VERSION ""

NS_ :

BS_:

BU_: External_Tool IPMA_ADAS SODRR SODRL

BO_ 776 RL_Detection_057_063: 64 SODRL
 SG_ RL_CAN_DET_ELEVATION_057 : 63|7@0+ (0.157449,-9.99812) [-9.99812|9.997903] "deg"  IPMA_ADAS
 SG_ RL_CAN_DET_CONFID_AZIMUTH_057 : 33|2@0+ (1,0) [0|3] ""  IPMA_ADAS
 SG_ RL_CAN_DET_SUPER_RES_TARGET_057 : 56|1@0+ (1,0) [0|1] ""  IPMA_ADAS
 SG_ RL_CAN_DET_CONFID_ELEVATION_057 : 49|1@0+ (1,0) [0|1] ""  IPMA_ADAS
 SG_ RL_CAN_DET_HOST_VEH_CLUTTER_057 : 48|1@0+ (1,0) [0|1] ""  IPMA_ADAS
 SG_ RL_CAN_DET_VALID_LEVEL_057 : 0|1@0+ (1,0) [0|1] ""  IPMA_ADAS
 SG_ RL_CAN_DET_AZIMUTH_057 : 47|14@0+ (0.021967,-180) [-180|179.885361] "deg"  IPMA_ADAS
 SG_ RL_CAN_DET_RANGE_057 : 31|14@0+ (0.015625,0) [0|255.984375] "m"  IPMA_ADAS
 SG_ RL_CAN_DET_RANGE_RATE_057 : 15|14@0+ (0.015625,-128) [-128|127.984375] "m/s"  IPMA_ADAS
 SG_ RL_CAN_DET_AMPLITUDE_057 : 7|7@0+ (1,-64) [-64|63] "dBsm"  IPMA_ADAS
 SG_ RL_CAN_SCAN_INDEX_2LSB_057 : 17|2@0+ (1,0) [0|3] ""  IPMA_ADAS
 SG_ RL_DET_MC_009 : 451|4@0+ (1,0) [0|0] ""  IPMA_ADAS
 SG_ RL_DET_CRC_009 : 463|16@0+ (1,0) [0|0] ""  IPMA_ADAS
 SG_ RL_CAN_DET_ELEVATION_063 : 447|7@0+ (0.157449,-9.99812) [-9.99812|9.997903] "deg"  IPMA_ADAS
 SG_ RL_CAN_DET_SUPER_RES_TARGET_063 : 440|1@0+ (1,0) [0|1] ""  IPMA_ADAS
 SG_ RL_CAN_DET_AZIMUTH_063 : 431|14@0+ (0.021967,-180) [-180|179.885361] "deg"  IPMA_ADAS
 SG_ RL_CAN_DET_CONFID_ELEVATION_063 : 433|1@0+ (1,0) [0|1] ""  IPMA_ADAS
 SG_ RL_CAN_DET_HOST_VEH_CLUTTER_063 : 432|1@0+ (1,0) [0|1] ""  IPMA_ADAS
 SG_ RL_CAN_DET_RANGE_063 : 415|14@0+ (0.015625,0) [0|255.984375] "m"  IPMA_ADAS
 SG_ RL_CAN_DET_CONFID_AZIMUTH_063 : 417|2@0+ (1,0) [0|3] ""  IPMA_ADAS
 SG_ RL_CAN_DET_RANGE_RATE_063 : 399|14@0+ (0.015625,-128) [-128|127.984375] "m/s"  IPMA_ADAS
 SG_ RL_CAN_SCAN_INDEX_2LSB_063 : 401|2@0+ (1,0) [0|3] ""  IPMA_ADAS
 SG_ RL_CAN_DET_AMPLITUDE_063 : 391|7@0+ (1,-64) [-64|63] "dBsm"  IPMA_ADAS
 SG_ RL_CAN_DET_VALID_LEVEL_063 : 384|1@0+ (1,0) [0|1] ""  IPMA_ADAS
 SG_ RL_CAN_DET_ELEVATION_062 : 383|7@0+ (0.157449,-9.99812) [-9.99812|9.997903] "deg"  IPMA_ADAS
 SG_ RL_CAN_DET_SUPER_RES_TARGET_062 : 376|1@0+ (1,0) [0|1] ""  IPMA_ADAS
 SG_ RL_CAN_DET_AZIMUTH_062 : 367|14@0+ (0.021967,-180) [-180|179.885361] "deg"  IPMA_ADAS
 SG_ RL_CAN_DET_CONFID_ELEVATION_062 : 369|1@0+ (1,0) [0|1] ""  IPMA_ADAS
 SG_ RL_CAN_DET_HOST_VEH_CLUTTER_062 : 368|1@0+ (1,0) [0|1] ""  IPMA_ADAS
 SG_ RL_CAN_DET_RANGE_062 : 351|14@0+ (0.015625,0) [0|255.984375] "m"  IPMA_ADAS
 SG_ RL_CAN_DET_CONFID_AZIMUTH_062 : 353|2@0+ (1,0) [0|3] ""  IPMA_ADAS
 SG_ RL_CAN_DET_RANGE_RATE_062 : 335|14@0+ (0.015625,-128) [-128|127.984375] "m/s"  IPMA_ADAS
 SG_ RL_CAN_SCAN_INDEX_2LSB_062 : 337|2@0+ (1,0) [0|3] ""  IPMA_ADAS
 SG_ RL_CAN_DET_AMPLITUDE_062 : 327|7@0+ (1,-64) [-64|63] "dBsm"  IPMA_ADAS
 SG_ RL_CAN_DET_VALID_LEVEL_062 : 320|1@0+ (1,0) [0|1] ""  IPMA_ADAS
 SG_ RL_CAN_DET_ELEVATION_061 : 319|7@0+ (0.157449,-9.99812) [-9.99812|9.997903] "deg"  IPMA_ADAS
 SG_ RL_CAN_DET_SUPER_RES_TARGET_061 : 312|1@0+ (1,0) [0|1] ""  IPMA_ADAS
 SG_ RL_CAN_DET_AZIMUTH_061 : 303|14@0+ (0.021967,-180) [-180|179.885361] "deg"  IPMA_ADAS
 SG_ RL_CAN_DET_CONFID_ELEVATION_061 : 305|1@0+ (1,0) [0|1] ""  IPMA_ADAS
 SG_ RL_CAN_DET_HOST_VEH_CLUTTER_061 : 304|1@0+ (1,0) [0|1] ""  IPMA_ADAS
 SG_ RL_CAN_DET_RANGE_061 : 287|14@0+ (0.015625,0) [0|255.984375] "m"  IPMA_ADAS
 SG_ RL_CAN_DET_CONFID_AZIMUTH_061 : 289|2@0+ (1,0) [0|3] ""  IPMA_ADAS
 SG_ RL_CAN_DET_RANGE_RATE_061 : 271|14@0+ (0.015625,-128) [-128|127.984375] "m/s"  IPMA_ADAS
 SG_ RL_CAN_SCAN_INDEX_2LSB_061 : 273|2@0+ (1,0) [0|3] ""  IPMA_ADAS
 SG_ RL_CAN_DET_AMPLITUDE_061 : 263|7@0+ (1,-64) [-64|63] "dBsm"  IPMA_ADAS
 SG_ RL_CAN_DET_VALID_LEVEL_061 : 256|1@0+ (1,0) [0|1] ""  IPMA_ADAS
 SG_ RL_CAN_DET_ELEVATION_060 : 255|7@0+ (0.157449,-9.99812) [-9.99812|9.997903] "deg"  IPMA_ADAS
 SG_ RL_CAN_DET_SUPER_RES_TARGET_060 : 248|1@0+ (1,0) [0|1] ""  IPMA_ADAS
 SG_ RL_CAN_DET_AZIMUTH_060 : 239|14@0+ (0.021967,-180) [-180|179.885361] "deg"  IPMA_ADAS
 SG_ RL_CAN_DET_CONFID_ELEVATION_060 : 241|1@0+ (1,0) [0|1] ""  IPMA_ADAS
 SG_ RL_CAN_DET_HOST_VEH_CLUTTER_060 : 240|1@0+ (1,0) [0|1] ""  IPMA_ADAS
 SG_ RL_CAN_DET_RANGE_060 : 223|14@0+ (0.015625,0) [0|255.984375] "m"  IPMA_ADAS
 SG_ RL_CAN_DET_CONFID_AZIMUTH_060 : 225|2@0+ (1,0) [0|3] ""  IPMA_ADAS
 SG_ RL_CAN_DET_RANGE_RATE_060 : 207|14@0+ (0.015625,-128) [-128|127.984375] "m/s"  IPMA_ADAS
 SG_ RL_CAN_SCAN_INDEX_2LSB_060 : 209|2@0+ (1,0) [0|3] ""  IPMA_ADAS
 SG_ RL_CAN_DET_AMPLITUDE_060 : 199|7@0+ (1,-64) [-64|63] "dBsm"  IPMA_ADAS
 SG_ RL_CAN_DET_VALID_LEVEL_060 : 192|1@0+ (1,0) [0|1] ""  IPMA_ADAS
 SG_ RL_CAN_DET_ELEVATION_059 : 191|7@0+ (0.157449,-9.99812) [-9.99812|9.997903] "deg"  IPMA_ADAS
 SG_ RL_CAN_DET_SUPER_RES_TARGET_059 : 184|1@0+ (1,0) [0|1] ""  IPMA_ADAS
 SG_ RL_CAN_DET_AZIMUTH_059 : 175|14@0+ (0.021967,-180) [-180|179.885361] "deg"  IPMA_ADAS
 SG_ RL_CAN_DET_CONFID_ELEVATION_059 : 177|1@0+ (1,0) [0|1] ""  IPMA_ADAS
 SG_ RL_CAN_DET_HOST_VEH_CLUTTER_059 : 176|1@0+ (1,0) [0|1] ""  IPMA_ADAS
 SG_ RL_CAN_DET_RANGE_059 : 159|14@0+ (0.015625,0) [0|255.984375] "m"  IPMA_ADAS
 SG_ RL_CAN_DET_CONFID_AZIMUTH_059 : 161|2@0+ (1,0) [0|3] ""  IPMA_ADAS
 SG_ RL_CAN_DET_RANGE_RATE_059 : 143|14@0+ (0.015625,-128) [-128|127.984375] "m/s"  IPMA_ADAS
 SG_ RL_CAN_SCAN_INDEX_2LSB_059 : 145|2@0+ (1,0) [0|3] ""  IPMA_ADAS
 SG_ RL_CAN_DET_AMPLITUDE_059 : 135|7@0+ (1,-64) [-64|63] "dBsm"  IPMA_ADAS
 SG_ RL_CAN_DET_VALID_LEVEL_059 : 128|1@0+ (1,0) [0|1] ""  IPMA_ADAS
 SG_ RL_CAN_DET_ELEVATION_058 : 127|7@0+ (0.157449,-9.99812) [-9.99812|9.997903] "deg"  IPMA_ADAS
 SG_ RL_CAN_DET_SUPER_RES_TARGET_058 : 120|1@0+ (1,0) [0|1] ""  IPMA_ADAS
 SG_ RL_CAN_DET_AZIMUTH_058 : 111|14@0+ (0.021967,-180) [-180|179.885361] "deg"  IPMA_ADAS
 SG_ RL_CAN_DET_CONFID_ELEVATION_058 : 113|1@0+ (1,0) [0|1] ""  IPMA_ADAS
 SG_ RL_CAN_DET_HOST_VEH_CLUTTER_058 : 112|1@0+ (1,0) [0|1] ""  IPMA_ADAS
 SG_ RL_CAN_DET_RANGE_058 : 95|14@0+ (0.015625,0) [0|255.984375] "m"  IPMA_ADAS
 SG_ RL_CAN_DET_CONFID_AZIMUTH_058 : 97|2@0+ (1,0) [0|3] ""  IPMA_ADAS
 SG_ RL_CAN_DET_RANGE_RATE_058 : 79|14@0+ (0.015625,-128) [-128|127.984375] "m/s"  IPMA_ADAS
 SG_ RL_CAN_SCAN_INDEX_2LSB_058 : 81|2@0+ (1,0) [0|3] ""  IPMA_ADAS
 SG_ RL_CAN_DET_AMPLITUDE_058 : 71|7@0+ (1,-64) [-64|63] "dBsm"  IPMA_ADAS
 SG_ RL_CAN_DET_VALID_LEVEL_058 : 64|1@0+ (1,0) [0|1] ""  IPMA_ADAS

BO_ 777 RL_Detection_064: 12 SODRL
 SG_ RL_DET_MC_010 : 67|4@0+ (1,0) [0|0] ""  IPMA_ADAS
 SG_ RL_DET_CRC_010 : 79|16@0+ (1,0) [0|0] ""  IPMA_ADAS
 SG_ RL_CAN_DET_ELEVATION_064 : 63|7@0+ (0.157449,-9.99812) [-9.99812|9.997903] "deg"  IPMA_ADAS
 SG_ RL_CAN_DET_CONFID_AZIMUTH_064 : 33|2@0+ (1,0) [0|3] ""  IPMA_ADAS
 SG_ RL_CAN_DET_SUPER_RES_TARGET_064 : 56|1@0+ (1,0) [0|1] ""  IPMA_ADAS
 SG_ RL_CAN_DET_CONFID_ELEVATION_064 : 49|1@0+ (1,0) [0|1] ""  IPMA_ADAS
 SG_ RL_CAN_DET_HOST_VEH_CLUTTER_064 : 48|1@0+ (1,0) [0|1] ""  IPMA_ADAS
 SG_ RL_CAN_DET_VALID_LEVEL_064 : 0|1@0+ (1,0) [0|1] ""  IPMA_ADAS
 SG_ RL_CAN_DET_AZIMUTH_064 : 47|14@0+ (0.021967,-180) [-180|179.885361] "deg"  IPMA_ADAS
 SG_ RL_CAN_DET_RANGE_064 : 31|14@0+ (0.015625,0) [0|255.984375] "m"  IPMA_ADAS
 SG_ RL_CAN_DET_RANGE_RATE_064 : 15|14@0+ (0.015625,-128) [-128|127.984375] "m/s"  IPMA_ADAS
 SG_ RL_CAN_DET_AMPLITUDE_064 : 7|7@0+ (1,-64) [-64|63] "dBsm"  IPMA_ADAS
 SG_ RL_CAN_SCAN_INDEX_2LSB_064 : 17|2@0+ (1,0) [0|3] ""  IPMA_ADAS

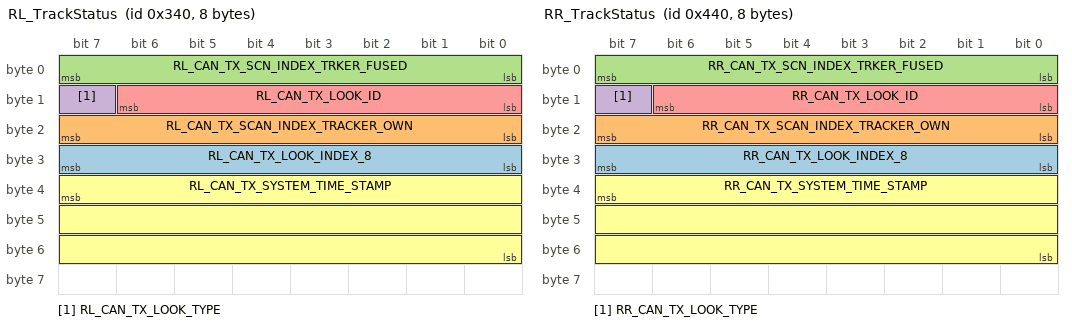
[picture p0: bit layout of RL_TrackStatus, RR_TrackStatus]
BO_ 832 RL_TrackStatus: 8 SODRL
 SG_ RL_CAN_TX_LOOK_INDEX_8 : 31|8@0+ (1,0) [0|0] ""  IPMA_ADAS
 SG_ RL_CAN_TX_SCAN_INDEX_TRACKER_OWN : 23|8@0+ (1,0) [0|0] ""  IPMA_ADAS
 SG_ RL_CAN_TX_SCN_INDEX_TRKER_FUSED : 7|8@0+ (1,0) [0|0] ""  IPMA_ADAS
 SG_ RL_CAN_TX_LOOK_TYPE : 15|1@0+ (1,0) [0|0] ""  IPMA_ADAS
 SG_ RL_CAN_TX_LOOK_ID : 14|7@0+ (1,0) [0|0] ""  IPMA_ADAS
 SG_ RL_CAN_TX_SYSTEM_TIME_STAMP : 39|24@0+ (1,0) [0|16777215] "us"  IPMA_ADAS

BO_ 1024 RR_Detection_001_007: 64 SODRR
 SG_ RR_DET_MC_001 : 451|4@0+ (1,0) [0|0] ""  IPMA_ADAS
 SG_ RR_DET_CRC_001 : 463|16@0+ (1,0) [0|0] ""  IPMA_ADAS
 SG_ RR_CAN_DET_ELEVATION_007 : 447|7@0+ (0.157449,-9.99812) [-9.99812|9.997903] "deg"  IPMA_ADAS
 SG_ RR_CAN_DET_SUPER_RES_TARGET_007 : 440|1@0+ (1,0) [0|1] ""  IPMA_ADAS
 SG_ RR_CAN_DET_AZIMUTH_007 : 431|14@0+ (0.021967,-180) [-180|179.885361] "deg"  IPMA_ADAS
 SG_ RR_CAN_DET_CONFID_ELEVATION_007 : 433|1@0+ (1,0) [0|1] ""  IPMA_ADAS
 SG_ RR_CAN_DET_HOST_VEH_CLUTTER_007 : 432|1@0+ (1,0) [0|1] ""  IPMA_ADAS
 SG_ RR_CAN_DET_RANGE_007 : 415|14@0+ (0.015625,0) [0|255.984375] "m"  IPMA_ADAS
 SG_ RR_CAN_DET_CONFID_AZIMUTH_007 : 417|2@0+ (1,0) [0|3] ""  IPMA_ADAS
 SG_ RR_CAN_DET_RANGE_RATE_007 : 399|14@0+ (0.015625,-128) [-128|127.984375] "m/s"  IPMA_ADAS
 SG_ RR_CAN_SCAN_INDEX_2LSB_007 : 401|2@0+ (1,0) [0|3] ""  IPMA_ADAS
 SG_ RR_CAN_DET_AMPLITUDE_007 : 391|7@0+ (1,-64) [-64|63] "dBsm"  IPMA_ADAS
 SG_ RR_CAN_DET_VALID_LEVEL_007 : 384|1@0+ (1,0) [0|1] ""  IPMA_ADAS
 SG_ RR_CAN_DET_ELEVATION_006 : 383|7@0+ (0.157449,-9.99812) [-9.99812|9.997903] "deg"  IPMA_ADAS
 SG_ RR_CAN_DET_SUPER_RES_TARGET_006 : 376|1@0+ (1,0) [0|1] ""  IPMA_ADAS
 SG_ RR_CAN_DET_AZIMUTH_006 : 367|14@0+ (0.021967,-180) [-180|179.885361] "deg"  IPMA_ADAS
 SG_ RR_CAN_DET_CONFID_ELEVATION_006 : 369|1@0+ (1,0) [0|1] ""  IPMA_ADAS
 SG_ RR_CAN_DET_HOST_VEH_CLUTTER_006 : 368|1@0+ (1,0) [0|1] ""  IPMA_ADAS
 SG_ RR_CAN_DET_RANGE_006 : 351|14@0+ (0.015625,0) [0|255.984375] "m"  IPMA_ADAS
 SG_ RR_CAN_DET_CONFID_AZIMUTH_006 : 353|2@0+ (1,0) [0|3] ""  IPMA_ADAS
 SG_ RR_CAN_DET_RANGE_RATE_006 : 335|14@0+ (0.015625,-128) [-128|127.984375] "m/s"  IPMA_ADAS
 SG_ RR_CAN_SCAN_INDEX_2LSB_006 : 337|2@0+ (1,0) [0|3] ""  IPMA_ADAS
 SG_ RR_CAN_DET_AMPLITUDE_006 : 327|7@0+ (1,-64) [-64|63] "dBsm"  IPMA_ADAS
 SG_ RR_CAN_DET_VALID_LEVEL_006 : 320|1@0+ (1,0) [0|1] ""  IPMA_ADAS
 SG_ RR_CAN_DET_ELEVATION_005 : 319|7@0+ (0.157449,-9.99812) [-9.99812|9.997903] "deg"  IPMA_ADAS
 SG_ RR_CAN_DET_SUPER_RES_TARGET_005 : 312|1@0+ (1,0) [0|1] ""  IPMA_ADAS
 SG_ RR_CAN_DET_AZIMUTH_005 : 303|14@0+ (0.021967,-180) [-180|179.885361] "deg"  IPMA_ADAS
 SG_ RR_CAN_DET_CONFID_ELEVATION_005 : 305|1@0+ (1,0) [0|1] ""  IPMA_ADAS
 SG_ RR_CAN_DET_HOST_VEH_CLUTTER_005 : 304|1@0+ (1,0) [0|1] ""  IPMA_ADAS
 SG_ RR_CAN_DET_RANGE_005 : 287|14@0+ (0.015625,0) [0|255.984375] "m"  IPMA_ADAS
 SG_ RR_CAN_DET_CONFID_AZIMUTH_005 : 289|2@0+ (1,0) [0|3] ""  IPMA_ADAS
 SG_ RR_CAN_DET_RANGE_RATE_005 : 271|14@0+ (0.015625,-128) [-128|127.984375] "m/s"  IPMA_ADAS
 SG_ RR_CAN_SCAN_INDEX_2LSB_005 : 273|2@0+ (1,0) [0|3] ""  IPMA_ADAS
 SG_ RR_CAN_DET_AMPLITUDE_005 : 263|7@0+ (1,-64) [-64|63] "dBsm"  IPMA_ADAS
 SG_ RR_CAN_DET_VALID_LEVEL_005 : 256|1@0+ (1,0) [0|1] ""  IPMA_ADAS
 SG_ RR_CAN_DET_ELEVATION_004 : 255|7@0+ (0.157449,-9.99812) [-9.99812|9.997903] "deg"  IPMA_ADAS
 SG_ RR_CAN_DET_SUPER_RES_TARGET_004 : 248|1@0+ (1,0) [0|1] ""  IPMA_ADAS
 SG_ RR_CAN_DET_AZIMUTH_004 : 239|14@0+ (0.021967,-180) [-180|179.885361] "deg"  IPMA_ADAS
 SG_ RR_CAN_DET_CONFID_ELEVATION_004 : 241|1@0+ (1,0) [0|1] ""  IPMA_ADAS
 SG_ RR_CAN_DET_HOST_VEH_CLUTTER_004 : 240|1@0+ (1,0) [0|1] ""  IPMA_ADAS
 SG_ RR_CAN_DET_RANGE_004 : 223|14@0+ (0.015625,0) [0|255.984375] "m"  IPMA_ADAS
 SG_ RR_CAN_DET_CONFID_AZIMUTH_004 : 225|2@0+ (1,0) [0|3] ""  IPMA_ADAS
 SG_ RR_CAN_DET_RANGE_RATE_004 : 207|14@0+ (0.015625,-128) [-128|127.984375] "m/s"  IPMA_ADAS
 SG_ RR_CAN_SCAN_INDEX_2LSB_004 : 209|2@0+ (1,0) [0|3] ""  IPMA_ADAS
 SG_ RR_CAN_DET_AMPLITUDE_004 : 199|7@0+ (1,-64) [-64|63] "dBsm"  IPMA_ADAS
 SG_ RR_CAN_DET_VALID_LEVEL_004 : 192|1@0+ (1,0) [0|1] ""  IPMA_ADAS
 SG_ RR_CAN_DET_ELEVATION_003 : 191|7@0+ (0.157449,-9.99812) [-9.99812|9.997903] "deg"  IPMA_ADAS
 SG_ RR_CAN_DET_SUPER_RES_TARGET_003 : 184|1@0+ (1,0) [0|1] ""  IPMA_ADAS
 SG_ RR_CAN_DET_AZIMUTH_003 : 175|14@0+ (0.021967,-180) [-180|179.885361] "deg"  IPMA_ADAS
 SG_ RR_CAN_DET_CONFID_ELEVATION_003 : 177|1@0+ (1,0) [0|1] ""  IPMA_ADAS
 SG_ RR_CAN_DET_HOST_VEH_CLUTTER_003 : 176|1@0+ (1,0) [0|1] ""  IPMA_ADAS
 SG_ RR_CAN_DET_RANGE_003 : 159|14@0+ (0.015625,0) [0|255.984375] "m"  IPMA_ADAS
 SG_ RR_CAN_DET_CONFID_AZIMUTH_003 : 161|2@0+ (1,0) [0|3] ""  IPMA_ADAS
 SG_ RR_CAN_DET_RANGE_RATE_003 : 143|14@0+ (0.015625,-128) [-128|127.984375] "m/s"  IPMA_ADAS
 SG_ RR_CAN_SCAN_INDEX_2LSB_003 : 145|2@0+ (1,0) [0|3] ""  IPMA_ADAS
 SG_ RR_CAN_DET_AMPLITUDE_003 : 135|7@0+ (1,-64) [-64|63] "dBsm"  IPMA_ADAS
 SG_ RR_CAN_DET_VALID_LEVEL_003 : 128|1@0+ (1,0) [0|1] ""  IPMA_ADAS
 SG_ RR_CAN_DET_ELEVATION_002 : 127|7@0+ (0.157449,-9.99812) [-9.99812|9.997903] "deg"  IPMA_ADAS
 SG_ RR_CAN_DET_SUPER_RES_TARGET_002 : 120|1@0+ (1,0) [0|1] ""  IPMA_ADAS
 SG_ RR_CAN_DET_AZIMUTH_002 : 111|14@0+ (0.021967,-180) [-180|179.885361] "deg"  IPMA_ADAS
 SG_ RR_CAN_DET_CONFID_ELEVATION_002 : 113|1@0+ (1,0) [0|1] ""  IPMA_ADAS
 SG_ RR_CAN_DET_HOST_VEH_CLUTTER_002 : 112|1@0+ (1,0) [0|1] ""  IPMA_ADAS
 SG_ RR_CAN_DET_RANGE_002 : 95|14@0+ (0.015625,0) [0|255.984375] "m"  IPMA_ADAS
 SG_ RR_CAN_DET_CONFID_AZIMUTH_002 : 97|2@0+ (1,0) [0|3] ""  IPMA_ADAS
 SG_ RR_CAN_DET_RANGE_RATE_002 : 79|14@0+ (0.015625,-128) [-128|127.984375] "m/s"  IPMA_ADAS
 SG_ RR_CAN_SCAN_INDEX_2LSB_002 : 81|2@0+ (1,0) [0|3] ""  IPMA_ADAS
 SG_ RR_CAN_DET_AMPLITUDE_002 : 71|7@0+ (1,-64) [-64|63] "dBsm"  IPMA_ADAS
 SG_ RR_CAN_DET_VALID_LEVEL_002 : 64|1@0+ (1,0) [0|1] ""  IPMA_ADAS
 SG_ RR_CAN_DET_ELEVATION_001 : 63|7@0+ (0.157449,-9.99812) [-9.99812|9.997903] "deg"  IPMA_ADAS
 SG_ RR_CAN_DET_CONFID_AZIMUTH_001 : 33|2@0+ (1,0) [0|3] ""  IPMA_ADAS
 SG_ RR_CAN_DET_SUPER_RES_TARGET_001 : 56|1@0+ (1,0) [0|1] ""  IPMA_ADAS
 SG_ RR_CAN_DET_CONFID_ELEVATION_001 : 49|1@0+ (1,0) [0|1] ""  IPMA_ADAS
 SG_ RR_CAN_DET_HOST_VEH_CLUTTER_001 : 48|1@0+ (1,0) [0|1] ""  IPMA_ADAS
 SG_ RR_CAN_DET_VALID_LEVEL_001 : 0|1@0+ (1,0) [0|1] ""  IPMA_ADAS
 SG_ RR_CAN_DET_AZIMUTH_001 : 47|14@0+ (0.021967,-180) [-180|179.885361] "deg"  IPMA_ADAS
 SG_ RR_CAN_DET_RANGE_001 : 31|14@0+ (0.015625,0) [0|255.984375] "m"  IPMA_ADAS
 SG_ RR_CAN_DET_RANGE_RATE_001 : 15|14@0+ (0.015625,-128) [-128|127.984375] "m/s"  IPMA_ADAS
 SG_ RR_CAN_DET_AMPLITUDE_001 : 7|7@0+ (1,-64) [-64|63] "dBsm"  IPMA_ADAS
 SG_ RR_CAN_SCAN_INDEX_2LSB_001 : 17|2@0+ (1,0) [0|3] ""  IPMA_ADAS

BO_ 1025 RR_Detection_008_014: 64 SODRR
 SG_ RR_CAN_DET_ELEVATION_008 : 63|7@0+ (0.157449,-9.99812) [-9.99812|9.997903] "deg"  IPMA_ADAS
 SG_ RR_CAN_DET_CONFID_AZIMUTH_008 : 33|2@0+ (1,0) [0|3] ""  IPMA_ADAS
 SG_ RR_CAN_DET_SUPER_RES_TARGET_008 : 56|1@0+ (1,0) [0|1] ""  IPMA_ADAS
 SG_ RR_CAN_DET_CONFID_ELEVATION_008 : 49|1@0+ (1,0) [0|1] ""  IPMA_ADAS
 SG_ RR_CAN_DET_HOST_VEH_CLUTTER_008 : 48|1@0+ (1,0) [0|1] ""  IPMA_ADAS
 SG_ RR_CAN_DET_VALID_LEVEL_008 : 0|1@0+ (1,0) [0|1] ""  IPMA_ADAS
 SG_ RR_CAN_DET_AZIMUTH_008 : 47|14@0+ (0.021967,-180) [-180|179.885361] "deg"  IPMA_ADAS
 SG_ RR_CAN_DET_RANGE_008 : 31|14@0+ (0.015625,0) [0|255.984375] "m"  IPMA_ADAS
 SG_ RR_CAN_DET_RANGE_RATE_008 : 15|14@0+ (0.015625,-128) [-128|127.984375] "m/s"  IPMA_ADAS
 SG_ RR_CAN_DET_AMPLITUDE_008 : 7|7@0+ (1,-64) [-64|63] "dBsm"  IPMA_ADAS
 SG_ RR_CAN_SCAN_INDEX_2LSB_008 : 17|2@0+ (1,0) [0|3] ""  IPMA_ADAS
 SG_ RR_DET_MC_002 : 451|4@0+ (1,0) [0|0] ""  IPMA_ADAS
 SG_ RR_DET_CRC_002 : 463|16@0+ (1,0) [0|0] ""  IPMA_ADAS
 SG_ RR_CAN_DET_ELEVATION_014 : 447|7@0+ (0.157449,-9.99812) [-9.99812|9.997903] "deg"  IPMA_ADAS
 SG_ RR_CAN_DET_SUPER_RES_TARGET_014 : 440|1@0+ (1,0) [0|1] ""  IPMA_ADAS
 SG_ RR_CAN_DET_AZIMUTH_014 : 431|14@0+ (0.021967,-180) [-180|179.885361] "deg"  IPMA_ADAS
 SG_ RR_CAN_DET_CONFID_ELEVATION_014 : 433|1@0+ (1,0) [0|1] ""  IPMA_ADAS
 SG_ RR_CAN_DET_HOST_VEH_CLUTTER_014 : 432|1@0+ (1,0) [0|1] ""  IPMA_ADAS
 SG_ RR_CAN_DET_RANGE_014 : 415|14@0+ (0.015625,0) [0|255.984375] "m"  IPMA_ADAS
 SG_ RR_CAN_DET_CONFID_AZIMUTH_014 : 417|2@0+ (1,0) [0|3] ""  IPMA_ADAS
 SG_ RR_CAN_DET_RANGE_RATE_014 : 399|14@0+ (0.015625,-128) [-128|127.984375] "m/s"  IPMA_ADAS
 SG_ RR_CAN_SCAN_INDEX_2LSB_014 : 401|2@0+ (1,0) [0|3] ""  IPMA_ADAS
 SG_ RR_CAN_DET_AMPLITUDE_014 : 391|7@0+ (1,-64) [-64|63] "dBsm"  IPMA_ADAS
 SG_ RR_CAN_DET_VALID_LEVEL_014 : 384|1@0+ (1,0) [0|1] ""  IPMA_ADAS
 SG_ RR_CAN_DET_ELEVATION_013 : 383|7@0+ (0.157449,-9.99812) [-9.99812|9.997903] "deg"  IPMA_ADAS
 SG_ RR_CAN_DET_SUPER_RES_TARGET_013 : 376|1@0+ (1,0) [0|1] ""  IPMA_ADAS
 SG_ RR_CAN_DET_AZIMUTH_013 : 367|14@0+ (0.021967,-180) [-180|179.885361] "deg"  IPMA_ADAS
 SG_ RR_CAN_DET_CONFID_ELEVATION_013 : 369|1@0+ (1,0) [0|1] ""  IPMA_ADAS
 SG_ RR_CAN_DET_HOST_VEH_CLUTTER_013 : 368|1@0+ (1,0) [0|1] ""  IPMA_ADAS
 SG_ RR_CAN_DET_RANGE_013 : 351|14@0+ (0.015625,0) [0|255.984375] "m"  IPMA_ADAS
 SG_ RR_CAN_DET_CONFID_AZIMUTH_013 : 353|2@0+ (1,0) [0|3] ""  IPMA_ADAS
 SG_ RR_CAN_DET_RANGE_RATE_013 : 335|14@0+ (0.015625,-128) [-128|127.984375] "m/s"  IPMA_ADAS
 SG_ RR_CAN_SCAN_INDEX_2LSB_013 : 337|2@0+ (1,0) [0|3] ""  IPMA_ADAS
 SG_ RR_CAN_DET_AMPLITUDE_013 : 327|7@0+ (1,-64) [-64|63] "dBsm"  IPMA_ADAS
 SG_ RR_CAN_DET_VALID_LEVEL_013 : 320|1@0+ (1,0) [0|1] ""  IPMA_ADAS
 SG_ RR_CAN_DET_ELEVATION_012 : 319|7@0+ (0.157449,-9.99812) [-9.99812|9.997903] "deg"  IPMA_ADAS
 SG_ RR_CAN_DET_SUPER_RES_TARGET_012 : 312|1@0+ (1,0) [0|1] ""  IPMA_ADAS
 SG_ RR_CAN_DET_AZIMUTH_012 : 303|14@0+ (0.021967,-180) [-180|179.885361] "deg"  IPMA_ADAS
 SG_ RR_CAN_DET_CONFID_ELEVATION_012 : 305|1@0+ (1,0) [0|1] ""  IPMA_ADAS
 SG_ RR_CAN_DET_HOST_VEH_CLUTTER_012 : 304|1@0+ (1,0) [0|1] ""  IPMA_ADAS
 SG_ RR_CAN_DET_RANGE_012 : 287|14@0+ (0.015625,0) [0|255.984375] "m"  IPMA_ADAS
 SG_ RR_CAN_DET_CONFID_AZIMUTH_012 : 289|2@0+ (1,0) [0|3] ""  IPMA_ADAS
 SG_ RR_CAN_DET_RANGE_RATE_012 : 271|14@0+ (0.015625,-128) [-128|127.984375] "m/s"  IPMA_ADAS
 SG_ RR_CAN_SCAN_INDEX_2LSB_012 : 273|2@0+ (1,0) [0|3] ""  IPMA_ADAS
 SG_ RR_CAN_DET_AMPLITUDE_012 : 263|7@0+ (1,-64) [-64|63] "dBsm"  IPMA_ADAS
 SG_ RR_CAN_DET_VALID_LEVEL_012 : 256|1@0+ (1,0) [0|1] ""  IPMA_ADAS
 SG_ RR_CAN_DET_ELEVATION_011 : 255|7@0+ (0.157449,-9.99812) [-9.99812|9.997903] "deg"  IPMA_ADAS
 SG_ RR_CAN_DET_SUPER_RES_TARGET_011 : 248|1@0+ (1,0) [0|1] ""  IPMA_ADAS
 SG_ RR_CAN_DET_AZIMUTH_011 : 239|14@0+ (0.021967,-180) [-180|179.885361] "deg"  IPMA_ADAS
 SG_ RR_CAN_DET_CONFID_ELEVATION_011 : 241|1@0+ (1,0) [0|1] ""  IPMA_ADAS
 SG_ RR_CAN_DET_HOST_VEH_CLUTTER_011 : 240|1@0+ (1,0) [0|1] ""  IPMA_ADAS
 SG_ RR_CAN_DET_RANGE_011 : 223|14@0+ (0.015625,0) [0|255.984375] "m"  IPMA_ADAS
 SG_ RR_CAN_DET_CONFID_AZIMUTH_011 : 225|2@0+ (1,0) [0|3] ""  IPMA_ADAS
 SG_ RR_CAN_DET_RANGE_RATE_011 : 207|14@0+ (0.015625,-128) [-128|127.984375] "m/s"  IPMA_ADAS
 SG_ RR_CAN_SCAN_INDEX_2LSB_011 : 209|2@0+ (1,0) [0|3] ""  IPMA_ADAS
 SG_ RR_CAN_DET_AMPLITUDE_011 : 199|7@0+ (1,-64) [-64|63] "dBsm"  IPMA_ADAS
 SG_ RR_CAN_DET_VALID_LEVEL_011 : 192|1@0+ (1,0) [0|1] ""  IPMA_ADAS
 SG_ RR_CAN_DET_ELEVATION_010 : 191|7@0+ (0.157449,-9.99812) [-9.99812|9.997903] "deg"  IPMA_ADAS
 SG_ RR_CAN_DET_SUPER_RES_TARGET_010 : 184|1@0+ (1,0) [0|1] ""  IPMA_ADAS
 SG_ RR_CAN_DET_AZIMUTH_010 : 175|14@0+ (0.021967,-180) [-180|179.885361] "deg"  IPMA_ADAS
 SG_ RR_CAN_DET_CONFID_ELEVATION_010 : 177|1@0+ (1,0) [0|1] ""  IPMA_ADAS
 SG_ RR_CAN_DET_HOST_VEH_CLUTTER_010 : 176|1@0+ (1,0) [0|1] ""  IPMA_ADAS
 SG_ RR_CAN_DET_RANGE_010 : 159|14@0+ (0.015625,0) [0|255.984375] "m"  IPMA_ADAS
 SG_ RR_CAN_DET_CONFID_AZIMUTH_010 : 161|2@0+ (1,0) [0|3] ""  IPMA_ADAS
 SG_ RR_CAN_DET_RANGE_RATE_010 : 143|14@0+ (0.015625,-128) [-128|127.984375] "m/s"  IPMA_ADAS
 SG_ RR_CAN_SCAN_INDEX_2LSB_010 : 145|2@0+ (1,0) [0|3] ""  IPMA_ADAS
 SG_ RR_CAN_DET_AMPLITUDE_010 : 135|7@0+ (1,-64) [-64|63] "dBsm"  IPMA_ADAS
 SG_ RR_CAN_DET_VALID_LEVEL_010 : 128|1@0+ (1,0) [0|1] ""  IPMA_ADAS
 SG_ RR_CAN_DET_ELEVATION_009 : 127|7@0+ (0.157449,-9.99812) [-9.99812|9.997903] "deg"  IPMA_ADAS
 SG_ RR_CAN_DET_SUPER_RES_TARGET_009 : 120|1@0+ (1,0) [0|1] ""  IPMA_ADAS
 SG_ RR_CAN_DET_AZIMUTH_009 : 111|14@0+ (0.021967,-180) [-180|179.885361] "deg"  IPMA_ADAS
 SG_ RR_CAN_DET_CONFID_ELEVATION_009 : 113|1@0+ (1,0) [0|1] ""  IPMA_ADAS
 SG_ RR_CAN_DET_HOST_VEH_CLUTTER_009 : 112|1@0+ (1,0) [0|1] ""  IPMA_ADAS
 SG_ RR_CAN_DET_RANGE_009 : 95|14@0+ (0.015625,0) [0|255.984375] "m"  IPMA_ADAS
 SG_ RR_CAN_DET_CONFID_AZIMUTH_009 : 97|2@0+ (1,0) [0|3] ""  IPMA_ADAS
 SG_ RR_CAN_DET_RANGE_RATE_009 : 79|14@0+ (0.015625,-128) [-128|127.984375] "m/s"  IPMA_ADAS
 SG_ RR_CAN_SCAN_INDEX_2LSB_009 : 81|2@0+ (1,0) [0|3] ""  IPMA_ADAS
 SG_ RR_CAN_DET_AMPLITUDE_009 : 71|7@0+ (1,-64) [-64|63] "dBsm"  IPMA_ADAS
 SG_ RR_CAN_DET_VALID_LEVEL_009 : 64|1@0+ (1,0) [0|1] ""  IPMA_ADAS

BO_ 1026 RR_Detection_015_021: 64 SODRR
 SG_ RR_CAN_DET_ELEVATION_015 : 63|7@0+ (0.157449,-9.99812) [-9.99812|9.997903] "deg"  IPMA_ADAS
 SG_ RR_CAN_DET_CONFID_AZIMUTH_015 : 33|2@0+ (1,0) [0|3] ""  IPMA_ADAS
 SG_ RR_CAN_DET_SUPER_RES_TARGET_015 : 56|1@0+ (1,0) [0|1] ""  IPMA_ADAS
 SG_ RR_CAN_DET_CONFID_ELEVATION_015 : 49|1@0+ (1,0) [0|1] ""  IPMA_ADAS
 SG_ RR_CAN_DET_HOST_VEH_CLUTTER_015 : 48|1@0+ (1,0) [0|1] ""  IPMA_ADAS
 SG_ RR_CAN_DET_VALID_LEVEL_015 : 0|1@0+ (1,0) [0|1] ""  IPMA_ADAS
 SG_ RR_CAN_DET_AZIMUTH_015 : 47|14@0+ (0.021967,-180) [-180|179.885361] "deg"  IPMA_ADAS
 SG_ RR_CAN_DET_RANGE_015 : 31|14@0+ (0.015625,0) [0|255.984375] "m"  IPMA_ADAS
 SG_ RR_CAN_DET_RANGE_RATE_015 : 15|14@0+ (0.015625,-128) [-128|127.984375] "m/s"  IPMA_ADAS
 SG_ RR_CAN_DET_AMPLITUDE_015 : 7|7@0+ (1,-64) [-64|63] "dBsm"  IPMA_ADAS
 SG_ RR_CAN_SCAN_INDEX_2LSB_015 : 17|2@0+ (1,0) [0|3] ""  IPMA_ADAS
 SG_ RR_DET_MC_003 : 451|4@0+ (1,0) [0|0] ""  IPMA_ADAS
 SG_ RR_DET_CRC_003 : 463|16@0+ (1,0) [0|0] ""  IPMA_ADAS
 SG_ RR_CAN_DET_ELEVATION_021 : 447|7@0+ (0.157449,-9.99812) [-9.99812|9.997903] "deg"  IPMA_ADAS
 SG_ RR_CAN_DET_SUPER_RES_TARGET_021 : 440|1@0+ (1,0) [0|1] ""  IPMA_ADAS
 SG_ RR_CAN_DET_AZIMUTH_021 : 431|14@0+ (0.021967,-180) [-180|179.885361] "deg"  IPMA_ADAS
 SG_ RR_CAN_DET_CONFID_ELEVATION_021 : 433|1@0+ (1,0) [0|1] ""  IPMA_ADAS
 SG_ RR_CAN_DET_HOST_VEH_CLUTTER_021 : 432|1@0+ (1,0) [0|1] ""  IPMA_ADAS
 SG_ RR_CAN_DET_RANGE_021 : 415|14@0+ (0.015625,0) [0|255.984375] "m"  IPMA_ADAS
 SG_ RR_CAN_DET_CONFID_AZIMUTH_021 : 417|2@0+ (1,0) [0|3] ""  IPMA_ADAS
 SG_ RR_CAN_DET_RANGE_RATE_021 : 399|14@0+ (0.015625,-128) [-128|127.984375] "m/s"  IPMA_ADAS
 SG_ RR_CAN_SCAN_INDEX_2LSB_021 : 401|2@0+ (1,0) [0|3] ""  IPMA_ADAS
 SG_ RR_CAN_DET_AMPLITUDE_021 : 391|7@0+ (1,-64) [-64|63] "dBsm"  IPMA_ADAS
 SG_ RR_CAN_DET_VALID_LEVEL_021 : 384|1@0+ (1,0) [0|1] ""  IPMA_ADAS
 SG_ RR_CAN_DET_ELEVATION_020 : 383|7@0+ (0.157449,-9.99812) [-9.99812|9.997903] "deg"  IPMA_ADAS
 SG_ RR_CAN_DET_SUPER_RES_TARGET_020 : 376|1@0+ (1,0) [0|1] ""  IPMA_ADAS
 SG_ RR_CAN_DET_AZIMUTH_020 : 367|14@0+ (0.021967,-180) [-180|179.885361] "deg"  IPMA_ADAS
 SG_ RR_CAN_DET_CONFID_ELEVATION_020 : 369|1@0+ (1,0) [0|1] ""  IPMA_ADAS
 SG_ RR_CAN_DET_HOST_VEH_CLUTTER_020 : 368|1@0+ (1,0) [0|1] ""  IPMA_ADAS
 SG_ RR_CAN_DET_RANGE_020 : 351|14@0+ (0.015625,0) [0|255.984375] "m"  IPMA_ADAS
 SG_ RR_CAN_DET_CONFID_AZIMUTH_020 : 353|2@0+ (1,0) [0|3] ""  IPMA_ADAS
 SG_ RR_CAN_DET_RANGE_RATE_020 : 335|14@0+ (0.015625,-128) [-128|127.984375] "m/s"  IPMA_ADAS
 SG_ RR_CAN_SCAN_INDEX_2LSB_020 : 337|2@0+ (1,0) [0|3] ""  IPMA_ADAS
 SG_ RR_CAN_DET_AMPLITUDE_020 : 327|7@0+ (1,-64) [-64|63] "dBsm"  IPMA_ADAS
 SG_ RR_CAN_DET_VALID_LEVEL_020 : 320|1@0+ (1,0) [0|1] ""  IPMA_ADAS
 SG_ RR_CAN_DET_ELEVATION_019 : 319|7@0+ (0.157449,-9.99812) [-9.99812|9.997903] "deg"  IPMA_ADAS
 SG_ RR_CAN_DET_SUPER_RES_TARGET_019 : 312|1@0+ (1,0) [0|1] ""  IPMA_ADAS
 SG_ RR_CAN_DET_AZIMUTH_019 : 303|14@0+ (0.021967,-180) [-180|179.885361] "deg"  IPMA_ADAS
 SG_ RR_CAN_DET_CONFID_ELEVATION_019 : 305|1@0+ (1,0) [0|1] ""  IPMA_ADAS
 SG_ RR_CAN_DET_HOST_VEH_CLUTTER_019 : 304|1@0+ (1,0) [0|1] ""  IPMA_ADAS
 SG_ RR_CAN_DET_RANGE_019 : 287|14@0+ (0.015625,0) [0|255.984375] "m"  IPMA_ADAS
 SG_ RR_CAN_DET_CONFID_AZIMUTH_019 : 289|2@0+ (1,0) [0|3] ""  IPMA_ADAS
 SG_ RR_CAN_DET_RANGE_RATE_019 : 271|14@0+ (0.015625,-128) [-128|127.984375] "m/s"  IPMA_ADAS
 SG_ RR_CAN_SCAN_INDEX_2LSB_019 : 273|2@0+ (1,0) [0|3] ""  IPMA_ADAS
 SG_ RR_CAN_DET_AMPLITUDE_019 : 263|7@0+ (1,-64) [-64|63] "dBsm"  IPMA_ADAS
 SG_ RR_CAN_DET_VALID_LEVEL_019 : 256|1@0+ (1,0) [0|1] ""  IPMA_ADAS
 SG_ RR_CAN_DET_ELEVATION_018 : 255|7@0+ (0.157449,-9.99812) [-9.99812|9.997903] "deg"  IPMA_ADAS
 SG_ RR_CAN_DET_SUPER_RES_TARGET_018 : 248|1@0+ (1,0) [0|1] ""  IPMA_ADAS
 SG_ RR_CAN_DET_AZIMUTH_018 : 239|14@0+ (0.021967,-180) [-180|179.885361] "deg"  IPMA_ADAS
 SG_ RR_CAN_DET_CONFID_ELEVATION_018 : 241|1@0+ (1,0) [0|1] ""  IPMA_ADAS
 SG_ RR_CAN_DET_HOST_VEH_CLUTTER_018 : 240|1@0+ (1,0) [0|1] ""  IPMA_ADAS
 SG_ RR_CAN_DET_RANGE_018 : 223|14@0+ (0.015625,0) [0|255.984375] "m"  IPMA_ADAS
 SG_ RR_CAN_DET_CONFID_AZIMUTH_018 : 225|2@0+ (1,0) [0|3] ""  IPMA_ADAS
 SG_ RR_CAN_DET_RANGE_RATE_018 : 207|14@0+ (0.015625,-128) [-128|127.984375] "m/s"  IPMA_ADAS
 SG_ RR_CAN_SCAN_INDEX_2LSB_018 : 209|2@0+ (1,0) [0|3] ""  IPMA_ADAS
 SG_ RR_CAN_DET_AMPLITUDE_018 : 199|7@0+ (1,-64) [-64|63] "dBsm"  IPMA_ADAS
 SG_ RR_CAN_DET_VALID_LEVEL_018 : 192|1@0+ (1,0) [0|1] ""  IPMA_ADAS
 SG_ RR_CAN_DET_ELEVATION_017 : 191|7@0+ (0.157449,-9.99812) [-9.99812|9.997903] "deg"  IPMA_ADAS
 SG_ RR_CAN_DET_SUPER_RES_TARGET_017 : 184|1@0+ (1,0) [0|1] ""  IPMA_ADAS
 SG_ RR_CAN_DET_AZIMUTH_017 : 175|14@0+ (0.021967,-180) [-180|179.885361] "deg"  IPMA_ADAS
 SG_ RR_CAN_DET_CONFID_ELEVATION_017 : 177|1@0+ (1,0) [0|1] ""  IPMA_ADAS
 SG_ RR_CAN_DET_HOST_VEH_CLUTTER_017 : 176|1@0+ (1,0) [0|1] ""  IPMA_ADAS
 SG_ RR_CAN_DET_RANGE_017 : 159|14@0+ (0.015625,0) [0|255.984375] "m"  IPMA_ADAS
 SG_ RR_CAN_DET_CONFID_AZIMUTH_017 : 161|2@0+ (1,0) [0|3] ""  IPMA_ADAS
 SG_ RR_CAN_DET_RANGE_RATE_017 : 143|14@0+ (0.015625,-128) [-128|127.984375] "m/s"  IPMA_ADAS
 SG_ RR_CAN_SCAN_INDEX_2LSB_017 : 145|2@0+ (1,0) [0|3] ""  IPMA_ADAS
 SG_ RR_CAN_DET_AMPLITUDE_017 : 135|7@0+ (1,-64) [-64|63] "dBsm"  IPMA_ADAS
 SG_ RR_CAN_DET_VALID_LEVEL_017 : 128|1@0+ (1,0) [0|1] ""  IPMA_ADAS
 SG_ RR_CAN_DET_ELEVATION_016 : 127|7@0+ (0.157449,-9.99812) [-9.99812|9.997903] "deg"  IPMA_ADAS
 SG_ RR_CAN_DET_SUPER_RES_TARGET_016 : 120|1@0+ (1,0) [0|1] ""  IPMA_ADAS
 SG_ RR_CAN_DET_AZIMUTH_016 : 111|14@0+ (0.021967,-180) [-180|179.885361] "deg"  IPMA_ADAS
 SG_ RR_CAN_DET_CONFID_ELEVATION_016 : 113|1@0+ (1,0) [0|1] ""  IPMA_ADAS
 SG_ RR_CAN_DET_HOST_VEH_CLUTTER_016 : 112|1@0+ (1,0) [0|1] ""  IPMA_ADAS
 SG_ RR_CAN_DET_RANGE_016 : 95|14@0+ (0.015625,0) [0|255.984375] "m"  IPMA_ADAS
 SG_ RR_CAN_DET_CONFID_AZIMUTH_016 : 97|2@0+ (1,0) [0|3] ""  IPMA_ADAS
 SG_ RR_CAN_DET_RANGE_RATE_016 : 79|14@0+ (0.015625,-128) [-128|127.984375] "m/s"  IPMA_ADAS
 SG_ RR_CAN_SCAN_INDEX_2LSB_016 : 81|2@0+ (1,0) [0|3] ""  IPMA_ADAS
 SG_ RR_CAN_DET_AMPLITUDE_016 : 71|7@0+ (1,-64) [-64|63] "dBsm"  IPMA_ADAS
 SG_ RR_CAN_DET_VALID_LEVEL_016 : 64|1@0+ (1,0) [0|1] ""  IPMA_ADAS

BO_ 1027 RR_Detection_022_028: 64 SODRR
 SG_ RR_CAN_DET_ELEVATION_022 : 63|7@0+ (0.157449,-9.99812) [-9.99812|9.997903] "deg"  IPMA_ADAS
 SG_ RR_CAN_DET_CONFID_AZIMUTH_022 : 33|2@0+ (1,0) [0|3] ""  IPMA_ADAS
 SG_ RR_CAN_DET_SUPER_RES_TARGET_022 : 56|1@0+ (1,0) [0|1] ""  IPMA_ADAS
 SG_ RR_CAN_DET_CONFID_ELEVATION_022 : 49|1@0+ (1,0) [0|1] ""  IPMA_ADAS
 SG_ RR_CAN_DET_HOST_VEH_CLUTTER_022 : 48|1@0+ (1,0) [0|1] ""  IPMA_ADAS
 SG_ RR_CAN_DET_VALID_LEVEL_022 : 0|1@0+ (1,0) [0|1] ""  IPMA_ADAS
 SG_ RR_CAN_DET_AZIMUTH_022 : 47|14@0+ (0.021967,-180) [-180|179.885361] "deg"  IPMA_ADAS
 SG_ RR_CAN_DET_RANGE_022 : 31|14@0+ (0.015625,0) [0|255.984375] "m"  IPMA_ADAS
 SG_ RR_CAN_DET_RANGE_RATE_022 : 15|14@0+ (0.015625,-128) [-128|127.984375] "m/s"  IPMA_ADAS
 SG_ RR_CAN_DET_AMPLITUDE_022 : 7|7@0+ (1,-64) [-64|63] "dBsm"  IPMA_ADAS
 SG_ RR_CAN_SCAN_INDEX_2LSB_022 : 17|2@0+ (1,0) [0|3] ""  IPMA_ADAS
 SG_ RR_DET_MC_004 : 451|4@0+ (1,0) [0|0] ""  IPMA_ADAS
 SG_ RR_DET_CRC_004 : 463|16@0+ (1,0) [0|0] ""  IPMA_ADAS
 SG_ RR_CAN_DET_ELEVATION_028 : 447|7@0+ (0.157449,-9.99812) [-9.99812|9.997903] "deg"  IPMA_ADAS
 SG_ RR_CAN_DET_SUPER_RES_TARGET_028 : 440|1@0+ (1,0) [0|1] ""  IPMA_ADAS
 SG_ RR_CAN_DET_AZIMUTH_028 : 431|14@0+ (0.021967,-180) [-180|179.885361] "deg"  IPMA_ADAS
 SG_ RR_CAN_DET_CONFID_ELEVATION_028 : 433|1@0+ (1,0) [0|1] ""  IPMA_ADAS
 SG_ RR_CAN_DET_HOST_VEH_CLUTTER_028 : 432|1@0+ (1,0) [0|1] ""  IPMA_ADAS
 SG_ RR_CAN_DET_RANGE_028 : 415|14@0+ (0.015625,0) [0|255.984375] "m"  IPMA_ADAS
 SG_ RR_CAN_DET_CONFID_AZIMUTH_028 : 417|2@0+ (1,0) [0|3] ""  IPMA_ADAS
 SG_ RR_CAN_DET_RANGE_RATE_028 : 399|14@0+ (0.015625,-128) [-128|127.984375] "m/s"  IPMA_ADAS
 SG_ RR_CAN_SCAN_INDEX_2LSB_028 : 401|2@0+ (1,0) [0|3] ""  IPMA_ADAS
 SG_ RR_CAN_DET_AMPLITUDE_028 : 391|7@0+ (1,-64) [-64|63] "dBsm"  IPMA_ADAS
 SG_ RR_CAN_DET_VALID_LEVEL_028 : 384|1@0+ (1,0) [0|1] ""  IPMA_ADAS
 SG_ RR_CAN_DET_ELEVATION_027 : 383|7@0+ (0.157449,-9.99812) [-9.99812|9.997903] "deg"  IPMA_ADAS
 SG_ RR_CAN_DET_SUPER_RES_TARGET_027 : 376|1@0+ (1,0) [0|1] ""  IPMA_ADAS
 SG_ RR_CAN_DET_AZIMUTH_027 : 367|14@0+ (0.021967,-180) [-180|179.885361] "deg"  IPMA_ADAS
 SG_ RR_CAN_DET_CONFID_ELEVATION_027 : 369|1@0+ (1,0) [0|1] ""  IPMA_ADAS
 SG_ RR_CAN_DET_HOST_VEH_CLUTTER_027 : 368|1@0+ (1,0) [0|1] ""  IPMA_ADAS
 SG_ RR_CAN_DET_RANGE_027 : 351|14@0+ (0.015625,0) [0|255.984375] "m"  IPMA_ADAS
 SG_ RR_CAN_DET_CONFID_AZIMUTH_027 : 353|2@0+ (1,0) [0|3] ""  IPMA_ADAS
 SG_ RR_CAN_DET_RANGE_RATE_027 : 335|14@0+ (0.015625,-128) [-128|127.984375] "m/s"  IPMA_ADAS
 SG_ RR_CAN_SCAN_INDEX_2LSB_027 : 337|2@0+ (1,0) [0|3] ""  IPMA_ADAS
 SG_ RR_CAN_DET_AMPLITUDE_027 : 327|7@0+ (1,-64) [-64|63] "dBsm"  IPMA_ADAS
 SG_ RR_CAN_DET_VALID_LEVEL_027 : 320|1@0+ (1,0) [0|1] ""  IPMA_ADAS
 SG_ RR_CAN_DET_ELEVATION_026 : 319|7@0+ (0.157449,-9.99812) [-9.99812|9.997903] "deg"  IPMA_ADAS
 SG_ RR_CAN_DET_SUPER_RES_TARGET_026 : 312|1@0+ (1,0) [0|1] ""  IPMA_ADAS
 SG_ RR_CAN_DET_AZIMUTH_026 : 303|14@0+ (0.021967,-180) [-180|179.885361] "deg"  IPMA_ADAS
 SG_ RR_CAN_DET_CONFID_ELEVATION_026 : 305|1@0+ (1,0) [0|1] ""  IPMA_ADAS
 SG_ RR_CAN_DET_HOST_VEH_CLUTTER_026 : 304|1@0+ (1,0) [0|1] ""  IPMA_ADAS
 SG_ RR_CAN_DET_RANGE_026 : 287|14@0+ (0.015625,0) [0|255.984375] "m"  IPMA_ADAS
 SG_ RR_CAN_DET_CONFID_AZIMUTH_026 : 289|2@0+ (1,0) [0|3] ""  IPMA_ADAS
 SG_ RR_CAN_DET_RANGE_RATE_026 : 271|14@0+ (0.015625,-128) [-128|127.984375] "m/s"  IPMA_ADAS
 SG_ RR_CAN_SCAN_INDEX_2LSB_026 : 273|2@0+ (1,0) [0|3] ""  IPMA_ADAS
 SG_ RR_CAN_DET_AMPLITUDE_026 : 263|7@0+ (1,-64) [-64|63] "dBsm"  IPMA_ADAS
 SG_ RR_CAN_DET_VALID_LEVEL_026 : 256|1@0+ (1,0) [0|1] ""  IPMA_ADAS
 SG_ RR_CAN_DET_ELEVATION_025 : 255|7@0+ (0.157449,-9.99812) [-9.99812|9.997903] "deg"  IPMA_ADAS
 SG_ RR_CAN_DET_SUPER_RES_TARGET_025 : 248|1@0+ (1,0) [0|1] ""  IPMA_ADAS
 SG_ RR_CAN_DET_AZIMUTH_025 : 239|14@0+ (0.021967,-180) [-180|179.885361] "deg"  IPMA_ADAS
 SG_ RR_CAN_DET_CONFID_ELEVATION_025 : 241|1@0+ (1,0) [0|1] ""  IPMA_ADAS
 SG_ RR_CAN_DET_HOST_VEH_CLUTTER_025 : 240|1@0+ (1,0) [0|1] ""  IPMA_ADAS
 SG_ RR_CAN_DET_RANGE_025 : 223|14@0+ (0.015625,0) [0|255.984375] "m"  IPMA_ADAS
 SG_ RR_CAN_DET_CONFID_AZIMUTH_025 : 225|2@0+ (1,0) [0|3] ""  IPMA_ADAS
 SG_ RR_CAN_DET_RANGE_RATE_025 : 207|14@0+ (0.015625,-128) [-128|127.984375] "m/s"  IPMA_ADAS
 SG_ RR_CAN_SCAN_INDEX_2LSB_025 : 209|2@0+ (1,0) [0|3] ""  IPMA_ADAS
 SG_ RR_CAN_DET_AMPLITUDE_025 : 199|7@0+ (1,-64) [-64|63] "dBsm"  IPMA_ADAS
 SG_ RR_CAN_DET_VALID_LEVEL_025 : 192|1@0+ (1,0) [0|1] ""  IPMA_ADAS
 SG_ RR_CAN_DET_ELEVATION_024 : 191|7@0+ (0.157449,-9.99812) [-9.99812|9.997903] "deg"  IPMA_ADAS
 SG_ RR_CAN_DET_SUPER_RES_TARGET_024 : 184|1@0+ (1,0) [0|1] ""  IPMA_ADAS
 SG_ RR_CAN_DET_AZIMUTH_024 : 175|14@0+ (0.021967,-180) [-180|179.885361] "deg"  IPMA_ADAS
 SG_ RR_CAN_DET_CONFID_ELEVATION_024 : 177|1@0+ (1,0) [0|1] ""  IPMA_ADAS
 SG_ RR_CAN_DET_HOST_VEH_CLUTTER_024 : 176|1@0+ (1,0) [0|1] ""  IPMA_ADAS
 SG_ RR_CAN_DET_RANGE_024 : 159|14@0+ (0.015625,0) [0|255.984375] "m"  IPMA_ADAS
 SG_ RR_CAN_DET_CONFID_AZIMUTH_024 : 161|2@0+ (1,0) [0|3] ""  IPMA_ADAS
 SG_ RR_CAN_DET_RANGE_RATE_024 : 143|14@0+ (0.015625,-128) [-128|127.984375] "m/s"  IPMA_ADAS
 SG_ RR_CAN_SCAN_INDEX_2LSB_024 : 145|2@0+ (1,0) [0|3] ""  IPMA_ADAS
 SG_ RR_CAN_DET_AMPLITUDE_024 : 135|7@0+ (1,-64) [-64|63] "dBsm"  IPMA_ADAS
 SG_ RR_CAN_DET_VALID_LEVEL_024 : 128|1@0+ (1,0) [0|1] ""  IPMA_ADAS
 SG_ RR_CAN_DET_ELEVATION_023 : 127|7@0+ (0.157449,-9.99812) [-9.99812|9.997903] "deg"  IPMA_ADAS
 SG_ RR_CAN_DET_SUPER_RES_TARGET_023 : 120|1@0+ (1,0) [0|1] ""  IPMA_ADAS
 SG_ RR_CAN_DET_AZIMUTH_023 : 111|14@0+ (0.021967,-180) [-180|179.885361] "deg"  IPMA_ADAS
 SG_ RR_CAN_DET_CONFID_ELEVATION_023 : 113|1@0+ (1,0) [0|1] ""  IPMA_ADAS
 SG_ RR_CAN_DET_HOST_VEH_CLUTTER_023 : 112|1@0+ (1,0) [0|1] ""  IPMA_ADAS
 SG_ RR_CAN_DET_RANGE_023 : 95|14@0+ (0.015625,0) [0|255.984375] "m"  IPMA_ADAS
 SG_ RR_CAN_DET_CONFID_AZIMUTH_023 : 97|2@0+ (1,0) [0|3] ""  IPMA_ADAS
 SG_ RR_CAN_DET_RANGE_RATE_023 : 79|14@0+ (0.015625,-128) [-128|127.984375] "m/s"  IPMA_ADAS
 SG_ RR_CAN_SCAN_INDEX_2LSB_023 : 81|2@0+ (1,0) [0|3] ""  IPMA_ADAS
 SG_ RR_CAN_DET_AMPLITUDE_023 : 71|7@0+ (1,-64) [-64|63] "dBsm"  IPMA_ADAS
 SG_ RR_CAN_DET_VALID_LEVEL_023 : 64|1@0+ (1,0) [0|1] ""  IPMA_ADAS

BO_ 1028 RR_Detection_029_035: 64 SODRR
 SG_ RR_CAN_DET_ELEVATION_029 : 63|7@0+ (0.157449,-9.99812) [-9.99812|9.997903] "deg"  IPMA_ADAS
 SG_ RR_CAN_DET_CONFID_AZIMUTH_029 : 33|2@0+ (1,0) [0|3] ""  IPMA_ADAS
 SG_ RR_CAN_DET_SUPER_RES_TARGET_029 : 56|1@0+ (1,0) [0|1] ""  IPMA_ADAS
 SG_ RR_CAN_DET_CONFID_ELEVATION_029 : 49|1@0+ (1,0) [0|1] ""  IPMA_ADAS
 SG_ RR_CAN_DET_HOST_VEH_CLUTTER_029 : 48|1@0+ (1,0) [0|1] ""  IPMA_ADAS
 SG_ RR_CAN_DET_VALID_LEVEL_029 : 0|1@0+ (1,0) [0|1] ""  IPMA_ADAS
 SG_ RR_CAN_DET_AZIMUTH_029 : 47|14@0+ (0.021967,-180) [-180|179.885361] "deg"  IPMA_ADAS
 SG_ RR_CAN_DET_RANGE_029 : 31|14@0+ (0.015625,0) [0|255.984375] "m"  IPMA_ADAS
 SG_ RR_CAN_DET_RANGE_RATE_029 : 15|14@0+ (0.015625,-128) [-128|127.984375] "m/s"  IPMA_ADAS
 SG_ RR_CAN_DET_AMPLITUDE_029 : 7|7@0+ (1,-64) [-64|63] "dBsm"  IPMA_ADAS
 SG_ RR_CAN_SCAN_INDEX_2LSB_029 : 17|2@0+ (1,0) [0|3] ""  IPMA_ADAS
 SG_ RR_DET_MC_005 : 451|4@0+ (1,0) [0|0] ""  IPMA_ADAS
 SG_ RR_DET_CRC_005 : 463|16@0+ (1,0) [0|0] ""  IPMA_ADAS
 SG_ RR_CAN_DET_ELEVATION_035 : 447|7@0+ (0.157449,-9.99812) [-9.99812|9.997903] "deg"  IPMA_ADAS
 SG_ RR_CAN_DET_SUPER_RES_TARGET_035 : 440|1@0+ (1,0) [0|1] ""  IPMA_ADAS
 SG_ RR_CAN_DET_AZIMUTH_035 : 431|14@0+ (0.021967,-180) [-180|179.885361] "deg"  IPMA_ADAS
 SG_ RR_CAN_DET_CONFID_ELEVATION_035 : 433|1@0+ (1,0) [0|1] ""  IPMA_ADAS
 SG_ RR_CAN_DET_HOST_VEH_CLUTTER_035 : 432|1@0+ (1,0) [0|1] ""  IPMA_ADAS
 SG_ RR_CAN_DET_RANGE_035 : 415|14@0+ (0.015625,0) [0|255.984375] "m"  IPMA_ADAS
 SG_ RR_CAN_DET_CONFID_AZIMUTH_035 : 417|2@0+ (1,0) [0|3] ""  IPMA_ADAS
 SG_ RR_CAN_DET_RANGE_RATE_035 : 399|14@0+ (0.015625,-128) [-128|127.984375] "m/s"  IPMA_ADAS
 SG_ RR_CAN_SCAN_INDEX_2LSB_035 : 401|2@0+ (1,0) [0|3] ""  IPMA_ADAS
 SG_ RR_CAN_DET_AMPLITUDE_035 : 391|7@0+ (1,-64) [-64|63] "dBsm"  IPMA_ADAS
 SG_ RR_CAN_DET_VALID_LEVEL_035 : 384|1@0+ (1,0) [0|1] ""  IPMA_ADAS
 SG_ RR_CAN_DET_ELEVATION_034 : 383|7@0+ (0.157449,-9.99812) [-9.99812|9.997903] "deg"  IPMA_ADAS
 SG_ RR_CAN_DET_SUPER_RES_TARGET_034 : 376|1@0+ (1,0) [0|1] ""  IPMA_ADAS
 SG_ RR_CAN_DET_AZIMUTH_034 : 367|14@0+ (0.021967,-180) [-180|179.885361] "deg"  IPMA_ADAS
 SG_ RR_CAN_DET_CONFID_ELEVATION_034 : 369|1@0+ (1,0) [0|1] ""  IPMA_ADAS
 SG_ RR_CAN_DET_HOST_VEH_CLUTTER_034 : 368|1@0+ (1,0) [0|1] ""  IPMA_ADAS
 SG_ RR_CAN_DET_RANGE_034 : 351|14@0+ (0.015625,0) [0|255.984375] "m"  IPMA_ADAS
 SG_ RR_CAN_DET_CONFID_AZIMUTH_034 : 353|2@0+ (1,0) [0|3] ""  IPMA_ADAS
 SG_ RR_CAN_DET_RANGE_RATE_034 : 335|14@0+ (0.015625,-128) [-128|127.984375] "m/s"  IPMA_ADAS
 SG_ RR_CAN_SCAN_INDEX_2LSB_034 : 337|2@0+ (1,0) [0|3] ""  IPMA_ADAS
 SG_ RR_CAN_DET_AMPLITUDE_034 : 327|7@0+ (1,-64) [-64|63] "dBsm"  IPMA_ADAS
 SG_ RR_CAN_DET_VALID_LEVEL_034 : 320|1@0+ (1,0) [0|1] ""  IPMA_ADAS
 SG_ RR_CAN_DET_ELEVATION_033 : 319|7@0+ (0.157449,-9.99812) [-9.99812|9.997903] "deg"  IPMA_ADAS
 SG_ RR_CAN_DET_SUPER_RES_TARGET_033 : 312|1@0+ (1,0) [0|1] ""  IPMA_ADAS
 SG_ RR_CAN_DET_AZIMUTH_033 : 303|14@0+ (0.021967,-180) [-180|179.885361] "deg"  IPMA_ADAS
 SG_ RR_CAN_DET_CONFID_ELEVATION_033 : 305|1@0+ (1,0) [0|1] ""  IPMA_ADAS
 SG_ RR_CAN_DET_HOST_VEH_CLUTTER_033 : 304|1@0+ (1,0) [0|1] ""  IPMA_ADAS
 SG_ RR_CAN_DET_RANGE_033 : 287|14@0+ (0.015625,0) [0|255.984375] "m"  IPMA_ADAS
 SG_ RR_CAN_DET_CONFID_AZIMUTH_033 : 289|2@0+ (1,0) [0|3] ""  IPMA_ADAS
 SG_ RR_CAN_DET_RANGE_RATE_033 : 271|14@0+ (0.015625,-128) [-128|127.984375] "m/s"  IPMA_ADAS
 SG_ RR_CAN_SCAN_INDEX_2LSB_033 : 273|2@0+ (1,0) [0|3] ""  IPMA_ADAS
 SG_ RR_CAN_DET_AMPLITUDE_033 : 263|7@0+ (1,-64) [-64|63] "dBsm"  IPMA_ADAS
 SG_ RR_CAN_DET_VALID_LEVEL_033 : 256|1@0+ (1,0) [0|1] ""  IPMA_ADAS
 SG_ RR_CAN_DET_ELEVATION_032 : 255|7@0+ (0.157449,-9.99812) [-9.99812|9.997903] "deg"  IPMA_ADAS
 SG_ RR_CAN_DET_SUPER_RES_TARGET_032 : 248|1@0+ (1,0) [0|1] ""  IPMA_ADAS
 SG_ RR_CAN_DET_AZIMUTH_032 : 239|14@0+ (0.021967,-180) [-180|179.885361] "deg"  IPMA_ADAS
 SG_ RR_CAN_DET_CONFID_ELEVATION_032 : 241|1@0+ (1,0) [0|1] ""  IPMA_ADAS
 SG_ RR_CAN_DET_HOST_VEH_CLUTTER_032 : 240|1@0+ (1,0) [0|1] ""  IPMA_ADAS
 SG_ RR_CAN_DET_RANGE_032 : 223|14@0+ (0.015625,0) [0|255.984375] "m"  IPMA_ADAS
 SG_ RR_CAN_DET_CONFID_AZIMUTH_032 : 225|2@0+ (1,0) [0|3] ""  IPMA_ADAS
 SG_ RR_CAN_DET_RANGE_RATE_032 : 207|14@0+ (0.015625,-128) [-128|127.984375] "m/s"  IPMA_ADAS
 SG_ RR_CAN_SCAN_INDEX_2LSB_032 : 209|2@0+ (1,0) [0|3] ""  IPMA_ADAS
 SG_ RR_CAN_DET_AMPLITUDE_032 : 199|7@0+ (1,-64) [-64|63] "dBsm"  IPMA_ADAS
 SG_ RR_CAN_DET_VALID_LEVEL_032 : 192|1@0+ (1,0) [0|1] ""  IPMA_ADAS
 SG_ RR_CAN_DET_ELEVATION_031 : 191|7@0+ (0.157449,-9.99812) [-9.99812|9.997903] "deg"  IPMA_ADAS
 SG_ RR_CAN_DET_SUPER_RES_TARGET_031 : 184|1@0+ (1,0) [0|1] ""  IPMA_ADAS
 SG_ RR_CAN_DET_AZIMUTH_031 : 175|14@0+ (0.021967,-180) [-180|179.885361] "deg"  IPMA_ADAS
 SG_ RR_CAN_DET_CONFID_ELEVATION_031 : 177|1@0+ (1,0) [0|1] ""  IPMA_ADAS
 SG_ RR_CAN_DET_HOST_VEH_CLUTTER_031 : 176|1@0+ (1,0) [0|1] ""  IPMA_ADAS
 SG_ RR_CAN_DET_RANGE_031 : 159|14@0+ (0.015625,0) [0|255.984375] "m"  IPMA_ADAS
 SG_ RR_CAN_DET_CONFID_AZIMUTH_031 : 161|2@0+ (1,0) [0|3] ""  IPMA_ADAS
 SG_ RR_CAN_DET_RANGE_RATE_031 : 143|14@0+ (0.015625,-128) [-128|127.984375] "m/s"  IPMA_ADAS
 SG_ RR_CAN_SCAN_INDEX_2LSB_031 : 145|2@0+ (1,0) [0|3] ""  IPMA_ADAS
 SG_ RR_CAN_DET_AMPLITUDE_031 : 135|7@0+ (1,-64) [-64|63] "dBsm"  IPMA_ADAS
 SG_ RR_CAN_DET_VALID_LEVEL_031 : 128|1@0+ (1,0) [0|1] ""  IPMA_ADAS
 SG_ RR_CAN_DET_ELEVATION_030 : 127|7@0+ (0.157449,-9.99812) [-9.99812|9.997903] "deg"  IPMA_ADAS
 SG_ RR_CAN_DET_SUPER_RES_TARGET_030 : 120|1@0+ (1,0) [0|1] ""  IPMA_ADAS
 SG_ RR_CAN_DET_AZIMUTH_030 : 111|14@0+ (0.021967,-180) [-180|179.885361] "deg"  IPMA_ADAS
 SG_ RR_CAN_DET_CONFID_ELEVATION_030 : 113|1@0+ (1,0) [0|1] ""  IPMA_ADAS
 SG_ RR_CAN_DET_HOST_VEH_CLUTTER_030 : 112|1@0+ (1,0) [0|1] ""  IPMA_ADAS
 SG_ RR_CAN_DET_RANGE_030 : 95|14@0+ (0.015625,0) [0|255.984375] "m"  IPMA_ADAS
 SG_ RR_CAN_DET_CONFID_AZIMUTH_030 : 97|2@0+ (1,0) [0|3] ""  IPMA_ADAS
 SG_ RR_CAN_DET_RANGE_RATE_030 : 79|14@0+ (0.015625,-128) [-128|127.984375] "m/s"  IPMA_ADAS
 SG_ RR_CAN_SCAN_INDEX_2LSB_030 : 81|2@0+ (1,0) [0|3] ""  IPMA_ADAS
 SG_ RR_CAN_DET_AMPLITUDE_030 : 71|7@0+ (1,-64) [-64|63] "dBsm"  IPMA_ADAS
 SG_ RR_CAN_DET_VALID_LEVEL_030 : 64|1@0+ (1,0) [0|1] ""  IPMA_ADAS

BO_ 1029 RR_Detection_036_042: 64 SODRR
 SG_ RR_CAN_DET_ELEVATION_036 : 63|7@0+ (0.157449,-9.99812) [-9.99812|9.997903] "deg"  IPMA_ADAS
 SG_ RR_CAN_DET_CONFID_AZIMUTH_036 : 33|2@0+ (1,0) [0|3] ""  IPMA_ADAS
 SG_ RR_CAN_DET_SUPER_RES_TARGET_036 : 56|1@0+ (1,0) [0|1] ""  IPMA_ADAS
 SG_ RR_CAN_DET_CONFID_ELEVATION_036 : 49|1@0+ (1,0) [0|1] ""  IPMA_ADAS
 SG_ RR_CAN_DET_HOST_VEH_CLUTTER_036 : 48|1@0+ (1,0) [0|1] ""  IPMA_ADAS
 SG_ RR_CAN_DET_VALID_LEVEL_036 : 0|1@0+ (1,0) [0|1] ""  IPMA_ADAS
 SG_ RR_CAN_DET_AZIMUTH_036 : 47|14@0+ (0.021967,-180) [-180|179.885361] "deg"  IPMA_ADAS
 SG_ RR_CAN_DET_RANGE_036 : 31|14@0+ (0.015625,0) [0|255.984375] "m"  IPMA_ADAS
 SG_ RR_CAN_DET_RANGE_RATE_036 : 15|14@0+ (0.015625,-128) [-128|127.984375] "m/s"  IPMA_ADAS
 SG_ RR_CAN_DET_AMPLITUDE_036 : 7|7@0+ (1,-64) [-64|63] "dBsm"  IPMA_ADAS
 SG_ RR_CAN_SCAN_INDEX_2LSB_036 : 17|2@0+ (1,0) [0|3] ""  IPMA_ADAS
 SG_ RR_DET_MC_006 : 451|4@0+ (1,0) [0|0] ""  IPMA_ADAS
 SG_ RR_DET_CRC_006 : 463|16@0+ (1,0) [0|0] ""  IPMA_ADAS
 SG_ RR_CAN_DET_ELEVATION_042 : 447|7@0+ (0.157449,-9.99812) [-9.99812|9.997903] "deg"  IPMA_ADAS
 SG_ RR_CAN_DET_SUPER_RES_TARGET_042 : 440|1@0+ (1,0) [0|1] ""  IPMA_ADAS
 SG_ RR_CAN_DET_AZIMUTH_042 : 431|14@0+ (0.021967,-180) [-180|179.885361] "deg"  IPMA_ADAS
 SG_ RR_CAN_DET_CONFID_ELEVATION_042 : 433|1@0+ (1,0) [0|1] ""  IPMA_ADAS
 SG_ RR_CAN_DET_HOST_VEH_CLUTTER_042 : 432|1@0+ (1,0) [0|1] ""  IPMA_ADAS
 SG_ RR_CAN_DET_RANGE_042 : 415|14@0+ (0.015625,0) [0|255.984375] "m"  IPMA_ADAS
 SG_ RR_CAN_DET_CONFID_AZIMUTH_042 : 417|2@0+ (1,0) [0|3] ""  IPMA_ADAS
 SG_ RR_CAN_DET_RANGE_RATE_042 : 399|14@0+ (0.015625,-128) [-128|127.984375] "m/s"  IPMA_ADAS
 SG_ RR_CAN_SCAN_INDEX_2LSB_042 : 401|2@0+ (1,0) [0|3] ""  IPMA_ADAS
 SG_ RR_CAN_DET_AMPLITUDE_042 : 391|7@0+ (1,-64) [-64|63] "dBsm"  IPMA_ADAS
 SG_ RR_CAN_DET_VALID_LEVEL_042 : 384|1@0+ (1,0) [0|1] ""  IPMA_ADAS
 SG_ RR_CAN_DET_ELEVATION_041 : 383|7@0+ (0.157449,-9.99812) [-9.99812|9.997903] "deg"  IPMA_ADAS
 SG_ RR_CAN_DET_SUPER_RES_TARGET_041 : 376|1@0+ (1,0) [0|1] ""  IPMA_ADAS
 SG_ RR_CAN_DET_AZIMUTH_041 : 367|14@0+ (0.021967,-180) [-180|179.885361] "deg"  IPMA_ADAS
 SG_ RR_CAN_DET_CONFID_ELEVATION_041 : 369|1@0+ (1,0) [0|1] ""  IPMA_ADAS
 SG_ RR_CAN_DET_HOST_VEH_CLUTTER_041 : 368|1@0+ (1,0) [0|1] ""  IPMA_ADAS
 SG_ RR_CAN_DET_RANGE_041 : 351|14@0+ (0.015625,0) [0|255.984375] "m"  IPMA_ADAS
 SG_ RR_CAN_DET_CONFID_AZIMUTH_041 : 353|2@0+ (1,0) [0|3] ""  IPMA_ADAS
 SG_ RR_CAN_DET_RANGE_RATE_041 : 335|14@0+ (0.015625,-128) [-128|127.984375] "m/s"  IPMA_ADAS
 SG_ RR_CAN_SCAN_INDEX_2LSB_041 : 337|2@0+ (1,0) [0|3] ""  IPMA_ADAS
 SG_ RR_CAN_DET_AMPLITUDE_041 : 327|7@0+ (1,-64) [-64|63] "dBsm"  IPMA_ADAS
 SG_ RR_CAN_DET_VALID_LEVEL_041 : 320|1@0+ (1,0) [0|1] ""  IPMA_ADAS
 SG_ RR_CAN_DET_ELEVATION_040 : 319|7@0+ (0.157449,-9.99812) [-9.99812|9.997903] "deg"  IPMA_ADAS
 SG_ RR_CAN_DET_SUPER_RES_TARGET_040 : 312|1@0+ (1,0) [0|1] ""  IPMA_ADAS
 SG_ RR_CAN_DET_AZIMUTH_040 : 303|14@0+ (0.021967,-180) [-180|179.885361] "deg"  IPMA_ADAS
 SG_ RR_CAN_DET_CONFID_ELEVATION_040 : 305|1@0+ (1,0) [0|1] ""  IPMA_ADAS
 SG_ RR_CAN_DET_HOST_VEH_CLUTTER_040 : 304|1@0+ (1,0) [0|1] ""  IPMA_ADAS
 SG_ RR_CAN_DET_RANGE_040 : 287|14@0+ (0.015625,0) [0|255.984375] "m"  IPMA_ADAS
 SG_ RR_CAN_DET_CONFID_AZIMUTH_040 : 289|2@0+ (1,0) [0|3] ""  IPMA_ADAS
 SG_ RR_CAN_DET_RANGE_RATE_040 : 271|14@0+ (0.015625,-128) [-128|127.984375] "m/s"  IPMA_ADAS
 SG_ RR_CAN_SCAN_INDEX_2LSB_040 : 273|2@0+ (1,0) [0|3] ""  IPMA_ADAS
 SG_ RR_CAN_DET_AMPLITUDE_040 : 263|7@0+ (1,-64) [-64|63] "dBsm"  IPMA_ADAS
 SG_ RR_CAN_DET_VALID_LEVEL_040 : 256|1@0+ (1,0) [0|1] ""  IPMA_ADAS
 SG_ RR_CAN_DET_ELEVATION_039 : 255|7@0+ (0.157449,-9.99812) [-9.99812|9.997903] "deg"  IPMA_ADAS
 SG_ RR_CAN_DET_SUPER_RES_TARGET_039 : 248|1@0+ (1,0) [0|1] ""  IPMA_ADAS
 SG_ RR_CAN_DET_AZIMUTH_039 : 239|14@0+ (0.021967,-180) [-180|179.885361] "deg"  IPMA_ADAS
 SG_ RR_CAN_DET_CONFID_ELEVATION_039 : 241|1@0+ (1,0) [0|1] ""  IPMA_ADAS
 SG_ RR_CAN_DET_HOST_VEH_CLUTTER_039 : 240|1@0+ (1,0) [0|1] ""  IPMA_ADAS
 SG_ RR_CAN_DET_RANGE_039 : 223|14@0+ (0.015625,0) [0|255.984375] "m"  IPMA_ADAS
 SG_ RR_CAN_DET_CONFID_AZIMUTH_039 : 225|2@0+ (1,0) [0|3] ""  IPMA_ADAS
 SG_ RR_CAN_DET_RANGE_RATE_039 : 207|14@0+ (0.015625,-128) [-128|127.984375] "m/s"  IPMA_ADAS
 SG_ RR_CAN_SCAN_INDEX_2LSB_039 : 209|2@0+ (1,0) [0|3] ""  IPMA_ADAS
 SG_ RR_CAN_DET_AMPLITUDE_039 : 199|7@0+ (1,-64) [-64|63] "dBsm"  IPMA_ADAS
 SG_ RR_CAN_DET_VALID_LEVEL_039 : 192|1@0+ (1,0) [0|1] ""  IPMA_ADAS
 SG_ RR_CAN_DET_ELEVATION_038 : 191|7@0+ (0.157449,-9.99812) [-9.99812|9.997903] "deg"  IPMA_ADAS
 SG_ RR_CAN_DET_SUPER_RES_TARGET_038 : 184|1@0+ (1,0) [0|1] ""  IPMA_ADAS
 SG_ RR_CAN_DET_AZIMUTH_038 : 175|14@0+ (0.021967,-180) [-180|179.885361] "deg"  IPMA_ADAS
 SG_ RR_CAN_DET_CONFID_ELEVATION_038 : 177|1@0+ (1,0) [0|1] ""  IPMA_ADAS
 SG_ RR_CAN_DET_HOST_VEH_CLUTTER_038 : 176|1@0+ (1,0) [0|1] ""  IPMA_ADAS
 SG_ RR_CAN_DET_RANGE_038 : 159|14@0+ (0.015625,0) [0|255.984375] "m"  IPMA_ADAS
 SG_ RR_CAN_DET_CONFID_AZIMUTH_038 : 161|2@0+ (1,0) [0|3] ""  IPMA_ADAS
 SG_ RR_CAN_DET_RANGE_RATE_038 : 143|14@0+ (0.015625,-128) [-128|127.984375] "m/s"  IPMA_ADAS
 SG_ RR_CAN_SCAN_INDEX_2LSB_038 : 145|2@0+ (1,0) [0|3] ""  IPMA_ADAS
 SG_ RR_CAN_DET_AMPLITUDE_038 : 135|7@0+ (1,-64) [-64|63] "dBsm"  IPMA_ADAS
 SG_ RR_CAN_DET_VALID_LEVEL_038 : 128|1@0+ (1,0) [0|1] ""  IPMA_ADAS
 SG_ RR_CAN_DET_ELEVATION_037 : 127|7@0+ (0.157449,-9.99812) [-9.99812|9.997903] "deg"  IPMA_ADAS
 SG_ RR_CAN_DET_SUPER_RES_TARGET_037 : 120|1@0+ (1,0) [0|1] ""  IPMA_ADAS
 SG_ RR_CAN_DET_AZIMUTH_037 : 111|14@0+ (0.021967,-180) [-180|179.885361] "deg"  IPMA_ADAS
 SG_ RR_CAN_DET_CONFID_ELEVATION_037 : 113|1@0+ (1,0) [0|1] ""  IPMA_ADAS
 SG_ RR_CAN_DET_HOST_VEH_CLUTTER_037 : 112|1@0+ (1,0) [0|1] ""  IPMA_ADAS
 SG_ RR_CAN_DET_RANGE_037 : 95|14@0+ (0.015625,0) [0|255.984375] "m"  IPMA_ADAS
 SG_ RR_CAN_DET_CONFID_AZIMUTH_037 : 97|2@0+ (1,0) [0|3] ""  IPMA_ADAS
 SG_ RR_CAN_DET_RANGE_RATE_037 : 79|14@0+ (0.015625,-128) [-128|127.984375] "m/s"  IPMA_ADAS
 SG_ RR_CAN_SCAN_INDEX_2LSB_037 : 81|2@0+ (1,0) [0|3] ""  IPMA_ADAS
 SG_ RR_CAN_DET_AMPLITUDE_037 : 71|7@0+ (1,-64) [-64|63] "dBsm"  IPMA_ADAS
 SG_ RR_CAN_DET_VALID_LEVEL_037 : 64|1@0+ (1,0) [0|1] ""  IPMA_ADAS

BO_ 1030 RR_Detection_043_049: 64 SODRR
 SG_ RR_CAN_DET_ELEVATION_043 : 63|7@0+ (0.157449,-9.99812) [-9.99812|9.997903] "deg"  IPMA_ADAS
 SG_ RR_CAN_DET_CONFID_AZIMUTH_043 : 33|2@0+ (1,0) [0|3] ""  IPMA_ADAS
 SG_ RR_CAN_DET_SUPER_RES_TARGET_043 : 56|1@0+ (1,0) [0|1] ""  IPMA_ADAS
 SG_ RR_CAN_DET_CONFID_ELEVATION_043 : 49|1@0+ (1,0) [0|1] ""  IPMA_ADAS
 SG_ RR_CAN_DET_HOST_VEH_CLUTTER_043 : 48|1@0+ (1,0) [0|1] ""  IPMA_ADAS
 SG_ RR_CAN_DET_VALID_LEVEL_043 : 0|1@0+ (1,0) [0|1] ""  IPMA_ADAS
 SG_ RR_CAN_DET_AZIMUTH_043 : 47|14@0+ (0.021967,-180) [-180|179.885361] "deg"  IPMA_ADAS
 SG_ RR_CAN_DET_RANGE_043 : 31|14@0+ (0.015625,0) [0|255.984375] "m"  IPMA_ADAS
 SG_ RR_CAN_DET_RANGE_RATE_043 : 15|14@0+ (0.015625,-128) [-128|127.984375] "m/s"  IPMA_ADAS
 SG_ RR_CAN_DET_AMPLITUDE_043 : 7|7@0+ (1,-64) [-64|63] "dBsm"  IPMA_ADAS
 SG_ RR_CAN_SCAN_INDEX_2LSB_043 : 17|2@0+ (1,0) [0|3] ""  IPMA_ADAS
 SG_ RR_DET_MC_007 : 451|4@0+ (1,0) [0|0] ""  IPMA_ADAS
 SG_ RR_DET_CRC_007 : 463|16@0+ (1,0) [0|0] ""  IPMA_ADAS
 SG_ RR_CAN_DET_ELEVATION_049 : 447|7@0+ (0.157449,-9.99812) [-9.99812|9.997903] "deg"  IPMA_ADAS
 SG_ RR_CAN_DET_SUPER_RES_TARGET_049 : 440|1@0+ (1,0) [0|1] ""  IPMA_ADAS
 SG_ RR_CAN_DET_AZIMUTH_049 : 431|14@0+ (0.021967,-180) [-180|179.885361] "deg"  IPMA_ADAS
 SG_ RR_CAN_DET_CONFID_ELEVATION_049 : 433|1@0+ (1,0) [0|1] ""  IPMA_ADAS
 SG_ RR_CAN_DET_HOST_VEH_CLUTTER_049 : 432|1@0+ (1,0) [0|1] ""  IPMA_ADAS
 SG_ RR_CAN_DET_RANGE_049 : 415|14@0+ (0.015625,0) [0|255.984375] "m"  IPMA_ADAS
 SG_ RR_CAN_DET_CONFID_AZIMUTH_049 : 417|2@0+ (1,0) [0|3] ""  IPMA_ADAS
 SG_ RR_CAN_DET_RANGE_RATE_049 : 399|14@0+ (0.015625,-128) [-128|127.984375] "m/s"  IPMA_ADAS
 SG_ RR_CAN_SCAN_INDEX_2LSB_049 : 401|2@0+ (1,0) [0|3] ""  IPMA_ADAS
 SG_ RR_CAN_DET_AMPLITUDE_049 : 391|7@0+ (1,-64) [-64|63] "dBsm"  IPMA_ADAS
 SG_ RR_CAN_DET_VALID_LEVEL_049 : 384|1@0+ (1,0) [0|1] ""  IPMA_ADAS
 SG_ RR_CAN_DET_ELEVATION_048 : 383|7@0+ (0.157449,-9.99812) [-9.99812|9.997903] "deg"  IPMA_ADAS
 SG_ RR_CAN_DET_SUPER_RES_TARGET_048 : 376|1@0+ (1,0) [0|1] ""  IPMA_ADAS
 SG_ RR_CAN_DET_AZIMUTH_048 : 367|14@0+ (0.021967,-180) [-180|179.885361] "deg"  IPMA_ADAS
 SG_ RR_CAN_DET_CONFID_ELEVATION_048 : 369|1@0+ (1,0) [0|1] ""  IPMA_ADAS
 SG_ RR_CAN_DET_HOST_VEH_CLUTTER_048 : 368|1@0+ (1,0) [0|1] ""  IPMA_ADAS
 SG_ RR_CAN_DET_RANGE_048 : 351|14@0+ (0.015625,0) [0|255.984375] "m"  IPMA_ADAS
 SG_ RR_CAN_DET_CONFID_AZIMUTH_048 : 353|2@0+ (1,0) [0|3] ""  IPMA_ADAS
 SG_ RR_CAN_DET_RANGE_RATE_048 : 335|14@0+ (0.015625,-128) [-128|127.984375] "m/s"  IPMA_ADAS
 SG_ RR_CAN_SCAN_INDEX_2LSB_048 : 337|2@0+ (1,0) [0|3] ""  IPMA_ADAS
 SG_ RR_CAN_DET_AMPLITUDE_048 : 327|7@0+ (1,-64) [-64|63] "dBsm"  IPMA_ADAS
 SG_ RR_CAN_DET_VALID_LEVEL_048 : 320|1@0+ (1,0) [0|1] ""  IPMA_ADAS
 SG_ RR_CAN_DET_ELEVATION_047 : 319|7@0+ (0.157449,-9.99812) [-9.99812|9.997903] "deg"  IPMA_ADAS
 SG_ RR_CAN_DET_SUPER_RES_TARGET_047 : 312|1@0+ (1,0) [0|1] ""  IPMA_ADAS
 SG_ RR_CAN_DET_AZIMUTH_047 : 303|14@0+ (0.021967,-180) [-180|179.885361] "deg"  IPMA_ADAS
 SG_ RR_CAN_DET_CONFID_ELEVATION_047 : 305|1@0+ (1,0) [0|1] ""  IPMA_ADAS
 SG_ RR_CAN_DET_HOST_VEH_CLUTTER_047 : 304|1@0+ (1,0) [0|1] ""  IPMA_ADAS
 SG_ RR_CAN_DET_RANGE_047 : 287|14@0+ (0.015625,0) [0|255.984375] "m"  IPMA_ADAS
 SG_ RR_CAN_DET_CONFID_AZIMUTH_047 : 289|2@0+ (1,0) [0|3] ""  IPMA_ADAS
 SG_ RR_CAN_DET_RANGE_RATE_047 : 271|14@0+ (0.015625,-128) [-128|127.984375] "m/s"  IPMA_ADAS
 SG_ RR_CAN_SCAN_INDEX_2LSB_047 : 273|2@0+ (1,0) [0|3] ""  IPMA_ADAS
 SG_ RR_CAN_DET_AMPLITUDE_047 : 263|7@0+ (1,-64) [-64|63] "dBsm"  IPMA_ADAS
 SG_ RR_CAN_DET_VALID_LEVEL_047 : 256|1@0+ (1,0) [0|1] ""  IPMA_ADAS
 SG_ RR_CAN_DET_ELEVATION_046 : 255|7@0+ (0.157449,-9.99812) [-9.99812|9.997903] "deg"  IPMA_ADAS
 SG_ RR_CAN_DET_SUPER_RES_TARGET_046 : 248|1@0+ (1,0) [0|1] ""  IPMA_ADAS
 SG_ RR_CAN_DET_AZIMUTH_046 : 239|14@0+ (0.021967,-180) [-180|179.885361] "deg"  IPMA_ADAS
 SG_ RR_CAN_DET_CONFID_ELEVATION_046 : 241|1@0+ (1,0) [0|1] ""  IPMA_ADAS
 SG_ RR_CAN_DET_HOST_VEH_CLUTTER_046 : 240|1@0+ (1,0) [0|1] ""  IPMA_ADAS
 SG_ RR_CAN_DET_RANGE_046 : 223|14@0+ (0.015625,0) [0|255.984375] "m"  IPMA_ADAS
 SG_ RR_CAN_DET_CONFID_AZIMUTH_046 : 225|2@0+ (1,0) [0|3] ""  IPMA_ADAS
 SG_ RR_CAN_DET_RANGE_RATE_046 : 207|14@0+ (0.015625,-128) [-128|127.984375] "m/s"  IPMA_ADAS
 SG_ RR_CAN_SCAN_INDEX_2LSB_046 : 209|2@0+ (1,0) [0|3] ""  IPMA_ADAS
 SG_ RR_CAN_DET_AMPLITUDE_046 : 199|7@0+ (1,-64) [-64|63] "dBsm"  IPMA_ADAS
 SG_ RR_CAN_DET_VALID_LEVEL_046 : 192|1@0+ (1,0) [0|1] ""  IPMA_ADAS
 SG_ RR_CAN_DET_ELEVATION_045 : 191|7@0+ (0.157449,-9.99812) [-9.99812|9.997903] "deg"  IPMA_ADAS
 SG_ RR_CAN_DET_SUPER_RES_TARGET_045 : 184|1@0+ (1,0) [0|1] ""  IPMA_ADAS
 SG_ RR_CAN_DET_AZIMUTH_045 : 175|14@0+ (0.021967,-180) [-180|179.885361] "deg"  IPMA_ADAS
 SG_ RR_CAN_DET_CONFID_ELEVATION_045 : 177|1@0+ (1,0) [0|1] ""  IPMA_ADAS
 SG_ RR_CAN_DET_HOST_VEH_CLUTTER_045 : 176|1@0+ (1,0) [0|1] ""  IPMA_ADAS
 SG_ RR_CAN_DET_RANGE_045 : 159|14@0+ (0.015625,0) [0|255.984375] "m"  IPMA_ADAS
 SG_ RR_CAN_DET_CONFID_AZIMUTH_045 : 161|2@0+ (1,0) [0|3] ""  IPMA_ADAS
 SG_ RR_CAN_DET_RANGE_RATE_045 : 143|14@0+ (0.015625,-128) [-128|127.984375] "m/s"  IPMA_ADAS
 SG_ RR_CAN_SCAN_INDEX_2LSB_045 : 145|2@0+ (1,0) [0|3] ""  IPMA_ADAS
 SG_ RR_CAN_DET_AMPLITUDE_045 : 135|7@0+ (1,-64) [-64|63] "dBsm"  IPMA_ADAS
 SG_ RR_CAN_DET_VALID_LEVEL_045 : 128|1@0+ (1,0) [0|1] ""  IPMA_ADAS
 SG_ RR_CAN_DET_ELEVATION_044 : 127|7@0+ (0.157449,-9.99812) [-9.99812|9.997903] "deg"  IPMA_ADAS
 SG_ RR_CAN_DET_SUPER_RES_TARGET_044 : 120|1@0+ (1,0) [0|1] ""  IPMA_ADAS
 SG_ RR_CAN_DET_AZIMUTH_044 : 111|14@0+ (0.021967,-180) [-180|179.885361] "deg"  IPMA_ADAS
 SG_ RR_CAN_DET_CONFID_ELEVATION_044 : 113|1@0+ (1,0) [0|1] ""  IPMA_ADAS
 SG_ RR_CAN_DET_HOST_VEH_CLUTTER_044 : 112|1@0+ (1,0) [0|1] ""  IPMA_ADAS
 SG_ RR_CAN_DET_RANGE_044 : 95|14@0+ (0.015625,0) [0|255.984375] "m"  IPMA_ADAS
 SG_ RR_CAN_DET_CONFID_AZIMUTH_044 : 97|2@0+ (1,0) [0|3] ""  IPMA_ADAS
 SG_ RR_CAN_DET_RANGE_RATE_044 : 79|14@0+ (0.015625,-128) [-128|127.984375] "m/s"  IPMA_ADAS
 SG_ RR_CAN_SCAN_INDEX_2LSB_044 : 81|2@0+ (1,0) [0|3] ""  IPMA_ADAS
 SG_ RR_CAN_DET_AMPLITUDE_044 : 71|7@0+ (1,-64) [-64|63] "dBsm"  IPMA_ADAS
 SG_ RR_CAN_DET_VALID_LEVEL_044 : 64|1@0+ (1,0) [0|1] ""  IPMA_ADAS

BO_ 1031 RR_Detection_050_056: 64 SODRR
 SG_ RR_CAN_DET_ELEVATION_050 : 63|7@0+ (0.157449,-9.99812) [-9.99812|9.997903] "deg"  IPMA_ADAS
 SG_ RR_CAN_DET_CONFID_AZIMUTH_050 : 33|2@0+ (1,0) [0|3] ""  IPMA_ADAS
 SG_ RR_CAN_DET_SUPER_RES_TARGET_050 : 56|1@0+ (1,0) [0|1] ""  IPMA_ADAS
 SG_ RR_CAN_DET_CONFID_ELEVATION_050 : 49|1@0+ (1,0) [0|1] ""  IPMA_ADAS
 SG_ RR_CAN_DET_HOST_VEH_CLUTTER_050 : 48|1@0+ (1,0) [0|1] ""  IPMA_ADAS
 SG_ RR_CAN_DET_VALID_LEVEL_050 : 0|1@0+ (1,0) [0|1] ""  IPMA_ADAS
 SG_ RR_CAN_DET_AZIMUTH_050 : 47|14@0+ (0.021967,-180) [-180|179.885361] "deg"  IPMA_ADAS
 SG_ RR_CAN_DET_RANGE_050 : 31|14@0+ (0.015625,0) [0|255.984375] "m"  IPMA_ADAS
 SG_ RR_CAN_DET_RANGE_RATE_050 : 15|14@0+ (0.015625,-128) [-128|127.984375] "m/s"  IPMA_ADAS
 SG_ RR_CAN_DET_AMPLITUDE_050 : 7|7@0+ (1,-64) [-64|63] "dBsm"  IPMA_ADAS
 SG_ RR_CAN_SCAN_INDEX_2LSB_050 : 17|2@0+ (1,0) [0|3] ""  IPMA_ADAS
 SG_ RR_DET_MC_008 : 451|4@0+ (1,0) [0|0] ""  IPMA_ADAS
 SG_ RR_DET_CRC_008 : 463|16@0+ (1,0) [0|0] ""  IPMA_ADAS
 SG_ RR_CAN_DET_ELEVATION_056 : 447|7@0+ (0.157449,-9.99812) [-9.99812|9.997903] "deg"  IPMA_ADAS
 SG_ RR_CAN_DET_SUPER_RES_TARGET_056 : 440|1@0+ (1,0) [0|1] ""  IPMA_ADAS
 SG_ RR_CAN_DET_AZIMUTH_056 : 431|14@0+ (0.021967,-180) [-180|179.885361] "deg"  IPMA_ADAS
 SG_ RR_CAN_DET_CONFID_ELEVATION_056 : 433|1@0+ (1,0) [0|1] ""  IPMA_ADAS
 SG_ RR_CAN_DET_HOST_VEH_CLUTTER_056 : 432|1@0+ (1,0) [0|1] ""  IPMA_ADAS
 SG_ RR_CAN_DET_RANGE_056 : 415|14@0+ (0.015625,0) [0|255.984375] "m"  IPMA_ADAS
 SG_ RR_CAN_DET_CONFID_AZIMUTH_056 : 417|2@0+ (1,0) [0|3] ""  IPMA_ADAS
 SG_ RR_CAN_DET_RANGE_RATE_056 : 399|14@0+ (0.015625,-128) [-128|127.984375] "m/s"  IPMA_ADAS
 SG_ RR_CAN_SCAN_INDEX_2LSB_056 : 401|2@0+ (1,0) [0|3] ""  IPMA_ADAS
 SG_ RR_CAN_DET_AMPLITUDE_056 : 391|7@0+ (1,-64) [-64|63] "dBsm"  IPMA_ADAS
 SG_ RR_CAN_DET_VALID_LEVEL_056 : 384|1@0+ (1,0) [0|1] ""  IPMA_ADAS
 SG_ RR_CAN_DET_ELEVATION_055 : 383|7@0+ (0.157449,-9.99812) [-9.99812|9.997903] "deg"  IPMA_ADAS
 SG_ RR_CAN_DET_SUPER_RES_TARGET_055 : 376|1@0+ (1,0) [0|1] ""  IPMA_ADAS
 SG_ RR_CAN_DET_AZIMUTH_055 : 367|14@0+ (0.021967,-180) [-180|179.885361] "deg"  IPMA_ADAS
 SG_ RR_CAN_DET_CONFID_ELEVATION_055 : 369|1@0+ (1,0) [0|1] ""  IPMA_ADAS
 SG_ RR_CAN_DET_HOST_VEH_CLUTTER_055 : 368|1@0+ (1,0) [0|1] ""  IPMA_ADAS
 SG_ RR_CAN_DET_RANGE_055 : 351|14@0+ (0.015625,0) [0|255.984375] "m"  IPMA_ADAS
 SG_ RR_CAN_DET_CONFID_AZIMUTH_055 : 353|2@0+ (1,0) [0|3] ""  IPMA_ADAS
 SG_ RR_CAN_DET_RANGE_RATE_055 : 335|14@0+ (0.015625,-128) [-128|127.984375] "m/s"  IPMA_ADAS
 SG_ RR_CAN_SCAN_INDEX_2LSB_055 : 337|2@0+ (1,0) [0|3] ""  IPMA_ADAS
 SG_ RR_CAN_DET_AMPLITUDE_055 : 327|7@0+ (1,-64) [-64|63] "dBsm"  IPMA_ADAS
 SG_ RR_CAN_DET_VALID_LEVEL_055 : 320|1@0+ (1,0) [0|1] ""  IPMA_ADAS
 SG_ RR_CAN_DET_ELEVATION_054 : 319|7@0+ (0.157449,-9.99812) [-9.99812|9.997903] "deg"  IPMA_ADAS
 SG_ RR_CAN_DET_SUPER_RES_TARGET_054 : 312|1@0+ (1,0) [0|1] ""  IPMA_ADAS
 SG_ RR_CAN_DET_AZIMUTH_054 : 303|14@0+ (0.021967,-180) [-180|179.885361] "deg"  IPMA_ADAS
 SG_ RR_CAN_DET_CONFID_ELEVATION_054 : 305|1@0+ (1,0) [0|1] ""  IPMA_ADAS
 SG_ RR_CAN_DET_HOST_VEH_CLUTTER_054 : 304|1@0+ (1,0) [0|1] ""  IPMA_ADAS
 SG_ RR_CAN_DET_RANGE_054 : 287|14@0+ (0.015625,0) [0|255.984375] "m"  IPMA_ADAS
 SG_ RR_CAN_DET_CONFID_AZIMUTH_054 : 289|2@0+ (1,0) [0|3] ""  IPMA_ADAS
 SG_ RR_CAN_DET_RANGE_RATE_054 : 271|14@0+ (0.015625,-128) [-128|127.984375] "m/s"  IPMA_ADAS
 SG_ RR_CAN_SCAN_INDEX_2LSB_054 : 273|2@0+ (1,0) [0|3] ""  IPMA_ADAS
 SG_ RR_CAN_DET_AMPLITUDE_054 : 263|7@0+ (1,-64) [-64|63] "dBsm"  IPMA_ADAS
 SG_ RR_CAN_DET_VALID_LEVEL_054 : 256|1@0+ (1,0) [0|1] ""  IPMA_ADAS
 SG_ RR_CAN_DET_ELEVATION_053 : 255|7@0+ (0.157449,-9.99812) [-9.99812|9.997903] "deg"  IPMA_ADAS
 SG_ RR_CAN_DET_SUPER_RES_TARGET_053 : 248|1@0+ (1,0) [0|1] ""  IPMA_ADAS
 SG_ RR_CAN_DET_AZIMUTH_053 : 239|14@0+ (0.021967,-180) [-180|179.885361] "deg"  IPMA_ADAS
 SG_ RR_CAN_DET_CONFID_ELEVATION_053 : 241|1@0+ (1,0) [0|1] ""  IPMA_ADAS
 SG_ RR_CAN_DET_HOST_VEH_CLUTTER_053 : 240|1@0+ (1,0) [0|1] ""  IPMA_ADAS
 SG_ RR_CAN_DET_RANGE_053 : 223|14@0+ (0.015625,0) [0|255.984375] "m"  IPMA_ADAS
 SG_ RR_CAN_DET_CONFID_AZIMUTH_053 : 225|2@0+ (1,0) [0|3] ""  IPMA_ADAS
 SG_ RR_CAN_DET_RANGE_RATE_053 : 207|14@0+ (0.015625,-128) [-128|127.984375] "m/s"  IPMA_ADAS
 SG_ RR_CAN_SCAN_INDEX_2LSB_053 : 209|2@0+ (1,0) [0|3] ""  IPMA_ADAS
 SG_ RR_CAN_DET_AMPLITUDE_053 : 199|7@0+ (1,-64) [-64|63] "dBsm"  IPMA_ADAS
 SG_ RR_CAN_DET_VALID_LEVEL_053 : 192|1@0+ (1,0) [0|1] ""  IPMA_ADAS
 SG_ RR_CAN_DET_ELEVATION_052 : 191|7@0+ (0.157449,-9.99812) [-9.99812|9.997903] "deg"  IPMA_ADAS
 SG_ RR_CAN_DET_SUPER_RES_TARGET_052 : 184|1@0+ (1,0) [0|1] ""  IPMA_ADAS
 SG_ RR_CAN_DET_AZIMUTH_052 : 175|14@0+ (0.021967,-180) [-180|179.885361] "deg"  IPMA_ADAS
 SG_ RR_CAN_DET_CONFID_ELEVATION_052 : 177|1@0+ (1,0) [0|1] ""  IPMA_ADAS
 SG_ RR_CAN_DET_HOST_VEH_CLUTTER_052 : 176|1@0+ (1,0) [0|1] ""  IPMA_ADAS
 SG_ RR_CAN_DET_RANGE_052 : 159|14@0+ (0.015625,0) [0|255.984375] "m"  IPMA_ADAS
 SG_ RR_CAN_DET_CONFID_AZIMUTH_052 : 161|2@0+ (1,0) [0|3] ""  IPMA_ADAS
 SG_ RR_CAN_DET_RANGE_RATE_052 : 143|14@0+ (0.015625,-128) [-128|127.984375] "m/s"  IPMA_ADAS
 SG_ RR_CAN_SCAN_INDEX_2LSB_052 : 145|2@0+ (1,0) [0|3] ""  IPMA_ADAS
 SG_ RR_CAN_DET_AMPLITUDE_052 : 135|7@0+ (1,-64) [-64|63] "dBsm"  IPMA_ADAS
 SG_ RR_CAN_DET_VALID_LEVEL_052 : 128|1@0+ (1,0) [0|1] ""  IPMA_ADAS
 SG_ RR_CAN_DET_ELEVATION_051 : 127|7@0+ (0.157449,-9.99812) [-9.99812|9.997903] "deg"  IPMA_ADAS
 SG_ RR_CAN_DET_SUPER_RES_TARGET_051 : 120|1@0+ (1,0) [0|1] ""  IPMA_ADAS
 SG_ RR_CAN_DET_AZIMUTH_051 : 111|14@0+ (0.021967,-180) [-180|179.885361] "deg"  IPMA_ADAS
 SG_ RR_CAN_DET_CONFID_ELEVATION_051 : 113|1@0+ (1,0) [0|1] ""  IPMA_ADAS
 SG_ RR_CAN_DET_HOST_VEH_CLUTTER_051 : 112|1@0+ (1,0) [0|1] ""  IPMA_ADAS
 SG_ RR_CAN_DET_RANGE_051 : 95|14@0+ (0.015625,0) [0|255.984375] "m"  IPMA_ADAS
 SG_ RR_CAN_DET_CONFID_AZIMUTH_051 : 97|2@0+ (1,0) [0|3] ""  IPMA_ADAS
 SG_ RR_CAN_DET_RANGE_RATE_051 : 79|14@0+ (0.015625,-128) [-128|127.984375] "m/s"  IPMA_ADAS
 SG_ RR_CAN_SCAN_INDEX_2LSB_051 : 81|2@0+ (1,0) [0|3] ""  IPMA_ADAS
 SG_ RR_CAN_DET_AMPLITUDE_051 : 71|7@0+ (1,-64) [-64|63] "dBsm"  IPMA_ADAS
 SG_ RR_CAN_DET_VALID_LEVEL_051 : 64|1@0+ (1,0) [0|1] ""  IPMA_ADAS

BO_ 1032 RR_Detection_057_063: 64 SODRR
 SG_ RR_CAN_DET_ELEVATION_057 : 63|7@0+ (0.157449,-9.99812) [-9.99812|9.997903] "deg"  IPMA_ADAS
 SG_ RR_CAN_DET_CONFID_AZIMUTH_057 : 33|2@0+ (1,0) [0|3] ""  IPMA_ADAS
 SG_ RR_CAN_DET_SUPER_RES_TARGET_057 : 56|1@0+ (1,0) [0|1] ""  IPMA_ADAS
 SG_ RR_CAN_DET_CONFID_ELEVATION_057 : 49|1@0+ (1,0) [0|1] ""  IPMA_ADAS
 SG_ RR_CAN_DET_HOST_VEH_CLUTTER_057 : 48|1@0+ (1,0) [0|1] ""  IPMA_ADAS
 SG_ RR_CAN_DET_VALID_LEVEL_057 : 0|1@0+ (1,0) [0|1] ""  IPMA_ADAS
 SG_ RR_CAN_DET_AZIMUTH_057 : 47|14@0+ (0.021967,-180) [-180|179.885361] "deg"  IPMA_ADAS
 SG_ RR_CAN_DET_RANGE_057 : 31|14@0+ (0.015625,0) [0|255.984375] "m"  IPMA_ADAS
 SG_ RR_CAN_DET_RANGE_RATE_057 : 15|14@0+ (0.015625,-128) [-128|127.984375] "m/s"  IPMA_ADAS
 SG_ RR_CAN_DET_AMPLITUDE_057 : 7|7@0+ (1,-64) [-64|63] "dBsm"  IPMA_ADAS
 SG_ RR_CAN_SCAN_INDEX_2LSB_057 : 17|2@0+ (1,0) [0|3] ""  IPMA_ADAS
 SG_ RR_DET_MC_009 : 451|4@0+ (1,0) [0|0] ""  IPMA_ADAS
 SG_ RR_DET_CRC_009 : 463|16@0+ (1,0) [0|0] ""  IPMA_ADAS
 SG_ RR_CAN_DET_ELEVATION_063 : 447|7@0+ (0.157449,-9.99812) [-9.99812|9.997903] "deg"  IPMA_ADAS
 SG_ RR_CAN_DET_SUPER_RES_TARGET_063 : 440|1@0+ (1,0) [0|1] ""  IPMA_ADAS
 SG_ RR_CAN_DET_AZIMUTH_063 : 431|14@0+ (0.021967,-180) [-180|179.885361] "deg"  IPMA_ADAS
 SG_ RR_CAN_DET_CONFID_ELEVATION_063 : 433|1@0+ (1,0) [0|1] ""  IPMA_ADAS
 SG_ RR_CAN_DET_HOST_VEH_CLUTTER_063 : 432|1@0+ (1,0) [0|1] ""  IPMA_ADAS
 SG_ RR_CAN_DET_RANGE_063 : 415|14@0+ (0.015625,0) [0|255.984375] "m"  IPMA_ADAS
 SG_ RR_CAN_DET_CONFID_AZIMUTH_063 : 417|2@0+ (1,0) [0|3] ""  IPMA_ADAS
 SG_ RR_CAN_DET_RANGE_RATE_063 : 399|14@0+ (0.015625,-128) [-128|127.984375] "m/s"  IPMA_ADAS
 SG_ RR_CAN_SCAN_INDEX_2LSB_063 : 401|2@0+ (1,0) [0|3] ""  IPMA_ADAS
 SG_ RR_CAN_DET_AMPLITUDE_063 : 391|7@0+ (1,-64) [-64|63] "dBsm"  IPMA_ADAS
 SG_ RR_CAN_DET_VALID_LEVEL_063 : 384|1@0+ (1,0) [0|1] ""  IPMA_ADAS
 SG_ RR_CAN_DET_ELEVATION_062 : 383|7@0+ (0.157449,-9.99812) [-9.99812|9.997903] "deg"  IPMA_ADAS
 SG_ RR_CAN_DET_SUPER_RES_TARGET_062 : 376|1@0+ (1,0) [0|1] ""  IPMA_ADAS
 SG_ RR_CAN_DET_AZIMUTH_062 : 367|14@0+ (0.021967,-180) [-180|179.885361] "deg"  IPMA_ADAS
 SG_ RR_CAN_DET_CONFID_ELEVATION_062 : 369|1@0+ (1,0) [0|1] ""  IPMA_ADAS
 SG_ RR_CAN_DET_HOST_VEH_CLUTTER_062 : 368|1@0+ (1,0) [0|1] ""  IPMA_ADAS
 SG_ RR_CAN_DET_RANGE_062 : 351|14@0+ (0.015625,0) [0|255.984375] "m"  IPMA_ADAS
 SG_ RR_CAN_DET_CONFID_AZIMUTH_062 : 353|2@0+ (1,0) [0|3] ""  IPMA_ADAS
 SG_ RR_CAN_DET_RANGE_RATE_062 : 335|14@0+ (0.015625,-128) [-128|127.984375] "m/s"  IPMA_ADAS
 SG_ RR_CAN_SCAN_INDEX_2LSB_062 : 337|2@0+ (1,0) [0|3] ""  IPMA_ADAS
 SG_ RR_CAN_DET_AMPLITUDE_062 : 327|7@0+ (1,-64) [-64|63] "dBsm"  IPMA_ADAS
 SG_ RR_CAN_DET_VALID_LEVEL_062 : 320|1@0+ (1,0) [0|1] ""  IPMA_ADAS
 SG_ RR_CAN_DET_ELEVATION_061 : 319|7@0+ (0.157449,-9.99812) [-9.99812|9.997903] "deg"  IPMA_ADAS
 SG_ RR_CAN_DET_SUPER_RES_TARGET_061 : 312|1@0+ (1,0) [0|1] ""  IPMA_ADAS
 SG_ RR_CAN_DET_AZIMUTH_061 : 303|14@0+ (0.021967,-180) [-180|179.885361] "deg"  IPMA_ADAS
 SG_ RR_CAN_DET_CONFID_ELEVATION_061 : 305|1@0+ (1,0) [0|1] ""  IPMA_ADAS
 SG_ RR_CAN_DET_HOST_VEH_CLUTTER_061 : 304|1@0+ (1,0) [0|1] ""  IPMA_ADAS
 SG_ RR_CAN_DET_RANGE_061 : 287|14@0+ (0.015625,0) [0|255.984375] "m"  IPMA_ADAS
 SG_ RR_CAN_DET_CONFID_AZIMUTH_061 : 289|2@0+ (1,0) [0|3] ""  IPMA_ADAS
 SG_ RR_CAN_DET_RANGE_RATE_061 : 271|14@0+ (0.015625,-128) [-128|127.984375] "m/s"  IPMA_ADAS
 SG_ RR_CAN_SCAN_INDEX_2LSB_061 : 273|2@0+ (1,0) [0|3] ""  IPMA_ADAS
 SG_ RR_CAN_DET_AMPLITUDE_061 : 263|7@0+ (1,-64) [-64|63] "dBsm"  IPMA_ADAS
 SG_ RR_CAN_DET_VALID_LEVEL_061 : 256|1@0+ (1,0) [0|1] ""  IPMA_ADAS
 SG_ RR_CAN_DET_ELEVATION_060 : 255|7@0+ (0.157449,-9.99812) [-9.99812|9.997903] "deg"  IPMA_ADAS
 SG_ RR_CAN_DET_SUPER_RES_TARGET_060 : 248|1@0+ (1,0) [0|1] ""  IPMA_ADAS
 SG_ RR_CAN_DET_AZIMUTH_060 : 239|14@0+ (0.021967,-180) [-180|179.885361] "deg"  IPMA_ADAS
 SG_ RR_CAN_DET_CONFID_ELEVATION_060 : 241|1@0+ (1,0) [0|1] ""  IPMA_ADAS
 SG_ RR_CAN_DET_HOST_VEH_CLUTTER_060 : 240|1@0+ (1,0) [0|1] ""  IPMA_ADAS
 SG_ RR_CAN_DET_RANGE_060 : 223|14@0+ (0.015625,0) [0|255.984375] "m"  IPMA_ADAS
 SG_ RR_CAN_DET_CONFID_AZIMUTH_060 : 225|2@0+ (1,0) [0|3] ""  IPMA_ADAS
 SG_ RR_CAN_DET_RANGE_RATE_060 : 207|14@0+ (0.015625,-128) [-128|127.984375] "m/s"  IPMA_ADAS
 SG_ RR_CAN_SCAN_INDEX_2LSB_060 : 209|2@0+ (1,0) [0|3] ""  IPMA_ADAS
 SG_ RR_CAN_DET_AMPLITUDE_060 : 199|7@0+ (1,-64) [-64|63] "dBsm"  IPMA_ADAS
 SG_ RR_CAN_DET_VALID_LEVEL_060 : 192|1@0+ (1,0) [0|1] ""  IPMA_ADAS
 SG_ RR_CAN_DET_ELEVATION_059 : 191|7@0+ (0.157449,-9.99812) [-9.99812|9.997903] "deg"  IPMA_ADAS
 SG_ RR_CAN_DET_SUPER_RES_TARGET_059 : 184|1@0+ (1,0) [0|1] ""  IPMA_ADAS
 SG_ RR_CAN_DET_AZIMUTH_059 : 175|14@0+ (0.021967,-180) [-180|179.885361] "deg"  IPMA_ADAS
 SG_ RR_CAN_DET_CONFID_ELEVATION_059 : 177|1@0+ (1,0) [0|1] ""  IPMA_ADAS
 SG_ RR_CAN_DET_HOST_VEH_CLUTTER_059 : 176|1@0+ (1,0) [0|1] ""  IPMA_ADAS
 SG_ RR_CAN_DET_RANGE_059 : 159|14@0+ (0.015625,0) [0|255.984375] "m"  IPMA_ADAS
 SG_ RR_CAN_DET_CONFID_AZIMUTH_059 : 161|2@0+ (1,0) [0|3] ""  IPMA_ADAS
 SG_ RR_CAN_DET_RANGE_RATE_059 : 143|14@0+ (0.015625,-128) [-128|127.984375] "m/s"  IPMA_ADAS
 SG_ RR_CAN_SCAN_INDEX_2LSB_059 : 145|2@0+ (1,0) [0|3] ""  IPMA_ADAS
 SG_ RR_CAN_DET_AMPLITUDE_059 : 135|7@0+ (1,-64) [-64|63] "dBsm"  IPMA_ADAS
 SG_ RR_CAN_DET_VALID_LEVEL_059 : 128|1@0+ (1,0) [0|1] ""  IPMA_ADAS
 SG_ RR_CAN_DET_ELEVATION_058 : 127|7@0+ (0.157449,-9.99812) [-9.99812|9.997903] "deg"  IPMA_ADAS
 SG_ RR_CAN_DET_SUPER_RES_TARGET_058 : 120|1@0+ (1,0) [0|1] ""  IPMA_ADAS
 SG_ RR_CAN_DET_AZIMUTH_058 : 111|14@0+ (0.021967,-180) [-180|179.885361] "deg"  IPMA_ADAS
 SG_ RR_CAN_DET_CONFID_ELEVATION_058 : 113|1@0+ (1,0) [0|1] ""  IPMA_ADAS
 SG_ RR_CAN_DET_HOST_VEH_CLUTTER_058 : 112|1@0+ (1,0) [0|1] ""  IPMA_ADAS
 SG_ RR_CAN_DET_RANGE_058 : 95|14@0+ (0.015625,0) [0|255.984375] "m"  IPMA_ADAS
 SG_ RR_CAN_DET_CONFID_AZIMUTH_058 : 97|2@0+ (1,0) [0|3] ""  IPMA_ADAS
 SG_ RR_CAN_DET_RANGE_RATE_058 : 79|14@0+ (0.015625,-128) [-128|127.984375] "m/s"  IPMA_ADAS
 SG_ RR_CAN_SCAN_INDEX_2LSB_058 : 81|2@0+ (1,0) [0|3] ""  IPMA_ADAS
 SG_ RR_CAN_DET_AMPLITUDE_058 : 71|7@0+ (1,-64) [-64|63] "dBsm"  IPMA_ADAS
 SG_ RR_CAN_DET_VALID_LEVEL_058 : 64|1@0+ (1,0) [0|1] ""  IPMA_ADAS

BO_ 1033 RR_Detection_064: 12 SODRR
 SG_ RR_DET_MC_010 : 67|4@0+ (1,0) [0|0] ""  IPMA_ADAS
 SG_ RR_DET_CRC_010 : 79|16@0+ (1,0) [0|0] ""  IPMA_ADAS
 SG_ RR_CAN_DET_ELEVATION_064 : 63|7@0+ (0.157449,-9.99812) [-9.99812|9.997903] "deg"  IPMA_ADAS
 SG_ RR_CAN_DET_CONFID_AZIMUTH_064 : 33|2@0+ (1,0) [0|3] ""  IPMA_ADAS
 SG_ RR_CAN_DET_SUPER_RES_TARGET_064 : 56|1@0+ (1,0) [0|1] ""  IPMA_ADAS
 SG_ RR_CAN_DET_CONFID_ELEVATION_064 : 49|1@0+ (1,0) [0|1] ""  IPMA_ADAS
 SG_ RR_CAN_DET_HOST_VEH_CLUTTER_064 : 48|1@0+ (1,0) [0|1] ""  IPMA_ADAS
 SG_ RR_CAN_DET_VALID_LEVEL_064 : 0|1@0+ (1,0) [0|1] ""  IPMA_ADAS
 SG_ RR_CAN_DET_AZIMUTH_064 : 47|14@0+ (0.021967,-180) [-180|179.885361] "deg"  IPMA_ADAS
 SG_ RR_CAN_DET_RANGE_064 : 31|14@0+ (0.015625,0) [0|255.984375] "m"  IPMA_ADAS
 SG_ RR_CAN_DET_RANGE_RATE_064 : 15|14@0+ (0.015625,-128) [-128|127.984375] "m/s"  IPMA_ADAS
 SG_ RR_CAN_DET_AMPLITUDE_064 : 7|7@0+ (1,-64) [-64|63] "dBsm"  IPMA_ADAS
 SG_ RR_CAN_SCAN_INDEX_2LSB_064 : 17|2@0+ (1,0) [0|3] ""  IPMA_ADAS

BO_ 1088 RR_TrackStatus: 8 SODRR
 SG_ RR_CAN_TX_LOOK_INDEX_8 : 31|8@0+ (1,0) [0|0] ""  IPMA_ADAS
 SG_ RR_CAN_TX_SCAN_INDEX_TRACKER_OWN : 23|8@0+ (1,0) [0|0] ""  IPMA_ADAS
 SG_ RR_CAN_TX_SCN_INDEX_TRKER_FUSED : 7|8@0+ (1,0) [0|0] ""  IPMA_ADAS
 SG_ RR_CAN_TX_LOOK_TYPE : 15|1@0+ (1,0) [0|0] ""  IPMA_ADAS
 SG_ RR_CAN_TX_LOOK_ID : 14|7@0+ (1,0) [0|0] ""  IPMA_ADAS
 SG_ RR_CAN_TX_SYSTEM_TIME_STAMP : 39|24@0+ (1,0) [0|16777215] "us"  IPMA_ADAS

BO_ 1988 RL_Diag_Req_Phys: 8 IPMA_ADAS
 SG_ RL_Req_Phys : 7|64@0+ (1,0) [0|0] ""  SODRL

BO_ 1990 RR_Diag_Req_Phys: 8 IPMA_ADAS
 SG_ RR_Req_Phys : 7|64@0+ (1,0) [0|0] ""  SODRR

BO_ 1996 RL_Diag_Resp_Phys: 8 SODRL
 SG_ RL_Resp_Phys : 7|64@0+ (1,0) [0|0] ""  IPMA_ADAS

BO_ 1998 RR_Diag_Resp_Phys: 8 SODRR
 SG_ RR_Resp_Phys : 7|64@0+ (1,0) [0|0] ""  IPMA_ADAS

BO_ 1778 FL_Diag_Req_Phys: 8 IPMA_ADAS
 SG_ FL_Req_Phys : 7|64@0+ (1,0) [0|0] ""  SODRL

BO_ 1779 FR_Diag_Req_Phys: 8 IPMA_ADAS
 SG_ FR_Req_Phys : 7|64@0+ (1,0) [0|0] ""  SODRR

BO_ 2015 Diag_Req_Func: 8 IPMA_ADAS
 SG_ Diag_Req_Func : 7|8@0+ (1,0) [0|0] ""  SODRL,SODRR

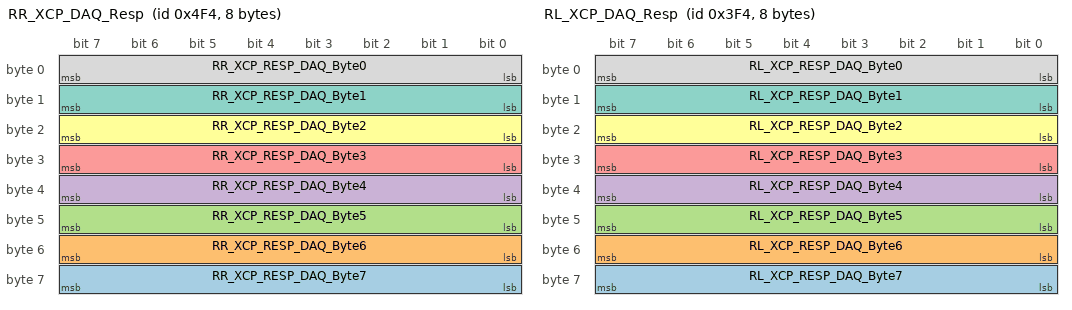
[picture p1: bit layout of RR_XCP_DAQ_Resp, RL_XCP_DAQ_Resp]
BO_ 1268 RR_XCP_DAQ_Resp: 8 SODRR
 SG_ RR_XCP_RESP_DAQ_Byte7 : 63|8@0+ (1,0) [0|0] ""  External_Tool
 SG_ RR_XCP_RESP_DAQ_Byte6 : 55|8@0+ (1,0) [0|0] ""  External_Tool
 SG_ RR_XCP_RESP_DAQ_Byte5 : 47|8@0+ (1,0) [0|0] ""  External_Tool
 SG_ RR_XCP_RESP_DAQ_Byte4 : 39|8@0+ (1,0) [0|0] ""  External_Tool
 SG_ RR_XCP_RESP_DAQ_Byte3 : 31|8@0+ (1,0) [0|0] ""  External_Tool
 SG_ RR_XCP_RESP_DAQ_Byte2 : 23|8@0+ (1,0) [0|0] ""  External_Tool
 SG_ RR_XCP_RESP_DAQ_Byte1 : 15|8@0+ (1,0) [0|0] ""  External_Tool
 SG_ RR_XCP_RESP_DAQ_Byte0 : 7|8@0+ (1,0) [0|0] ""  External_Tool

BO_ 1012 RL_XCP_DAQ_Resp: 8 SODRL
 SG_ RL_XCP_RESP_DAQ_Byte7 : 63|8@0+ (1,0) [0|0] ""  External_Tool
 SG_ RL_XCP_RESP_DAQ_Byte6 : 55|8@0+ (1,0) [0|0] ""  External_Tool
 SG_ RL_XCP_RESP_DAQ_Byte5 : 47|8@0+ (1,0) [0|0] ""  External_Tool
 SG_ RL_XCP_RESP_DAQ_Byte4 : 39|8@0+ (1,0) [0|0] ""  External_Tool
 SG_ RL_XCP_RESP_DAQ_Byte3 : 31|8@0+ (1,0) [0|0] ""  External_Tool
 SG_ RL_XCP_RESP_DAQ_Byte2 : 23|8@0+ (1,0) [0|0] ""  External_Tool
 SG_ RL_XCP_RESP_DAQ_Byte1 : 15|8@0+ (1,0) [0|0] ""  External_Tool
 SG_ RL_XCP_RESP_DAQ_Byte0 : 7|8@0+ (1,0) [0|0] ""  External_Tool

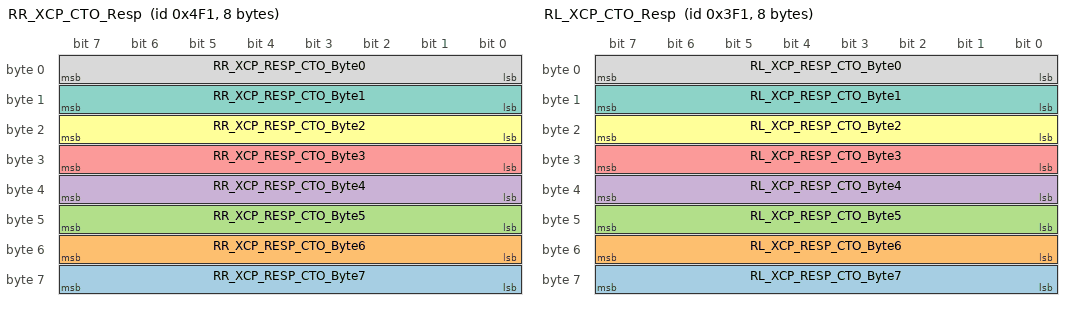
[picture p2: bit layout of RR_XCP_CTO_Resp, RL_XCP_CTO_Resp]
BO_ 1265 RR_XCP_CTO_Resp: 8 SODRR
 SG_ RR_XCP_RESP_CTO_Byte7 : 63|8@0+ (1,0) [0|0] ""  External_Tool
 SG_ RR_XCP_RESP_CTO_Byte6 : 55|8@0+ (1,0) [0|0] ""  External_Tool
 SG_ RR_XCP_RESP_CTO_Byte5 : 47|8@0+ (1,0) [0|0] ""  External_Tool
 SG_ RR_XCP_RESP_CTO_Byte4 : 39|8@0+ (1,0) [0|0] ""  External_Tool
 SG_ RR_XCP_RESP_CTO_Byte3 : 31|8@0+ (1,0) [0|0] ""  External_Tool
 SG_ RR_XCP_RESP_CTO_Byte2 : 23|8@0+ (1,0) [0|0] ""  External_Tool
 SG_ RR_XCP_RESP_CTO_Byte1 : 15|8@0+ (1,0) [0|0] ""  External_Tool
 SG_ RR_XCP_RESP_CTO_Byte0 : 7|8@0+ (1,0) [0|0] ""  External_Tool

BO_ 1009 RL_XCP_CTO_Resp: 8 SODRL
 SG_ RL_XCP_RESP_CTO_Byte7 : 63|8@0+ (1,0) [0|0] ""  External_Tool
 SG_ RL_XCP_RESP_CTO_Byte6 : 55|8@0+ (1,0) [0|0] ""  External_Tool
 SG_ RL_XCP_RESP_CTO_Byte5 : 47|8@0+ (1,0) [0|0] ""  External_Tool
 SG_ RL_XCP_RESP_CTO_Byte4 : 39|8@0+ (1,0) [0|0] ""  External_Tool
 SG_ RL_XCP_RESP_CTO_Byte3 : 31|8@0+ (1,0) [0|0] ""  External_Tool
 SG_ RL_XCP_RESP_CTO_Byte2 : 23|8@0+ (1,0) [0|0] ""  External_Tool
 SG_ RL_XCP_RESP_CTO_Byte1 : 15|8@0+ (1,0) [0|0] ""  External_Tool
 SG_ RL_XCP_RESP_CTO_Byte0 : 7|8@0+ (1,0) [0|0] ""  External_Tool

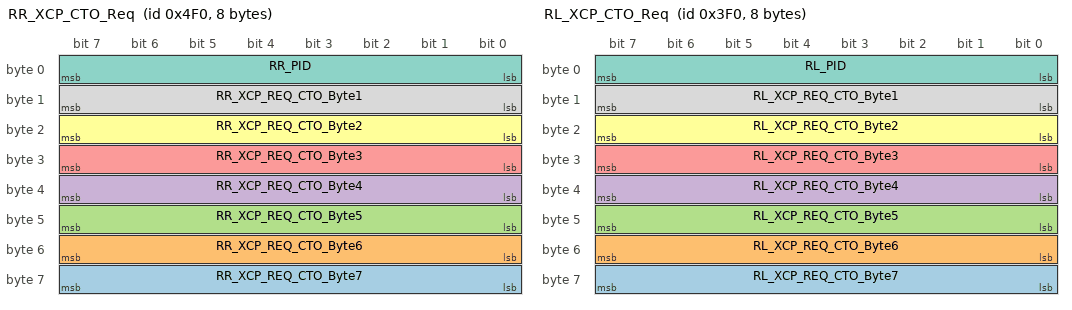
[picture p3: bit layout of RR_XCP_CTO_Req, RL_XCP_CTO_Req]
BO_ 1264 RR_XCP_CTO_Req: 8 External_Tool
 SG_ RR_XCP_REQ_CTO_Byte7 : 63|8@0+ (1,0) [0|0] ""  SODRR
 SG_ RR_XCP_REQ_CTO_Byte6 : 55|8@0+ (1,0) [0|0] ""  SODRR
 SG_ RR_XCP_REQ_CTO_Byte5 : 47|8@0+ (1,0) [0|0] ""  SODRR
 SG_ RR_XCP_REQ_CTO_Byte4 : 39|8@0+ (1,0) [0|0] ""  SODRR
 SG_ RR_XCP_REQ_CTO_Byte3 : 31|8@0+ (1,0) [0|0] ""  SODRR
 SG_ RR_XCP_REQ_CTO_Byte2 : 23|8@0+ (1,0) [0|0] ""  SODRR
 SG_ RR_PID : 7|8@0+ (1,0) [0|0] ""  SODRR
 SG_ RR_XCP_REQ_CTO_Byte1 : 15|8@0+ (1,0) [0|0] ""  SODRR

BO_ 1008 RL_XCP_CTO_Req: 8 External_Tool
 SG_ RL_XCP_REQ_CTO_Byte7 : 63|8@0+ (1,0) [0|0] ""  SODRL
 SG_ RL_XCP_REQ_CTO_Byte6 : 55|8@0+ (1,0) [0|0] ""  SODRL
 SG_ RL_XCP_REQ_CTO_Byte5 : 47|8@0+ (1,0) [0|0] ""  SODRL
 SG_ RL_XCP_REQ_CTO_Byte4 : 39|8@0+ (1,0) [0|0] ""  SODRL
 SG_ RL_XCP_REQ_CTO_Byte3 : 31|8@0+ (1,0) [0|0] ""  SODRL
 SG_ RL_XCP_REQ_CTO_Byte2 : 23|8@0+ (1,0) [0|0] ""  SODRL
 SG_ RL_PID : 7|8@0+ (1,0) [0|0] ""  SODRL
 SG_ RL_XCP_REQ_CTO_Byte1 : 15|8@0+ (1,0) [0|0] ""  SODRL

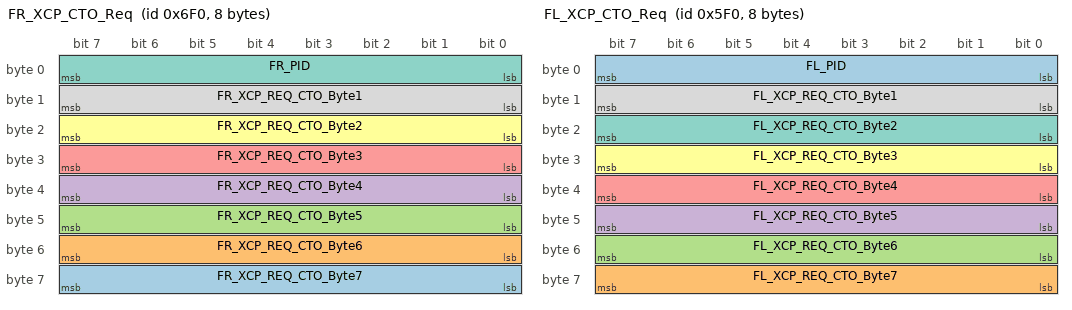
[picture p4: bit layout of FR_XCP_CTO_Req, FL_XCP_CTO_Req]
BO_ 1776 FR_XCP_CTO_Req: 8 External_Tool
 SG_ FR_XCP_REQ_CTO_Byte7 : 63|8@0+ (1,0) [0|0] ""  SODRR
 SG_ FR_XCP_REQ_CTO_Byte6 : 55|8@0+ (1,0) [0|0] ""  SODRR
 SG_ FR_XCP_REQ_CTO_Byte5 : 47|8@0+ (1,0) [0|0] ""  SODRR
 SG_ FR_XCP_REQ_CTO_Byte4 : 39|8@0+ (1,0) [0|0] ""  SODRR
 SG_ FR_XCP_REQ_CTO_Byte3 : 31|8@0+ (1,0) [0|0] ""  SODRR
 SG_ FR_XCP_REQ_CTO_Byte2 : 23|8@0+ (1,0) [0|0] ""  SODRR
 SG_ FR_PID : 7|8@0+ (1,0) [0|0] ""  SODRR
 SG_ FR_XCP_REQ_CTO_Byte1 : 15|8@0+ (1,0) [0|0] ""  SODRR

BO_ 1520 FL_XCP_CTO_Req: 8 External_Tool
 SG_ FL_PID : 7|8@0+ (1,0) [0|0] ""  SODRL
 SG_ FL_XCP_REQ_CTO_Byte7 : 63|8@0+ (1,0) [0|0] ""  SODRL
 SG_ FL_XCP_REQ_CTO_Byte6 : 55|8@0+ (1,0) [0|0] ""  SODRL
 SG_ FL_XCP_REQ_CTO_Byte5 : 47|8@0+ (1,0) [0|0] ""  SODRL
 SG_ FL_XCP_REQ_CTO_Byte4 : 39|8@0+ (1,0) [0|0] ""  SODRL
 SG_ FL_XCP_REQ_CTO_Byte3 : 31|8@0+ (1,0) [0|0] ""  SODRL
 SG_ FL_XCP_REQ_CTO_Byte2 : 23|8@0+ (1,0) [0|0] ""  SODRL
 SG_ FL_XCP_REQ_CTO_Byte1 : 15|8@0+ (1,0) [0|0] ""  SODRL

BA_DEF_ BO_  "VFrameFormat" ENUM  "StandardCAN","ExtendedCAN","reserved","reserved","reserved","reserved","reserved","reserved","reserved","reserved","reserved","reserved","reserved","reserved","StandardCAN_FD","ExtendedCAN_FD";
BA_DEF_ BO_  "DiagConnection" INT 0 65535;
BA_DEF_ BO_  "CanTpBs" INT 0 255;
BA_DEF_ BO_  "EventRateOfChange" INT 10 10000;
BA_DEF_ BO_  "DiagState" ENUM  "No","Yes";
BA_DEF_ BO_  "DiagRequest" ENUM  "No","Yes";
BA_DEF_ BO_  "DiagResponse" ENUM  "No","Yes";
BA_DEF_ SG_  "GenSigTimeoutTime_SRR01RR" INT 0 0;
BA_DEF_ SG_  "GenSigCycleTime" INT 0 0;
BA_DEF_ SG_  "GenSigVtName" STRING ;
BA_DEF_ SG_  "GenSigVtEn" STRING ;
BA_DEF_ SG_  "GenSigCmt" STRING ;
BA_DEF_ SG_  "GenSigSendType" ENUM  "Cyclic","OnWrite","OnChange","IfActive","NoSigSendType";
BA_DEF_ SG_  "GenSigInactiveValue" INT 0 100000;
BA_DEF_ SG_  "GenSigMissingSourceValue" INT 0 1000000000;
BA_DEF_ SG_  "GenSigStartValue" INT 0 1000000000;
BA_DEF_ BO_  "GenMsgILSupport" ENUM  "No","Yes";
BA_DEF_ BO_  "GenMsgSendType" ENUM  "FixedPeriodic","Event","EnabledPeriodic","EventPeriodic","NoMsgSendType";
BA_DEF_ BO_  "GenMsgCycleTime" INT 0 100000;
BA_DEF_ BO_  "GenMsgNrOfRepetition" INT 0 100;
BA_DEF_ BO_  "NetworkInitialization" ENUM  "No","Yes";
BA_DEF_DEF_  "VFrameFormat" "StandardCAN_FD";
BA_DEF_DEF_  "DiagConnection" 0;
BA_DEF_DEF_  "CanTpBs" 255;
BA_DEF_DEF_  "EventRateOfChange" 10000;
BA_DEF_DEF_  "DiagState" "No";
BA_DEF_DEF_  "DiagRequest" "No";
BA_DEF_DEF_  "DiagResponse" "No";
BA_DEF_DEF_  "GenSigTimeoutTime_SRR01RR" 0;
BA_DEF_DEF_  "GenSigCycleTime" 0;
BA_DEF_DEF_  "GenSigVtName" "";
BA_DEF_DEF_  "GenSigVtEn" "";
BA_DEF_DEF_  "GenSigCmt" "";
BA_DEF_DEF_  "GenSigSendType" "OnWrite";
BA_DEF_DEF_  "GenSigInactiveValue" 0;
BA_DEF_DEF_  "GenSigMissingSourceValue" 0;
BA_DEF_DEF_  "GenSigStartValue" 0;
BA_DEF_DEF_  "GenMsgILSupport" "Yes";
BA_DEF_DEF_  "GenMsgSendType" "NoMsgSendType";
BA_DEF_DEF_  "GenMsgCycleTime" 0;
BA_DEF_DEF_  "GenMsgNrOfRepetition" 0;
BA_DEF_DEF_  "NetworkInitialization" "Yes";
BA_ "GenMsgSendType" BO_ 776 1;
BA_ "GenMsgSendType" BO_ 777 1;
BA_ "GenMsgSendType" BO_ 832 1;
BA_ "GenMsgSendType" BO_ 1024 1;
BA_ "GenMsgSendType" BO_ 1025 1;
BA_ "GenMsgSendType" BO_ 1026 1;
BA_ "GenMsgSendType" BO_ 1027 1;
BA_ "GenMsgSendType" BO_ 1028 1;
BA_ "GenMsgSendType" BO_ 1029 1;
BA_ "GenMsgSendType" BO_ 1030 1;
BA_ "GenMsgSendType" BO_ 1031 1;
BA_ "GenMsgSendType" BO_ 1032 1;
BA_ "GenMsgSendType" BO_ 1033 1;
BA_ "GenMsgSendType" BO_ 1088 1;
BA_ "GenMsgSendType" BO_ 1988 1;
BA_ "DiagRequest" BO_ 1988 1;
BA_ "DiagConnection" BO_ 1988 1;
BA_ "GenMsgSendType" BO_ 1990 1;
BA_ "DiagRequest" BO_ 1990 1;
BA_ "DiagConnection" BO_ 1990 1;
BA_ "GenMsgSendType" BO_ 1996 1;
BA_ "DiagResponse" BO_ 1996 1;
BA_ "DiagConnection" BO_ 1996 1;
BA_ "GenMsgSendType" BO_ 1998 1;
BA_ "DiagResponse" BO_ 1998 1;
BA_ "DiagConnection" BO_ 1998 1;
BA_ "GenMsgSendType" BO_ 1778 1;
BA_ "DiagRequest" BO_ 1778 1;
BA_ "DiagConnection" BO_ 1778 2;
BA_ "GenMsgSendType" BO_ 1779 1;
BA_ "DiagRequest" BO_ 1779 1;
BA_ "DiagConnection" BO_ 1779 2;
BA_ "GenMsgSendType" BO_ 2015 1;
BA_ "DiagState" BO_ 2015 1;
BA_ "DiagRequest" BO_ 2015 1;
BA_ "GenMsgSendType" BO_ 1268 1;
BA_ "GenMsgSendType" BO_ 1012 1;
BA_ "GenMsgSendType" BO_ 1265 1;
BA_ "GenMsgSendType" BO_ 1009 1;
BA_ "GenMsgSendType" BO_ 1264 1;
BA_ "GenMsgSendType" BO_ 1008 1;
BA_ "GenMsgSendType" BO_ 1776 1;
BA_ "GenMsgSendType" BO_ 1520 1;
BA_ "GenSigCmt" SG_ 776 RL_CAN_DET_ELEVATION_057 "Detected object elevation position 01";
BA_ "GenSigStartValue" SG_ 776 RL_CAN_DET_ELEVATION_057 63.8646288209607;
BA_ "GenSigCmt" SG_ 776 RL_CAN_DET_CONFID_AZIMUTH_057 "Signal to noise level 01";
BA_ "GenSigVtName" SG_ 776 RL_CAN_DET_CONFID_AZIMUTH_057 "VtSig_CAN_SNR_LEVEL_01";
BA_ "GenSigVtEn" SG_ 776 RL_CAN_DET_CONFID_AZIMUTH_057 "TRUE";
BA_ "GenSigCmt" SG_ 776 RL_CAN_DET_SUPER_RES_TARGET_057 "Super resolution target 01";
BA_ "GenSigCmt" SG_ 776 RL_CAN_DET_CONFID_ELEVATION_057 "Near discrimination target 01";
BA_ "GenSigCmt" SG_ 776 RL_CAN_DET_HOST_VEH_CLUTTER_057 "Host vehicle clutter 01";
BA_ "GenSigCmt" SG_ 776 RL_CAN_DET_VALID_LEVEL_057 "Detected object valid level 01";
BA_ "GenSigCmt" SG_ 776 RL_CAN_DET_AZIMUTH_057 "Detected object azimuth position 01";
BA_ "GenSigStartValue" SG_ 776 RL_CAN_DET_AZIMUTH_057 8194.10934583694;
BA_ "GenSigCmt" SG_ 776 RL_CAN_DET_RANGE_057 "Detected object range 01";
BA_ "GenSigCmt" SG_ 776 RL_CAN_DET_RANGE_RATE_057 "Detected object range rate 01";
BA_ "GenSigStartValue" SG_ 776 RL_CAN_DET_RANGE_RATE_057 8192;
BA_ "GenSigCmt" SG_ 776 RL_CAN_DET_AMPLITUDE_057 "Detected object amplitude 01";
BA_ "GenSigStartValue" SG_ 776 RL_CAN_DET_AMPLITUDE_057 64;
BA_ "GenSigCmt" SG_ 776 RL_CAN_SCAN_INDEX_2LSB_057 "The two LSB of scan index 01";
BA_ "GenSigCmt" SG_ 776 RL_CAN_DET_ELEVATION_063 "Detected object elevation position 01";
BA_ "GenSigStartValue" SG_ 776 RL_CAN_DET_ELEVATION_063 63.8646288209607;
BA_ "GenSigCmt" SG_ 776 RL_CAN_DET_SUPER_RES_TARGET_063 "Super resolution target 01";
BA_ "GenSigCmt" SG_ 776 RL_CAN_DET_AZIMUTH_063 "Detected object azimuth position 01";
BA_ "GenSigStartValue" SG_ 776 RL_CAN_DET_AZIMUTH_063 8194.10934583694;
BA_ "GenSigCmt" SG_ 776 RL_CAN_DET_CONFID_ELEVATION_063 "Near discrimination target 01";
BA_ "GenSigCmt" SG_ 776 RL_CAN_DET_HOST_VEH_CLUTTER_063 "Host vehicle clutter 01";
BA_ "GenSigCmt" SG_ 776 RL_CAN_DET_RANGE_063 "Detected object range 01";
BA_ "GenSigVtName" SG_ 776 RL_CAN_DET_CONFID_AZIMUTH_063 "VtSig_CAN_SNR_LEVEL_01";
BA_ "GenSigVtEn" SG_ 776 RL_CAN_DET_CONFID_AZIMUTH_063 "TRUE";
BA_ "GenSigCmt" SG_ 776 RL_CAN_DET_CONFID_AZIMUTH_063 "Signal to noise level 01";
BA_ "GenSigCmt" SG_ 776 RL_CAN_DET_RANGE_RATE_063 "Detected object range rate 01";
BA_ "GenSigStartValue" SG_ 776 RL_CAN_DET_RANGE_RATE_063 8192;
BA_ "GenSigCmt" SG_ 776 RL_CAN_SCAN_INDEX_2LSB_063 "The two LSB of scan index 01";
BA_ "GenSigCmt" SG_ 776 RL_CAN_DET_AMPLITUDE_063 "Detected object amplitude 01";
BA_ "GenSigStartValue" SG_ 776 RL_CAN_DET_AMPLITUDE_063 64;
BA_ "GenSigCmt" SG_ 776 RL_CAN_DET_VALID_LEVEL_063 "Detected object valid level 01";
BA_ "GenSigCmt" SG_ 776 RL_CAN_DET_ELEVATION_062 "Detected object elevation position 01";
BA_ "GenSigStartValue" SG_ 776 RL_CAN_DET_ELEVATION_062 63.8646288209607;
BA_ "GenSigCmt" SG_ 776 RL_CAN_DET_SUPER_RES_TARGET_062 "Super resolution target 01";
BA_ "GenSigCmt" SG_ 776 RL_CAN_DET_AZIMUTH_062 "Detected object azimuth position 01";
BA_ "GenSigStartValue" SG_ 776 RL_CAN_DET_AZIMUTH_062 8194.10934583694;
BA_ "GenSigCmt" SG_ 776 RL_CAN_DET_CONFID_ELEVATION_062 "Near discrimination target 01";
BA_ "GenSigCmt" SG_ 776 RL_CAN_DET_HOST_VEH_CLUTTER_062 "Host vehicle clutter 01";
BA_ "GenSigCmt" SG_ 776 RL_CAN_DET_RANGE_062 "Detected object range 01";
BA_ "GenSigVtName" SG_ 776 RL_CAN_DET_CONFID_AZIMUTH_062 "VtSig_CAN_SNR_LEVEL_01";
BA_ "GenSigVtEn" SG_ 776 RL_CAN_DET_CONFID_AZIMUTH_062 "TRUE";
BA_ "GenSigCmt" SG_ 776 RL_CAN_DET_CONFID_AZIMUTH_062 "Signal to noise level 01";
BA_ "GenSigCmt" SG_ 776 RL_CAN_DET_RANGE_RATE_062 "Detected object range rate 01";
BA_ "GenSigStartValue" SG_ 776 RL_CAN_DET_RANGE_RATE_062 8192;
BA_ "GenSigCmt" SG_ 776 RL_CAN_SCAN_INDEX_2LSB_062 "The two LSB of scan index 01";
BA_ "GenSigCmt" SG_ 776 RL_CAN_DET_AMPLITUDE_062 "Detected object amplitude 01";
BA_ "GenSigStartValue" SG_ 776 RL_CAN_DET_AMPLITUDE_062 64;
BA_ "GenSigCmt" SG_ 776 RL_CAN_DET_VALID_LEVEL_062 "Detected object valid level 01";
BA_ "GenSigCmt" SG_ 776 RL_CAN_DET_ELEVATION_061 "Detected object elevation position 01";
BA_ "GenSigStartValue" SG_ 776 RL_CAN_DET_ELEVATION_061 63.8646288209607;
BA_ "GenSigCmt" SG_ 776 RL_CAN_DET_SUPER_RES_TARGET_061 "Super resolution target 01";
BA_ "GenSigCmt" SG_ 776 RL_CAN_DET_AZIMUTH_061 "Detected object azimuth position 01";
BA_ "GenSigStartValue" SG_ 776 RL_CAN_DET_AZIMUTH_061 8194.10934583694;
BA_ "GenSigCmt" SG_ 776 RL_CAN_DET_CONFID_ELEVATION_061 "Near discrimination target 01";
BA_ "GenSigCmt" SG_ 776 RL_CAN_DET_HOST_VEH_CLUTTER_061 "Host vehicle clutter 01";
BA_ "GenSigCmt" SG_ 776 RL_CAN_DET_RANGE_061 "Detected object range 01";
BA_ "GenSigVtName" SG_ 776 RL_CAN_DET_CONFID_AZIMUTH_061 "VtSig_CAN_SNR_LEVEL_01";
BA_ "GenSigVtEn" SG_ 776 RL_CAN_DET_CONFID_AZIMUTH_061 "TRUE";
BA_ "GenSigCmt" SG_ 776 RL_CAN_DET_CONFID_AZIMUTH_061 "Signal to noise level 01";
BA_ "GenSigCmt" SG_ 776 RL_CAN_DET_RANGE_RATE_061 "Detected object range rate 01";
BA_ "GenSigStartValue" SG_ 776 RL_CAN_DET_RANGE_RATE_061 8192;
BA_ "GenSigCmt" SG_ 776 RL_CAN_SCAN_INDEX_2LSB_061 "The two LSB of scan index 01";
BA_ "GenSigCmt" SG_ 776 RL_CAN_DET_AMPLITUDE_061 "Detected object amplitude 01



";
BA_ "GenSigStartValue" SG_ 776 RL_CAN_DET_AMPLITUDE_061 64;
BA_ "GenSigCmt" SG_ 776 RL_CAN_DET_VALID_LEVEL_061 "Detected object valid level 01";
BA_ "GenSigCmt" SG_ 776 RL_CAN_DET_ELEVATION_060 "Detected object elevation position 01";
BA_ "GenSigStartValue" SG_ 776 RL_CAN_DET_ELEVATION_060 63.8646288209607;
BA_ "GenSigCmt" SG_ 776 RL_CAN_DET_SUPER_RES_TARGET_060 "Super resolution target 01";
BA_ "GenSigCmt" SG_ 776 RL_CAN_DET_AZIMUTH_060 "Detected object azimuth position 01";
BA_ "GenSigStartValue" SG_ 776 RL_CAN_DET_AZIMUTH_060 8194.10934583694;
BA_ "GenSigCmt" SG_ 776 RL_CAN_DET_CONFID_ELEVATION_060 "Near discrimination target 01";
BA_ "GenSigCmt" SG_ 776 RL_CAN_DET_HOST_VEH_CLUTTER_060 "Host vehicle clutter 01";
BA_ "GenSigCmt" SG_ 776 RL_CAN_DET_RANGE_060 "Detected object range 01";
BA_ "GenSigVtName" SG_ 776 RL_CAN_DET_CONFID_AZIMUTH_060 "VtSig_CAN_SNR_LEVEL_01";
BA_ "GenSigVtEn" SG_ 776 RL_CAN_DET_CONFID_AZIMUTH_060 "TRUE";
BA_ "GenSigCmt" SG_ 776 RL_CAN_DET_CONFID_AZIMUTH_060 "Signal to noise level 01";
BA_ "GenSigCmt" SG_ 776 RL_CAN_DET_RANGE_RATE_060 "Detected object range rate 01";
BA_ "GenSigStartValue" SG_ 776 RL_CAN_DET_RANGE_RATE_060 8192;
BA_ "GenSigCmt" SG_ 776 RL_CAN_SCAN_INDEX_2LSB_060 "The two LSB of scan index 01";
BA_ "GenSigCmt" SG_ 776 RL_CAN_DET_AMPLITUDE_060 "Detected object amplitude 01";
BA_ "GenSigStartValue" SG_ 776 RL_CAN_DET_AMPLITUDE_060 64;
BA_ "GenSigCmt" SG_ 776 RL_CAN_DET_VALID_LEVEL_060 "Detected object valid level 01";
BA_ "GenSigCmt" SG_ 776 RL_CAN_DET_ELEVATION_059 "Detected object elevation position 01";
BA_ "GenSigStartValue" SG_ 776 RL_CAN_DET_ELEVATION_059 63.8646288209607;
BA_ "GenSigCmt" SG_ 776 RL_CAN_DET_SUPER_RES_TARGET_059 "Super resolution target 01";
BA_ "GenSigCmt" SG_ 776 RL_CAN_DET_AZIMUTH_059 "Detected object azimuth position 01";
BA_ "GenSigStartValue" SG_ 776 RL_CAN_DET_AZIMUTH_059 8194.10934583694;
BA_ "GenSigCmt" SG_ 776 RL_CAN_DET_CONFID_ELEVATION_059 "Near discrimination target 01";
BA_ "GenSigCmt" SG_ 776 RL_CAN_DET_HOST_VEH_CLUTTER_059 "Host vehicle clutter 01";
BA_ "GenSigCmt" SG_ 776 RL_CAN_DET_RANGE_059 "Detected object range 01";
BA_ "GenSigVtName" SG_ 776 RL_CAN_DET_CONFID_AZIMUTH_059 "VtSig_CAN_SNR_LEVEL_01";
BA_ "GenSigVtEn" SG_ 776 RL_CAN_DET_CONFID_AZIMUTH_059 "TRUE";
BA_ "GenSigCmt" SG_ 776 RL_CAN_DET_CONFID_AZIMUTH_059 "Signal to noise level 01";
BA_ "GenSigCmt" SG_ 776 RL_CAN_DET_RANGE_RATE_059 "Detected object range rate 01";
BA_ "GenSigStartValue" SG_ 776 RL_CAN_DET_RANGE_RATE_059 8192;
BA_ "GenSigCmt" SG_ 776 RL_CAN_SCAN_INDEX_2LSB_059 "The two LSB of scan index 01";
BA_ "GenSigCmt" SG_ 776 RL_CAN_DET_AMPLITUDE_059 "Detected object amplitude 01";
BA_ "GenSigStartValue" SG_ 776 RL_CAN_DET_AMPLITUDE_059 64;
BA_ "GenSigCmt" SG_ 776 RL_CAN_DET_VALID_LEVEL_059 "Detected object valid level 01";
BA_ "GenSigCmt" SG_ 776 RL_CAN_DET_ELEVATION_058 "Detected object elevation position 01";
BA_ "GenSigStartValue" SG_ 776 RL_CAN_DET_ELEVATION_058 63.8646288209607;
BA_ "GenSigCmt" SG_ 776 RL_CAN_DET_SUPER_RES_TARGET_058 "Super resolution target 01";
BA_ "GenSigCmt" SG_ 776 RL_CAN_DET_AZIMUTH_058 "Detected object azimuth position 01";
BA_ "GenSigStartValue" SG_ 776 RL_CAN_DET_AZIMUTH_058 8194.10934583694;
BA_ "GenSigCmt" SG_ 776 RL_CAN_DET_CONFID_ELEVATION_058 "Near discrimination target 01";
BA_ "GenSigCmt" SG_ 776 RL_CAN_DET_HOST_VEH_CLUTTER_058 "Host vehicle clutter 01";
BA_ "GenSigCmt" SG_ 776 RL_CAN_DET_RANGE_058 "Detected object range 01";
BA_ "GenSigVtName" SG_ 776 RL_CAN_DET_CONFID_AZIMUTH_058 "VtSig_CAN_SNR_LEVEL_01";
BA_ "GenSigVtEn" SG_ 776 RL_CAN_DET_CONFID_AZIMUTH_058 "TRUE";
BA_ "GenSigCmt" SG_ 776 RL_CAN_DET_CONFID_AZIMUTH_058 "Signal to noise level 01";
BA_ "GenSigCmt" SG_ 776 RL_CAN_DET_RANGE_RATE_058 "Detected object range rate 01";
BA_ "GenSigStartValue" SG_ 776 RL_CAN_DET_RANGE_RATE_058 8192;
BA_ "GenSigCmt" SG_ 776 RL_CAN_SCAN_INDEX_2LSB_058 "The two LSB of scan index 01";
BA_ "GenSigCmt" SG_ 776 RL_CAN_DET_AMPLITUDE_058 "Detected object amplitude 01";
BA_ "GenSigStartValue" SG_ 776 RL_CAN_DET_AMPLITUDE_058 64;
BA_ "GenSigCmt" SG_ 776 RL_CAN_DET_VALID_LEVEL_058 "Detected object valid level 01";
BA_ "GenSigCmt" SG_ 777 RL_CAN_DET_ELEVATION_064 "Detected object elevation position 01";
BA_ "GenSigStartValue" SG_ 777 RL_CAN_DET_ELEVATION_064 63.8646288209607;
BA_ "GenSigCmt" SG_ 777 RL_CAN_DET_CONFID_AZIMUTH_064 "Signal to noise level 01";
BA_ "GenSigVtName" SG_ 777 RL_CAN_DET_CONFID_AZIMUTH_064 "VtSig_CAN_SNR_LEVEL_01";
BA_ "GenSigVtEn" SG_ 777 RL_CAN_DET_CONFID_AZIMUTH_064 "TRUE";
BA_ "GenSigCmt" SG_ 777 RL_CAN_DET_SUPER_RES_TARGET_064 "Super resolution target 01";
BA_ "GenSigCmt" SG_ 777 RL_CAN_DET_CONFID_ELEVATION_064 "Near discrimination target 01";
BA_ "GenSigCmt" SG_ 777 RL_CAN_DET_HOST_VEH_CLUTTER_064 "Host vehicle clutter 01";
BA_ "GenSigCmt" SG_ 777 RL_CAN_DET_VALID_LEVEL_064 "Detected object valid level 01";
BA_ "GenSigCmt" SG_ 777 RL_CAN_DET_AZIMUTH_064 "Detected object azimuth position 01";
BA_ "GenSigStartValue" SG_ 777 RL_CAN_DET_AZIMUTH_064 8194.10934583694;
BA_ "GenSigCmt" SG_ 777 RL_CAN_DET_RANGE_064 "Detected object range 01";
BA_ "GenSigCmt" SG_ 777 RL_CAN_DET_RANGE_RATE_064 "Detected object range rate 01";
BA_ "GenSigStartValue" SG_ 777 RL_CAN_DET_RANGE_RATE_064 8192;
BA_ "GenSigCmt" SG_ 777 RL_CAN_DET_AMPLITUDE_064 "Detected object amplitude 01";
BA_ "GenSigStartValue" SG_ 777 RL_CAN_DET_AMPLITUDE_064 64;
BA_ "GenSigCmt" SG_ 777 RL_CAN_SCAN_INDEX_2LSB_064 "The two LSB of scan index 01";
BA_ "GenSigCycleTime" SG_ 832 RL_CAN_TX_LOOK_INDEX_8 50;
BA_ "GenSigCycleTime" SG_ 832 RL_CAN_TX_SCAN_INDEX_TRACKER_OWN 50;
BA_ "GenSigCycleTime" SG_ 832 RL_CAN_TX_SCN_INDEX_TRKER_FUSED 50;
BA_ "GenSigCycleTime" SG_ 832 RL_CAN_TX_LOOK_TYPE 50;
BA_ "GenSigCycleTime" SG_ 832 RL_CAN_TX_LOOK_ID 50;
BA_ "GenSigCycleTime" SG_ 832 RL_CAN_TX_SYSTEM_TIME_STAMP 50;
BA_ "GenSigCmt" SG_ 1024 RR_CAN_DET_ELEVATION_007 "Detected object elevation position 01";
BA_ "GenSigStartValue" SG_ 1024 RR_CAN_DET_ELEVATION_007 63.8646288209607;
BA_ "GenSigCmt" SG_ 1024 RR_CAN_DET_SUPER_RES_TARGET_007 "Super resolution target 01";
BA_ "GenSigCmt" SG_ 1024 RR_CAN_DET_AZIMUTH_007 "Detected object azimuth position 01";
BA_ "GenSigStartValue" SG_ 1024 RR_CAN_DET_AZIMUTH_007 8194.10934583694;
BA_ "GenSigCmt" SG_ 1024 RR_CAN_DET_CONFID_ELEVATION_007 "Near discrimination target 01";
BA_ "GenSigCmt" SG_ 1024 RR_CAN_DET_HOST_VEH_CLUTTER_007 "Host vehicle clutter 01";
BA_ "GenSigCmt" SG_ 1024 RR_CAN_DET_RANGE_007 "Detected object range 01";
BA_ "GenSigCmt" SG_ 1024 RR_CAN_DET_CONFID_AZIMUTH_007 "Signal to noise level 01";
BA_ "GenSigVtName" SG_ 1024 RR_CAN_DET_CONFID_AZIMUTH_007 "VtSig_CAN_SNR_LEVEL_01";
BA_ "GenSigVtEn" SG_ 1024 RR_CAN_DET_CONFID_AZIMUTH_007 "TRUE";
BA_ "GenSigCmt" SG_ 1024 RR_CAN_DET_RANGE_RATE_007 "Detected object range rate 01";
BA_ "GenSigStartValue" SG_ 1024 RR_CAN_DET_RANGE_RATE_007 8192;
BA_ "GenSigCmt" SG_ 1024 RR_CAN_SCAN_INDEX_2LSB_007 "The two LSB of scan index 01";
BA_ "GenSigCmt" SG_ 1024 RR_CAN_DET_AMPLITUDE_007 "Detected object amplitude 01";
BA_ "GenSigStartValue" SG_ 1024 RR_CAN_DET_AMPLITUDE_007 64;
BA_ "GenSigCmt" SG_ 1024 RR_CAN_DET_VALID_LEVEL_007 "Detected object valid level 01";
BA_ "GenSigCmt" SG_ 1024 RR_CAN_DET_ELEVATION_006 "Detected object elevation position 01";
BA_ "GenSigStartValue" SG_ 1024 RR_CAN_DET_ELEVATION_006 63.8646288209607;
BA_ "GenSigCmt" SG_ 1024 RR_CAN_DET_SUPER_RES_TARGET_006 "Super resolution target 01";
BA_ "GenSigCmt" SG_ 1024 RR_CAN_DET_AZIMUTH_006 "Detected object azimuth position 01";
BA_ "GenSigStartValue" SG_ 1024 RR_CAN_DET_AZIMUTH_006 8194.10934583694;
BA_ "GenSigCmt" SG_ 1024 RR_CAN_DET_CONFID_ELEVATION_006 "Near discrimination target 01";
BA_ "GenSigCmt" SG_ 1024 RR_CAN_DET_HOST_VEH_CLUTTER_006 "Host vehicle clutter 01";
BA_ "GenSigCmt" SG_ 1024 RR_CAN_DET_RANGE_006 "Detected object range rate 01";
BA_ "GenSigCmt" SG_ 1024 RR_CAN_DET_CONFID_AZIMUTH_006 "Signal to noise level 01";
BA_ "GenSigVtName" SG_ 1024 RR_CAN_DET_CONFID_AZIMUTH_006 "VtSig_CAN_SNR_LEVEL_01";
BA_ "GenSigVtEn" SG_ 1024 RR_CAN_DET_CONFID_AZIMUTH_006 "TRUE";
BA_ "GenSigStartValue" SG_ 1024 RR_CAN_DET_RANGE_RATE_006 8192;
BA_ "GenSigCmt" SG_ 1024 RR_CAN_SCAN_INDEX_2LSB_006 "The two LSB of scan index 01";
BA_ "GenSigCmt" SG_ 1024 RR_CAN_DET_AMPLITUDE_006 "Detected object amplitude 01";
BA_ "GenSigStartValue" SG_ 1024 RR_CAN_DET_AMPLITUDE_006 64;
BA_ "GenSigCmt" SG_ 1024 RR_CAN_DET_VALID_LEVEL_006 "Detected object valid level 01";
BA_ "GenSigCmt" SG_ 1024 RR_CAN_DET_ELEVATION_005 "Detected object elevation position 01";
BA_ "GenSigStartValue" SG_ 1024 RR_CAN_DET_ELEVATION_005 63.8646288209607;
BA_ "GenSigCmt" SG_ 1024 RR_CAN_DET_SUPER_RES_TARGET_005 "Super resolution target 01";
BA_ "GenSigCmt" SG_ 1024 RR_CAN_DET_AZIMUTH_005 "Detected object azimuth position 01";
BA_ "GenSigStartValue" SG_ 1024 RR_CAN_DET_AZIMUTH_005 8194.10934583694;
BA_ "GenSigCmt" SG_ 1024 RR_CAN_DET_CONFID_ELEVATION_005 "Near discrimination target 01";
BA_ "GenSigCmt" SG_ 1024 RR_CAN_DET_HOST_VEH_CLUTTER_005 "Host vehicle clutter 01";
BA_ "GenSigCmt" SG_ 1024 RR_CAN_DET_RANGE_005 "Detected object range rate 01";
BA_ "GenSigCmt" SG_ 1024 RR_CAN_DET_CONFID_AZIMUTH_005 "Signal to noise level 01";
BA_ "GenSigVtName" SG_ 1024 RR_CAN_DET_CONFID_AZIMUTH_005 "VtSig_CAN_SNR_LEVEL_01";
BA_ "GenSigVtEn" SG_ 1024 RR_CAN_DET_CONFID_AZIMUTH_005 "TRUE";
BA_ "GenSigStartValue" SG_ 1024 RR_CAN_DET_RANGE_RATE_005 8192;
BA_ "GenSigCmt" SG_ 1024 RR_CAN_SCAN_INDEX_2LSB_005 "The two LSB of scan index 01";
BA_ "GenSigCmt" SG_ 1024 RR_CAN_DET_AMPLITUDE_005 "Detected object amplitude 01";
BA_ "GenSigStartValue" SG_ 1024 RR_CAN_DET_AMPLITUDE_005 64;
BA_ "GenSigCmt" SG_ 1024 RR_CAN_DET_VALID_LEVEL_005 "Detected object valid level 01";
BA_ "GenSigCmt" SG_ 1024 RR_CAN_DET_ELEVATION_004 "Detected object elevation position 01";
BA_ "GenSigStartValue" SG_ 1024 RR_CAN_DET_ELEVATION_004 63.8646288209607;
BA_ "GenSigCmt" SG_ 1024 RR_CAN_DET_SUPER_RES_TARGET_004 "Super resolution target 01";
BA_ "GenSigCmt" SG_ 1024 RR_CAN_DET_AZIMUTH_004 "Detected object azimuth position 01";
BA_ "GenSigStartValue" SG_ 1024 RR_CAN_DET_AZIMUTH_004 8194.10934583694;
BA_ "GenSigCmt" SG_ 1024 RR_CAN_DET_CONFID_ELEVATION_004 "Near discrimination target 01";
BA_ "GenSigCmt" SG_ 1024 RR_CAN_DET_HOST_VEH_CLUTTER_004 "Host vehicle clutter 01";
BA_ "GenSigCmt" SG_ 1024 RR_CAN_DET_RANGE_004 "Detected object range rate 01";
BA_ "GenSigCmt" SG_ 1024 RR_CAN_DET_CONFID_AZIMUTH_004 "Signal to noise level 01";
BA_ "GenSigVtName" SG_ 1024 RR_CAN_DET_CONFID_AZIMUTH_004 "VtSig_CAN_SNR_LEVEL_01";
BA_ "GenSigVtEn" SG_ 1024 RR_CAN_DET_CONFID_AZIMUTH_004 "TRUE";
BA_ "GenSigStartValue" SG_ 1024 RR_CAN_DET_RANGE_RATE_004 8192;
BA_ "GenSigCmt" SG_ 1024 RR_CAN_SCAN_INDEX_2LSB_004 "The two LSB of scan index 01";
BA_ "GenSigCmt" SG_ 1024 RR_CAN_DET_AMPLITUDE_004 "Detected object amplitude 01";
BA_ "GenSigStartValue" SG_ 1024 RR_CAN_DET_AMPLITUDE_004 64;
BA_ "GenSigCmt" SG_ 1024 RR_CAN_DET_VALID_LEVEL_004 "Detected object valid level 01";
BA_ "GenSigCmt" SG_ 1024 RR_CAN_DET_ELEVATION_003 "Detected object elevation position 01";
BA_ "GenSigStartValue" SG_ 1024 RR_CAN_DET_ELEVATION_003 63.8646288209607;
BA_ "GenSigCmt" SG_ 1024 RR_CAN_DET_SUPER_RES_TARGET_003 "Super resolution target 01";
BA_ "GenSigCmt" SG_ 1024 RR_CAN_DET_AZIMUTH_003 "Detected object azimuth position 01";
BA_ "GenSigStartValue" SG_ 1024 RR_CAN_DET_AZIMUTH_003 8194.10934583694;
BA_ "GenSigCmt" SG_ 1024 RR_CAN_DET_CONFID_ELEVATION_003 "Near discrimination target 01";
BA_ "GenSigCmt" SG_ 1024 RR_CAN_DET_HOST_VEH_CLUTTER_003 "Host vehicle clutter 01";
BA_ "GenSigCmt" SG_ 1024 RR_CAN_DET_RANGE_003 "Detected object range 01";
BA_ "GenSigCmt" SG_ 1024 RR_CAN_DET_CONFID_AZIMUTH_003 "Signal to noise level 01";
BA_ "GenSigVtName" SG_ 1024 RR_CAN_DET_CONFID_AZIMUTH_003 "VtSig_CAN_SNR_LEVEL_01";
BA_ "GenSigVtEn" SG_ 1024 RR_CAN_DET_CONFID_AZIMUTH_003 "TRUE";
BA_ "GenSigCmt" SG_ 1024 RR_CAN_DET_RANGE_RATE_003 "Detected object range rate 01";
BA_ "GenSigStartValue" SG_ 1024 RR_CAN_DET_RANGE_RATE_003 8192;
BA_ "GenSigCmt" SG_ 1024 RR_CAN_SCAN_INDEX_2LSB_003 "The two LSB of scan index 01";
BA_ "GenSigCmt" SG_ 1024 RR_CAN_DET_AMPLITUDE_003 "Detected object amplitude 01";
BA_ "GenSigStartValue" SG_ 1024 RR_CAN_DET_AMPLITUDE_003 64;
BA_ "GenSigCmt" SG_ 1024 RR_CAN_DET_VALID_LEVEL_003 "Detected object valid level 01";
BA_ "GenSigCmt" SG_ 1024 RR_CAN_DET_ELEVATION_002 "Detected object elevation position 01";
BA_ "GenSigStartValue" SG_ 1024 RR_CAN_DET_ELEVATION_002 63.8646288209607;
BA_ "GenSigCmt" SG_ 1024 RR_CAN_DET_SUPER_RES_TARGET_002 "Super resolution target 01";
BA_ "GenSigCmt" SG_ 1024 RR_CAN_DET_AZIMUTH_002 "Detected object azimuth position 01";
BA_ "GenSigStartValue" SG_ 1024 RR_CAN_DET_AZIMUTH_002 8194.10934583694;
BA_ "GenSigCmt" SG_ 1024 RR_CAN_DET_CONFID_ELEVATION_002 "Near discrimination target 01";
BA_ "GenSigCmt" SG_ 1024 RR_CAN_DET_HOST_VEH_CLUTTER_002 "Host vehicle clutter 01";
BA_ "GenSigCmt" SG_ 1024 RR_CAN_DET_RANGE_002 "Detected object range 01";
BA_ "GenSigCmt" SG_ 1024 RR_CAN_DET_CONFID_AZIMUTH_002 "Signal to noise level 01";
BA_ "GenSigVtName" SG_ 1024 RR_CAN_DET_CONFID_AZIMUTH_002 "VtSig_CAN_SNR_LEVEL_01";
BA_ "GenSigVtEn" SG_ 1024 RR_CAN_DET_CONFID_AZIMUTH_002 "TRUE";
BA_ "GenSigCmt" SG_ 1024 RR_CAN_DET_RANGE_RATE_002 "Detected object range rate 01";
BA_ "GenSigStartValue" SG_ 1024 RR_CAN_DET_RANGE_RATE_002 8192;
BA_ "GenSigCmt" SG_ 1024 RR_CAN_SCAN_INDEX_2LSB_002 "The two LSB of scan index 01";
BA_ "GenSigCmt" SG_ 1024 RR_CAN_DET_AMPLITUDE_002 "Detected object amplitude 01";
BA_ "GenSigStartValue" SG_ 1024 RR_CAN_DET_AMPLITUDE_002 64;
BA_ "GenSigCmt" SG_ 1024 RR_CAN_DET_VALID_LEVEL_002 "Detected object valid level 01";
BA_ "GenSigCmt" SG_ 1024 RR_CAN_DET_ELEVATION_001 "Detected object elevation position 01";
BA_ "GenSigStartValue" SG_ 1024 RR_CAN_DET_ELEVATION_001 63.8646288209607;
BA_ "GenSigCmt" SG_ 1024 RR_CAN_DET_CONFID_AZIMUTH_001 "Signal to noise level 01";
BA_ "GenSigVtName" SG_ 1024 RR_CAN_DET_CONFID_AZIMUTH_001 "VtSig_CAN_SNR_LEVEL_01";
BA_ "GenSigVtEn" SG_ 1024 RR_CAN_DET_CONFID_AZIMUTH_001 "TRUE";
BA_ "GenSigCmt" SG_ 1024 RR_CAN_DET_SUPER_RES_TARGET_001 "Super resolution target 01";
BA_ "GenSigCmt" SG_ 1024 RR_CAN_DET_CONFID_ELEVATION_001 "Near discrimination target 01";
BA_ "GenSigCmt" SG_ 1024 RR_CAN_DET_HOST_VEH_CLUTTER_001 "Host vehicle clutter 01";
BA_ "GenSigCmt" SG_ 1024 RR_CAN_DET_VALID_LEVEL_001 "Detected object valid level 01";
BA_ "GenSigCmt" SG_ 1024 RR_CAN_DET_AZIMUTH_001 "Detected object azimuth position 01";
BA_ "GenSigStartValue" SG_ 1024 RR_CAN_DET_AZIMUTH_001 8194.10934583694;
BA_ "GenSigCmt" SG_ 1024 RR_CAN_DET_RANGE_001 "Detected object range 01";
BA_ "GenSigCmt" SG_ 1024 RR_CAN_DET_RANGE_RATE_001 "Detected object range rate 01";
BA_ "GenSigStartValue" SG_ 1024 RR_CAN_DET_RANGE_RATE_001 8192;
BA_ "GenSigCmt" SG_ 1024 RR_CAN_DET_AMPLITUDE_001 "Detected object amplitude 01";
BA_ "GenSigStartValue" SG_ 1024 RR_CAN_DET_AMPLITUDE_001 64;
BA_ "GenSigCmt" SG_ 1024 RR_CAN_SCAN_INDEX_2LSB_001 "The two LSB of scan index 01";
BA_ "GenSigCmt" SG_ 1025 RR_CAN_DET_ELEVATION_008 "Detected object elevation position 01";
BA_ "GenSigStartValue" SG_ 1025 RR_CAN_DET_ELEVATION_008 63.8646288209607;
BA_ "GenSigCmt" SG_ 1025 RR_CAN_DET_CONFID_AZIMUTH_008 "Signal to noise level 01";
BA_ "GenSigVtName" SG_ 1025 RR_CAN_DET_CONFID_AZIMUTH_008 "VtSig_CAN_SNR_LEVEL_01";
BA_ "GenSigVtEn" SG_ 1025 RR_CAN_DET_CONFID_AZIMUTH_008 "TRUE";
BA_ "GenSigCmt" SG_ 1025 RR_CAN_DET_SUPER_RES_TARGET_008 "Super resolution target 01";
BA_ "GenSigCmt" SG_ 1025 RR_CAN_DET_CONFID_ELEVATION_008 "Near discrimination target 01";
BA_ "GenSigCmt" SG_ 1025 RR_CAN_DET_HOST_VEH_CLUTTER_008 "Host vehicle clutter 01";
BA_ "GenSigCmt" SG_ 1025 RR_CAN_DET_VALID_LEVEL_008 "Detected object valid level 01";
BA_ "GenSigCmt" SG_ 1025 RR_CAN_DET_AZIMUTH_008 "Detected object azimuth position 01";
BA_ "GenSigStartValue" SG_ 1025 RR_CAN_DET_AZIMUTH_008 8194.10934583694;
BA_ "GenSigCmt" SG_ 1025 RR_CAN_DET_RANGE_008 "Detected object range 01";
BA_ "GenSigCmt" SG_ 1025 RR_CAN_DET_RANGE_RATE_008 "Detected object range rate 01";
BA_ "GenSigStartValue" SG_ 1025 RR_CAN_DET_RANGE_RATE_008 8192;
BA_ "GenSigCmt" SG_ 1025 RR_CAN_DET_AMPLITUDE_008 "Detected object amplitude 01";
BA_ "GenSigStartValue" SG_ 1025 RR_CAN_DET_AMPLITUDE_008 64;
BA_ "GenSigCmt" SG_ 1025 RR_CAN_SCAN_INDEX_2LSB_008 "The two LSB of scan index 01";
BA_ "GenSigStartValue" SG_ 1025 RR_CAN_DET_ELEVATION_014 63.8646288209607;
BA_ "GenSigCmt" SG_ 1025 RR_CAN_DET_AZIMUTH_014 "Detected object azimuth position 01";
BA_ "GenSigStartValue" SG_ 1025 RR_CAN_DET_AZIMUTH_014 8194.10934583694;
BA_ "GenSigStartValue" SG_ 1025 RR_CAN_DET_RANGE_RATE_014 8192;
BA_ "GenSigCmt" SG_ 1025 RR_CAN_DET_AMPLITUDE_014 "Detected object amplitude 01";
BA_ "GenSigStartValue" SG_ 1025 RR_CAN_DET_AMPLITUDE_014 64;
BA_ "GenSigStartValue" SG_ 1025 RR_CAN_DET_ELEVATION_013 63.8646288209607;
BA_ "GenSigCmt" SG_ 1025 RR_CAN_DET_AZIMUTH_013 "Detected object azimuth position 01";
BA_ "GenSigStartValue" SG_ 1025 RR_CAN_DET_AZIMUTH_013 8194.10934583694;
BA_ "GenSigStartValue" SG_ 1025 RR_CAN_DET_RANGE_RATE_013 8192;
BA_ "GenSigCmt" SG_ 1025 RR_CAN_DET_AMPLITUDE_013 "Detected object amplitude 01";
BA_ "GenSigStartValue" SG_ 1025 RR_CAN_DET_AMPLITUDE_013 64;
BA_ "GenSigStartValue" SG_ 1025 RR_CAN_DET_ELEVATION_012 63.8646288209607;
BA_ "GenSigCmt" SG_ 1025 RR_CAN_DET_AZIMUTH_012 "Detected object azimuth position 01";
BA_ "GenSigStartValue" SG_ 1025 RR_CAN_DET_AZIMUTH_012 8194.10934583694;
BA_ "GenSigStartValue" SG_ 1025 RR_CAN_DET_RANGE_RATE_012 8192;
BA_ "GenSigCmt" SG_ 1025 RR_CAN_DET_AMPLITUDE_012 "Detected object amplitude 01";
BA_ "GenSigStartValue" SG_ 1025 RR_CAN_DET_AMPLITUDE_012 64;
BA_ "GenSigStartValue" SG_ 1025 RR_CAN_DET_ELEVATION_011 63.8646288209607;
BA_ "GenSigCmt" SG_ 1025 RR_CAN_DET_AZIMUTH_011 "Detected object azimuth position 01";
BA_ "GenSigStartValue" SG_ 1025 RR_CAN_DET_AZIMUTH_011 8194.10934583694;
BA_ "GenSigStartValue" SG_ 1025 RR_CAN_DET_RANGE_RATE_011 8192;
BA_ "GenSigCmt" SG_ 1025 RR_CAN_DET_AMPLITUDE_011 "Detected object amplitude 01";
BA_ "GenSigStartValue" SG_ 1025 RR_CAN_DET_AMPLITUDE_011 64;
BA_ "GenSigStartValue" SG_ 1025 RR_CAN_DET_ELEVATION_010 63.8646288209607;
BA_ "GenSigCmt" SG_ 1025 RR_CAN_DET_AZIMUTH_010 "Detected object azimuth position 01";
BA_ "GenSigStartValue" SG_ 1025 RR_CAN_DET_AZIMUTH_010 8194.10934583694;
BA_ "GenSigStartValue" SG_ 1025 RR_CAN_DET_RANGE_RATE_010 8192;
BA_ "GenSigCmt" SG_ 1025 RR_CAN_DET_AMPLITUDE_010 "Detected object amplitude 01";
BA_ "GenSigStartValue" SG_ 1025 RR_CAN_DET_AMPLITUDE_010 64;
BA_ "GenSigStartValue" SG_ 1025 RR_CAN_DET_ELEVATION_009 63.8646288209607;
BA_ "GenSigCmt" SG_ 1025 RR_CAN_DET_AZIMUTH_009 "Detected object azimuth position 01";
BA_ "GenSigStartValue" SG_ 1025 RR_CAN_DET_AZIMUTH_009 8194.10934583694;
BA_ "GenSigCmt" SG_ 1025 RR_CAN_DET_HOST_VEH_CLUTTER_009 "Host vehicle clutter 01";
BA_ "GenSigStartValue" SG_ 1025 RR_CAN_DET_RANGE_RATE_009 8192;
BA_ "GenSigCmt" SG_ 1025 RR_CAN_DET_AMPLITUDE_009 "Detected object amplitude 01";
BA_ "GenSigStartValue" SG_ 1025 RR_CAN_DET_AMPLITUDE_009 64;
BA_ "GenSigCmt" SG_ 1026 RR_CAN_DET_ELEVATION_015 "Detected object elevation position 01";
BA_ "GenSigStartValue" SG_ 1026 RR_CAN_DET_ELEVATION_015 63.8646288209607;
BA_ "GenSigCmt" SG_ 1026 RR_CAN_DET_CONFID_AZIMUTH_015 "Signal to noise level 01";
BA_ "GenSigVtName" SG_ 1026 RR_CAN_DET_CONFID_AZIMUTH_015 "VtSig_CAN_SNR_LEVEL_01";
BA_ "GenSigVtEn" SG_ 1026 RR_CAN_DET_CONFID_AZIMUTH_015 "TRUE";
BA_ "GenSigCmt" SG_ 1026 RR_CAN_DET_SUPER_RES_TARGET_015 "Super resolution target 01";
BA_ "GenSigCmt" SG_ 1026 RR_CAN_DET_CONFID_ELEVATION_015 "Near discrimination target 01";
BA_ "GenSigCmt" SG_ 1026 RR_CAN_DET_HOST_VEH_CLUTTER_015 "Host vehicle clutter 01";
BA_ "GenSigCmt" SG_ 1026 RR_CAN_DET_VALID_LEVEL_015 "Detected object valid level 01";
BA_ "GenSigCmt" SG_ 1026 RR_CAN_DET_AZIMUTH_015 "Detected object azimuth position 01";
BA_ "GenSigStartValue" SG_ 1026 RR_CAN_DET_AZIMUTH_015 8194.10934583694;
BA_ "GenSigCmt" SG_ 1026 RR_CAN_DET_RANGE_015 "Detected object range 01";
BA_ "GenSigCmt" SG_ 1026 RR_CAN_DET_RANGE_RATE_015 "Detected object range rate 01";
BA_ "GenSigStartValue" SG_ 1026 RR_CAN_DET_RANGE_RATE_015 8192;
BA_ "GenSigCmt" SG_ 1026 RR_CAN_DET_AMPLITUDE_015 "Detected object amplitude 01";
BA_ "GenSigStartValue" SG_ 1026 RR_CAN_DET_AMPLITUDE_015 64;
BA_ "GenSigCmt" SG_ 1026 RR_CAN_SCAN_INDEX_2LSB_015 "The two LSB of scan index 01";
BA_ "GenSigStartValue" SG_ 1026 RR_CAN_DET_ELEVATION_021 63.8646288209607;
BA_ "GenSigCmt" SG_ 1026 RR_CAN_DET_AZIMUTH_021 "Detected object azimuth position 01";
BA_ "GenSigStartValue" SG_ 1026 RR_CAN_DET_AZIMUTH_021 8194.10934583694;
BA_ "GenSigStartValue" SG_ 1026 RR_CAN_DET_RANGE_RATE_021 8192;
BA_ "GenSigCmt" SG_ 1026 RR_CAN_DET_AMPLITUDE_021 "Detected object amplitude 01";
BA_ "GenSigStartValue" SG_ 1026 RR_CAN_DET_AMPLITUDE_021 64;
BA_ "GenSigStartValue" SG_ 1026 RR_CAN_DET_ELEVATION_020 63.8646288209607;
BA_ "GenSigCmt" SG_ 1026 RR_CAN_DET_AZIMUTH_020 "Detected object azimuth position 01";
BA_ "GenSigStartValue" SG_ 1026 RR_CAN_DET_AZIMUTH_020 8194.10934583694;
BA_ "GenSigStartValue" SG_ 1026 RR_CAN_DET_RANGE_RATE_020 8192;
BA_ "GenSigCmt" SG_ 1026 RR_CAN_DET_AMPLITUDE_020 "Detected object amplitude 01";
BA_ "GenSigStartValue" SG_ 1026 RR_CAN_DET_AMPLITUDE_020 64;
BA_ "GenSigStartValue" SG_ 1026 RR_CAN_DET_ELEVATION_019 63.8646288209607;
BA_ "GenSigCmt" SG_ 1026 RR_CAN_DET_AZIMUTH_019 "Detected object azimuth position 01";
BA_ "GenSigStartValue" SG_ 1026 RR_CAN_DET_AZIMUTH_019 8194.10934583694;
BA_ "GenSigStartValue" SG_ 1026 RR_CAN_DET_RANGE_RATE_019 8192;
BA_ "GenSigCmt" SG_ 1026 RR_CAN_DET_AMPLITUDE_019 "Detected object amplitude 01";
BA_ "GenSigStartValue" SG_ 1026 RR_CAN_DET_AMPLITUDE_019 64;
BA_ "GenSigStartValue" SG_ 1026 RR_CAN_DET_ELEVATION_018 63.8646288209607;
BA_ "GenSigCmt" SG_ 1026 RR_CAN_DET_AZIMUTH_018 "Detected object azimuth position 01";
BA_ "GenSigStartValue" SG_ 1026 RR_CAN_DET_AZIMUTH_018 8194.10934583694;
BA_ "GenSigStartValue" SG_ 1026 RR_CAN_DET_RANGE_RATE_018 8192;
BA_ "GenSigCmt" SG_ 1026 RR_CAN_DET_AMPLITUDE_018 "Detected object amplitude 01";
BA_ "GenSigStartValue" SG_ 1026 RR_CAN_DET_AMPLITUDE_018 64;
BA_ "GenSigStartValue" SG_ 1026 RR_CAN_DET_ELEVATION_017 63.8646288209607;
BA_ "GenSigCmt" SG_ 1026 RR_CAN_DET_AZIMUTH_017 "Detected object azimuth position 01";
BA_ "GenSigStartValue" SG_ 1026 RR_CAN_DET_AZIMUTH_017 8194.10934583694;
BA_ "GenSigStartValue" SG_ 1026 RR_CAN_DET_RANGE_RATE_017 8192;
BA_ "GenSigCmt" SG_ 1026 RR_CAN_DET_AMPLITUDE_017 "Detected object amplitude 01";
BA_ "GenSigStartValue" SG_ 1026 RR_CAN_DET_AMPLITUDE_017 64;
BA_ "GenSigStartValue" SG_ 1026 RR_CAN_DET_ELEVATION_016 63.8646288209607;
BA_ "GenSigCmt" SG_ 1026 RR_CAN_DET_AZIMUTH_016 "Detected object azimuth position 01";
BA_ "GenSigStartValue" SG_ 1026 RR_CAN_DET_AZIMUTH_016 8194.10934583694;
BA_ "GenSigStartValue" SG_ 1026 RR_CAN_DET_RANGE_RATE_016 8192;
BA_ "GenSigCmt" SG_ 1026 RR_CAN_DET_AMPLITUDE_016 "Detected object amplitude 01";
BA_ "GenSigStartValue" SG_ 1026 RR_CAN_DET_AMPLITUDE_016 64;
BA_ "GenSigCmt" SG_ 1027 RR_CAN_DET_ELEVATION_022 "Detected object elevation position 01";
BA_ "GenSigStartValue" SG_ 1027 RR_CAN_DET_ELEVATION_022 63.8646288209607;
BA_ "GenSigCmt" SG_ 1027 RR_CAN_DET_CONFID_AZIMUTH_022 "Signal to noise level 01";
BA_ "GenSigVtName" SG_ 1027 RR_CAN_DET_CONFID_AZIMUTH_022 "VtSig_CAN_SNR_LEVEL_01";
BA_ "GenSigVtEn" SG_ 1027 RR_CAN_DET_CONFID_AZIMUTH_022 "TRUE";
BA_ "GenSigCmt" SG_ 1027 RR_CAN_DET_SUPER_RES_TARGET_022 "Super resolution target 01";
BA_ "GenSigCmt" SG_ 1027 RR_CAN_DET_CONFID_ELEVATION_022 "Near discrimination target 01";
BA_ "GenSigCmt" SG_ 1027 RR_CAN_DET_HOST_VEH_CLUTTER_022 "Host vehicle clutter 01";
BA_ "GenSigCmt" SG_ 1027 RR_CAN_DET_VALID_LEVEL_022 "Detected object valid level 01";
BA_ "GenSigCmt" SG_ 1027 RR_CAN_DET_AZIMUTH_022 "Detected object azimuth position 01";
BA_ "GenSigStartValue" SG_ 1027 RR_CAN_DET_AZIMUTH_022 8194.10934583694;
BA_ "GenSigCmt" SG_ 1027 RR_CAN_DET_RANGE_022 "Detected object range 01";
BA_ "GenSigCmt" SG_ 1027 RR_CAN_DET_RANGE_RATE_022 "Detected object range rate 01";
BA_ "GenSigStartValue" SG_ 1027 RR_CAN_DET_RANGE_RATE_022 8192;
BA_ "GenSigCmt" SG_ 1027 RR_CAN_DET_AMPLITUDE_022 "Detected object amplitude 01";
BA_ "GenSigStartValue" SG_ 1027 RR_CAN_DET_AMPLITUDE_022 64;
BA_ "GenSigCmt" SG_ 1027 RR_CAN_SCAN_INDEX_2LSB_022 "The two LSB of scan index 01";
BA_ "GenSigStartValue" SG_ 1027 RR_CAN_DET_ELEVATION_028 63.8646288209607;
BA_ "GenSigCmt" SG_ 1027 RR_CAN_DET_AZIMUTH_028 "Detected object azimuth position 01";
BA_ "GenSigStartValue" SG_ 1027 RR_CAN_DET_AZIMUTH_028 8194.10934583694;
BA_ "GenSigStartValue" SG_ 1027 RR_CAN_DET_RANGE_RATE_028 8192;
BA_ "GenSigCmt" SG_ 1027 RR_CAN_DET_AMPLITUDE_028 "Detected object amplitude 01";
BA_ "GenSigStartValue" SG_ 1027 RR_CAN_DET_AMPLITUDE_028 64;
BA_ "GenSigStartValue" SG_ 1027 RR_CAN_DET_ELEVATION_027 63.8646288209607;
BA_ "GenSigCmt" SG_ 1027 RR_CAN_DET_AZIMUTH_027 "Detected object azimuth position 01";
BA_ "GenSigStartValue" SG_ 1027 RR_CAN_DET_AZIMUTH_027 8194.10934583694;
BA_ "GenSigStartValue" SG_ 1027 RR_CAN_DET_RANGE_RATE_027 8192;
BA_ "GenSigCmt" SG_ 1027 RR_CAN_DET_AMPLITUDE_027 "Detected object amplitude 01";
BA_ "GenSigStartValue" SG_ 1027 RR_CAN_DET_AMPLITUDE_027 64;
BA_ "GenSigStartValue" SG_ 1027 RR_CAN_DET_ELEVATION_026 63.8646288209607;
BA_ "GenSigCmt" SG_ 1027 RR_CAN_DET_AZIMUTH_026 "Detected object azimuth position 01";
BA_ "GenSigStartValue" SG_ 1027 RR_CAN_DET_AZIMUTH_026 8194.10934583694;
BA_ "GenSigStartValue" SG_ 1027 RR_CAN_DET_RANGE_RATE_026 8192;
BA_ "GenSigCmt" SG_ 1027 RR_CAN_DET_AMPLITUDE_026 "Detected object amplitude 01";
BA_ "GenSigStartValue" SG_ 1027 RR_CAN_DET_AMPLITUDE_026 64;
BA_ "GenSigStartValue" SG_ 1027 RR_CAN_DET_ELEVATION_025 63.8646288209607;
BA_ "GenSigCmt" SG_ 1027 RR_CAN_DET_AZIMUTH_025 "Detected object azimuth position 01";
BA_ "GenSigStartValue" SG_ 1027 RR_CAN_DET_AZIMUTH_025 8194.10934583694;
BA_ "GenSigStartValue" SG_ 1027 RR_CAN_DET_RANGE_RATE_025 8192;
BA_ "GenSigCmt" SG_ 1027 RR_CAN_DET_AMPLITUDE_025 "Detected object amplitude 01";
BA_ "GenSigStartValue" SG_ 1027 RR_CAN_DET_AMPLITUDE_025 64;
BA_ "GenSigStartValue" SG_ 1027 RR_CAN_DET_ELEVATION_024 63.8646288209607;
BA_ "GenSigCmt" SG_ 1027 RR_CAN_DET_AZIMUTH_024 "Detected object azimuth position 01";
BA_ "GenSigStartValue" SG_ 1027 RR_CAN_DET_AZIMUTH_024 8194.10934583694;
BA_ "GenSigStartValue" SG_ 1027 RR_CAN_DET_RANGE_RATE_024 8192;
BA_ "GenSigCmt" SG_ 1027 RR_CAN_DET_AMPLITUDE_024 "Detected object amplitude 01";
BA_ "GenSigStartValue" SG_ 1027 RR_CAN_DET_AMPLITUDE_024 64;
BA_ "GenSigStartValue" SG_ 1027 RR_CAN_DET_ELEVATION_023 63.8646288209607;
BA_ "GenSigCmt" SG_ 1027 RR_CAN_DET_AZIMUTH_023 "Detected object azimuth position 01";
BA_ "GenSigStartValue" SG_ 1027 RR_CAN_DET_AZIMUTH_023 8194.10934583694;
BA_ "GenSigStartValue" SG_ 1027 RR_CAN_DET_RANGE_RATE_023 8192;
BA_ "GenSigCmt" SG_ 1027 RR_CAN_DET_AMPLITUDE_023 "Detected object amplitude 01";
BA_ "GenSigStartValue" SG_ 1027 RR_CAN_DET_AMPLITUDE_023 64;
BA_ "GenSigCmt" SG_ 1028 RR_CAN_DET_ELEVATION_029 "Detected object elevation position 01";
BA_ "GenSigStartValue" SG_ 1028 RR_CAN_DET_ELEVATION_029 63.8646288209607;
BA_ "GenSigCmt" SG_ 1028 RR_CAN_DET_CONFID_AZIMUTH_029 "Signal to noise level 01";
BA_ "GenSigVtName" SG_ 1028 RR_CAN_DET_CONFID_AZIMUTH_029 "VtSig_CAN_SNR_LEVEL_01";
BA_ "GenSigVtEn" SG_ 1028 RR_CAN_DET_CONFID_AZIMUTH_029 "TRUE";
BA_ "GenSigCmt" SG_ 1028 RR_CAN_DET_SUPER_RES_TARGET_029 "Super resolution target 01";
BA_ "GenSigCmt" SG_ 1028 RR_CAN_DET_CONFID_ELEVATION_029 "Near discrimination target 01";
BA_ "GenSigCmt" SG_ 1028 RR_CAN_DET_HOST_VEH_CLUTTER_029 "Host vehicle clutter 01";
BA_ "GenSigCmt" SG_ 1028 RR_CAN_DET_VALID_LEVEL_029 "Detected object valid level 01";
BA_ "GenSigCmt" SG_ 1028 RR_CAN_DET_AZIMUTH_029 "Detected object azimuth position 01";
BA_ "GenSigStartValue" SG_ 1028 RR_CAN_DET_AZIMUTH_029 8194.10934583694;
BA_ "GenSigCmt" SG_ 1028 RR_CAN_DET_RANGE_029 "Detected object range 01";
BA_ "GenSigCmt" SG_ 1028 RR_CAN_DET_RANGE_RATE_029 "Detected object range rate 01";
BA_ "GenSigStartValue" SG_ 1028 RR_CAN_DET_RANGE_RATE_029 8192;
BA_ "GenSigCmt" SG_ 1028 RR_CAN_DET_AMPLITUDE_029 "Detected object amplitude 01";
BA_ "GenSigStartValue" SG_ 1028 RR_CAN_DET_AMPLITUDE_029 64;
BA_ "GenSigCmt" SG_ 1028 RR_CAN_SCAN_INDEX_2LSB_029 "The two LSB of scan index 01";
BA_ "GenSigStartValue" SG_ 1028 RR_CAN_DET_ELEVATION_035 63.8646288209607;
BA_ "GenSigCmt" SG_ 1028 RR_CAN_DET_AZIMUTH_035 "Detected object azimuth position 01";
BA_ "GenSigStartValue" SG_ 1028 RR_CAN_DET_AZIMUTH_035 8194.10934583694;
BA_ "GenSigStartValue" SG_ 1028 RR_CAN_DET_RANGE_RATE_035 8192;
BA_ "GenSigCmt" SG_ 1028 RR_CAN_DET_AMPLITUDE_035 "Detected object amplitude 01";
BA_ "GenSigStartValue" SG_ 1028 RR_CAN_DET_AMPLITUDE_035 64;
BA_ "GenSigStartValue" SG_ 1028 RR_CAN_DET_ELEVATION_034 63.8646288209607;
BA_ "GenSigCmt" SG_ 1028 RR_CAN_DET_AZIMUTH_034 "Detected object azimuth position 01";
BA_ "GenSigStartValue" SG_ 1028 RR_CAN_DET_AZIMUTH_034 8194.10934583694;
BA_ "GenSigStartValue" SG_ 1028 RR_CAN_DET_RANGE_RATE_034 8192;
BA_ "GenSigCmt" SG_ 1028 RR_CAN_DET_AMPLITUDE_034 "Detected object amplitude 01";
BA_ "GenSigStartValue" SG_ 1028 RR_CAN_DET_AMPLITUDE_034 64;
BA_ "GenSigStartValue" SG_ 1028 RR_CAN_DET_ELEVATION_033 63.8646288209607;
BA_ "GenSigCmt" SG_ 1028 RR_CAN_DET_AZIMUTH_033 "Detected object azimuth position 01";
BA_ "GenSigStartValue" SG_ 1028 RR_CAN_DET_AZIMUTH_033 8194.10934583694;
BA_ "GenSigStartValue" SG_ 1028 RR_CAN_DET_RANGE_RATE_033 8192;
BA_ "GenSigCmt" SG_ 1028 RR_CAN_DET_AMPLITUDE_033 "Detected object amplitude 01";
BA_ "GenSigStartValue" SG_ 1028 RR_CAN_DET_AMPLITUDE_033 64;
BA_ "GenSigStartValue" SG_ 1028 RR_CAN_DET_ELEVATION_032 63.8646288209607;
BA_ "GenSigCmt" SG_ 1028 RR_CAN_DET_AZIMUTH_032 "Detected object azimuth position 01";
BA_ "GenSigStartValue" SG_ 1028 RR_CAN_DET_AZIMUTH_032 8194.10934583694;
BA_ "GenSigStartValue" SG_ 1028 RR_CAN_DET_RANGE_RATE_032 8192;
BA_ "GenSigCmt" SG_ 1028 RR_CAN_DET_AMPLITUDE_032 "Detected object amplitude 01";
BA_ "GenSigStartValue" SG_ 1028 RR_CAN_DET_AMPLITUDE_032 64;
BA_ "GenSigStartValue" SG_ 1028 RR_CAN_DET_ELEVATION_031 63.8646288209607;
BA_ "GenSigCmt" SG_ 1028 RR_CAN_DET_AZIMUTH_031 "Detected object azimuth position 01";
BA_ "GenSigStartValue" SG_ 1028 RR_CAN_DET_AZIMUTH_031 8194.10934583694;
BA_ "GenSigStartValue" SG_ 1028 RR_CAN_DET_RANGE_RATE_031 8192;
BA_ "GenSigCmt" SG_ 1028 RR_CAN_DET_AMPLITUDE_031 "Detected object amplitude 01";
BA_ "GenSigStartValue" SG_ 1028 RR_CAN_DET_AMPLITUDE_031 64;
BA_ "GenSigStartValue" SG_ 1028 RR_CAN_DET_ELEVATION_030 63.8646288209607;
BA_ "GenSigCmt" SG_ 1028 RR_CAN_DET_AZIMUTH_030 "Detected object azimuth position 01";
BA_ "GenSigStartValue" SG_ 1028 RR_CAN_DET_AZIMUTH_030 8194.10934583694;
BA_ "GenSigStartValue" SG_ 1028 RR_CAN_DET_RANGE_RATE_030 8192;
BA_ "GenSigCmt" SG_ 1028 RR_CAN_DET_AMPLITUDE_030 "Detected object amplitude 01";
BA_ "GenSigStartValue" SG_ 1028 RR_CAN_DET_AMPLITUDE_030 64;
BA_ "GenSigCmt" SG_ 1029 RR_CAN_DET_ELEVATION_036 "Detected object elevation position 01";
BA_ "GenSigStartValue" SG_ 1029 RR_CAN_DET_ELEVATION_036 63.8646288209607;
BA_ "GenSigCmt" SG_ 1029 RR_CAN_DET_CONFID_AZIMUTH_036 "Signal to noise level 01";
BA_ "GenSigVtName" SG_ 1029 RR_CAN_DET_CONFID_AZIMUTH_036 "VtSig_CAN_SNR_LEVEL_01";
BA_ "GenSigVtEn" SG_ 1029 RR_CAN_DET_CONFID_AZIMUTH_036 "TRUE";
BA_ "GenSigCmt" SG_ 1029 RR_CAN_DET_SUPER_RES_TARGET_036 "Super resolution target 01";
BA_ "GenSigCmt" SG_ 1029 RR_CAN_DET_CONFID_ELEVATION_036 "Near discrimination target 01";
BA_ "GenSigCmt" SG_ 1029 RR_CAN_DET_HOST_VEH_CLUTTER_036 "Host vehicle clutter 01";
BA_ "GenSigCmt" SG_ 1029 RR_CAN_DET_VALID_LEVEL_036 "Detected object valid level 01";
BA_ "GenSigCmt" SG_ 1029 RR_CAN_DET_AZIMUTH_036 "Detected object azimuth position 01";
BA_ "GenSigStartValue" SG_ 1029 RR_CAN_DET_AZIMUTH_036 8194.10934583694;
BA_ "GenSigCmt" SG_ 1029 RR_CAN_DET_RANGE_036 "Detected object range 01";
BA_ "GenSigCmt" SG_ 1029 RR_CAN_DET_RANGE_RATE_036 "Detected object range rate 01";
BA_ "GenSigStartValue" SG_ 1029 RR_CAN_DET_RANGE_RATE_036 8192;
BA_ "GenSigCmt" SG_ 1029 RR_CAN_DET_AMPLITUDE_036 "Detected object amplitude 01";
BA_ "GenSigStartValue" SG_ 1029 RR_CAN_DET_AMPLITUDE_036 64;
BA_ "GenSigCmt" SG_ 1029 RR_CAN_SCAN_INDEX_2LSB_036 "The two LSB of scan index 01";
BA_ "GenSigStartValue" SG_ 1029 RR_CAN_DET_ELEVATION_042 63.8646288209607;
BA_ "GenSigCmt" SG_ 1029 RR_CAN_DET_AZIMUTH_042 "Detected object azimuth position 01";
BA_ "GenSigStartValue" SG_ 1029 RR_CAN_DET_AZIMUTH_042 8194.10934583694;
BA_ "GenSigStartValue" SG_ 1029 RR_CAN_DET_RANGE_RATE_042 8192;
BA_ "GenSigCmt" SG_ 1029 RR_CAN_DET_AMPLITUDE_042 "Detected object amplitude 01";
BA_ "GenSigStartValue" SG_ 1029 RR_CAN_DET_AMPLITUDE_042 64;
BA_ "GenSigStartValue" SG_ 1029 RR_CAN_DET_ELEVATION_041 63.8646288209607;
BA_ "GenSigCmt" SG_ 1029 RR_CAN_DET_AZIMUTH_041 "Detected object azimuth position 01";
BA_ "GenSigStartValue" SG_ 1029 RR_CAN_DET_AZIMUTH_041 8194.10934583694;
BA_ "GenSigStartValue" SG_ 1029 RR_CAN_DET_RANGE_RATE_041 8192;
BA_ "GenSigCmt" SG_ 1029 RR_CAN_DET_AMPLITUDE_041 "Detected object amplitude 01";
BA_ "GenSigStartValue" SG_ 1029 RR_CAN_DET_AMPLITUDE_041 64;
BA_ "GenSigStartValue" SG_ 1029 RR_CAN_DET_ELEVATION_040 63.8646288209607;
BA_ "GenSigCmt" SG_ 1029 RR_CAN_DET_AZIMUTH_040 "Detected object azimuth position 01";
BA_ "GenSigStartValue" SG_ 1029 RR_CAN_DET_AZIMUTH_040 8194.10934583694;
BA_ "GenSigStartValue" SG_ 1029 RR_CAN_DET_RANGE_RATE_040 8192;
BA_ "GenSigCmt" SG_ 1029 RR_CAN_DET_AMPLITUDE_040 "Detected object amplitude 01";
BA_ "GenSigStartValue" SG_ 1029 RR_CAN_DET_AMPLITUDE_040 64;
BA_ "GenSigStartValue" SG_ 1029 RR_CAN_DET_ELEVATION_039 63.8646288209607;
BA_ "GenSigCmt" SG_ 1029 RR_CAN_DET_AZIMUTH_039 "Detected object azimuth position 01";
BA_ "GenSigStartValue" SG_ 1029 RR_CAN_DET_AZIMUTH_039 8194.10934583694;
BA_ "GenSigStartValue" SG_ 1029 RR_CAN_DET_RANGE_RATE_039 8192;
BA_ "GenSigCmt" SG_ 1029 RR_CAN_DET_AMPLITUDE_039 "Detected object amplitude 01";
BA_ "GenSigStartValue" SG_ 1029 RR_CAN_DET_AMPLITUDE_039 64;
BA_ "GenSigStartValue" SG_ 1029 RR_CAN_DET_ELEVATION_038 63.8646288209607;
BA_ "GenSigCmt" SG_ 1029 RR_CAN_DET_AZIMUTH_038 "Detected object azimuth position 01";
BA_ "GenSigStartValue" SG_ 1029 RR_CAN_DET_AZIMUTH_038 8194.10934583694;
BA_ "GenSigStartValue" SG_ 1029 RR_CAN_DET_RANGE_RATE_038 8192;
BA_ "GenSigCmt" SG_ 1029 RR_CAN_DET_AMPLITUDE_038 "Detected object amplitude 01";
BA_ "GenSigStartValue" SG_ 1029 RR_CAN_DET_AMPLITUDE_038 64;
BA_ "GenSigStartValue" SG_ 1029 RR_CAN_DET_ELEVATION_037 63.8646288209607;
BA_ "GenSigCmt" SG_ 1029 RR_CAN_DET_AZIMUTH_037 "Detected object azimuth position 01";
BA_ "GenSigStartValue" SG_ 1029 RR_CAN_DET_AZIMUTH_037 8194.10934583694;
BA_ "GenSigStartValue" SG_ 1029 RR_CAN_DET_RANGE_RATE_037 8192;
BA_ "GenSigCmt" SG_ 1029 RR_CAN_DET_AMPLITUDE_037 "Detected object amplitude 01";
BA_ "GenSigStartValue" SG_ 1029 RR_CAN_DET_AMPLITUDE_037 64;
BA_ "GenSigCmt" SG_ 1030 RR_CAN_DET_ELEVATION_043 "Detected object elevation position 01";
BA_ "GenSigStartValue" SG_ 1030 RR_CAN_DET_ELEVATION_043 63.8646288209607;
BA_ "GenSigCmt" SG_ 1030 RR_CAN_DET_CONFID_AZIMUTH_043 "Signal to noise level 01";
BA_ "GenSigVtName" SG_ 1030 RR_CAN_DET_CONFID_AZIMUTH_043 "VtSig_CAN_SNR_LEVEL_01";
BA_ "GenSigVtEn" SG_ 1030 RR_CAN_DET_CONFID_AZIMUTH_043 "TRUE";
BA_ "GenSigCmt" SG_ 1030 RR_CAN_DET_SUPER_RES_TARGET_043 "Super resolution target 01";
BA_ "GenSigCmt" SG_ 1030 RR_CAN_DET_CONFID_ELEVATION_043 "Near discrimination target 01";
BA_ "GenSigCmt" SG_ 1030 RR_CAN_DET_HOST_VEH_CLUTTER_043 "Host vehicle clutter 01";
BA_ "GenSigCmt" SG_ 1030 RR_CAN_DET_VALID_LEVEL_043 "Detected object valid level 01";
BA_ "GenSigCmt" SG_ 1030 RR_CAN_DET_AZIMUTH_043 "Detected object azimuth position 01";
BA_ "GenSigStartValue" SG_ 1030 RR_CAN_DET_AZIMUTH_043 8194.10934583694;
BA_ "GenSigCmt" SG_ 1030 RR_CAN_DET_RANGE_043 "Detected object range 01";
BA_ "GenSigCmt" SG_ 1030 RR_CAN_DET_RANGE_RATE_043 "Detected object range rate 01";
BA_ "GenSigStartValue" SG_ 1030 RR_CAN_DET_RANGE_RATE_043 8192;
BA_ "GenSigCmt" SG_ 1030 RR_CAN_DET_AMPLITUDE_043 "Detected object amplitude 01";
BA_ "GenSigStartValue" SG_ 1030 RR_CAN_DET_AMPLITUDE_043 64;
BA_ "GenSigCmt" SG_ 1030 RR_CAN_SCAN_INDEX_2LSB_043 "The two LSB of scan index 01";
BA_ "GenSigStartValue" SG_ 1030 RR_CAN_DET_ELEVATION_049 63.8646288209607;
BA_ "GenSigCmt" SG_ 1030 RR_CAN_DET_AZIMUTH_049 "Detected object azimuth position 01";
BA_ "GenSigStartValue" SG_ 1030 RR_CAN_DET_AZIMUTH_049 8194.10934583694;
BA_ "GenSigStartValue" SG_ 1030 RR_CAN_DET_RANGE_RATE_049 8192;
BA_ "GenSigCmt" SG_ 1030 RR_CAN_DET_AMPLITUDE_049 "Detected object amplitude 01";
BA_ "GenSigStartValue" SG_ 1030 RR_CAN_DET_AMPLITUDE_049 64;
BA_ "GenSigStartValue" SG_ 1030 RR_CAN_DET_ELEVATION_048 63.8646288209607;
BA_ "GenSigCmt" SG_ 1030 RR_CAN_DET_AZIMUTH_048 "Detected object azimuth position 01";
BA_ "GenSigStartValue" SG_ 1030 RR_CAN_DET_AZIMUTH_048 8194.10934583694;
BA_ "GenSigStartValue" SG_ 1030 RR_CAN_DET_RANGE_RATE_048 8192;
BA_ "GenSigCmt" SG_ 1030 RR_CAN_DET_AMPLITUDE_048 "Detected object amplitude 01";
BA_ "GenSigStartValue" SG_ 1030 RR_CAN_DET_AMPLITUDE_048 64;
BA_ "GenSigStartValue" SG_ 1030 RR_CAN_DET_ELEVATION_047 63.8646288209607;
BA_ "GenSigCmt" SG_ 1030 RR_CAN_DET_AZIMUTH_047 "Detected object azimuth position 01";
BA_ "GenSigStartValue" SG_ 1030 RR_CAN_DET_AZIMUTH_047 8194.10934583694;
BA_ "GenSigStartValue" SG_ 1030 RR_CAN_DET_RANGE_RATE_047 8192;
BA_ "GenSigCmt" SG_ 1030 RR_CAN_DET_AMPLITUDE_047 "Detected object amplitude 01";
BA_ "GenSigStartValue" SG_ 1030 RR_CAN_DET_AMPLITUDE_047 64;
BA_ "GenSigStartValue" SG_ 1030 RR_CAN_DET_ELEVATION_046 63.8646288209607;
BA_ "GenSigCmt" SG_ 1030 RR_CAN_DET_AZIMUTH_046 "Detected object azimuth position 01";
BA_ "GenSigStartValue" SG_ 1030 RR_CAN_DET_AZIMUTH_046 8194.10934583694;
BA_ "GenSigStartValue" SG_ 1030 RR_CAN_DET_RANGE_RATE_046 8192;
BA_ "GenSigCmt" SG_ 1030 RR_CAN_DET_AMPLITUDE_046 "Detected object amplitude 01";
BA_ "GenSigStartValue" SG_ 1030 RR_CAN_DET_AMPLITUDE_046 64;
BA_ "GenSigStartValue" SG_ 1030 RR_CAN_DET_ELEVATION_045 63.8646288209607;
BA_ "GenSigCmt" SG_ 1030 RR_CAN_DET_AZIMUTH_045 "Detected object azimuth position 01";
BA_ "GenSigStartValue" SG_ 1030 RR_CAN_DET_AZIMUTH_045 8194.10934583694;
BA_ "GenSigStartValue" SG_ 1030 RR_CAN_DET_RANGE_RATE_045 8192;
BA_ "GenSigCmt" SG_ 1030 RR_CAN_DET_AMPLITUDE_045 "Detected object amplitude 01";
BA_ "GenSigStartValue" SG_ 1030 RR_CAN_DET_AMPLITUDE_045 64;
BA_ "GenSigStartValue" SG_ 1030 RR_CAN_DET_ELEVATION_044 63.8646288209607;
BA_ "GenSigCmt" SG_ 1030 RR_CAN_DET_AZIMUTH_044 "Detected object azimuth position 01";
BA_ "GenSigStartValue" SG_ 1030 RR_CAN_DET_AZIMUTH_044 8194.10934583694;
BA_ "GenSigStartValue" SG_ 1030 RR_CAN_DET_RANGE_RATE_044 8192;
BA_ "GenSigCmt" SG_ 1030 RR_CAN_DET_AMPLITUDE_044 "Detected object amplitude 01";
BA_ "GenSigStartValue" SG_ 1030 RR_CAN_DET_AMPLITUDE_044 64;
BA_ "GenSigCmt" SG_ 1031 RR_CAN_DET_ELEVATION_050 "Detected object elevation position 01";
BA_ "GenSigStartValue" SG_ 1031 RR_CAN_DET_ELEVATION_050 63.8646288209607;
BA_ "GenSigCmt" SG_ 1031 RR_CAN_DET_CONFID_AZIMUTH_050 "Signal to noise level 01";
BA_ "GenSigVtName" SG_ 1031 RR_CAN_DET_CONFID_AZIMUTH_050 "VtSig_CAN_SNR_LEVEL_01";
BA_ "GenSigVtEn" SG_ 1031 RR_CAN_DET_CONFID_AZIMUTH_050 "TRUE";
BA_ "GenSigCmt" SG_ 1031 RR_CAN_DET_SUPER_RES_TARGET_050 "Super resolution target 01";
BA_ "GenSigCmt" SG_ 1031 RR_CAN_DET_CONFID_ELEVATION_050 "Near discrimination target 01";
BA_ "GenSigCmt" SG_ 1031 RR_CAN_DET_HOST_VEH_CLUTTER_050 "Host vehicle clutter 01";
BA_ "GenSigCmt" SG_ 1031 RR_CAN_DET_VALID_LEVEL_050 "Detected object valid level 01";
BA_ "GenSigCmt" SG_ 1031 RR_CAN_DET_AZIMUTH_050 "Detected object azimuth position 01";
BA_ "GenSigStartValue" SG_ 1031 RR_CAN_DET_AZIMUTH_050 8194.10934583694;
BA_ "GenSigCmt" SG_ 1031 RR_CAN_DET_RANGE_050 "Detected object range 01";
BA_ "GenSigCmt" SG_ 1031 RR_CAN_DET_RANGE_RATE_050 "Detected object range rate 01";
BA_ "GenSigStartValue" SG_ 1031 RR_CAN_DET_RANGE_RATE_050 8192;
BA_ "GenSigCmt" SG_ 1031 RR_CAN_DET_AMPLITUDE_050 "Detected object amplitude 01";
BA_ "GenSigStartValue" SG_ 1031 RR_CAN_DET_AMPLITUDE_050 64;
BA_ "GenSigCmt" SG_ 1031 RR_CAN_SCAN_INDEX_2LSB_050 "The two LSB of scan index 01";
BA_ "GenSigStartValue" SG_ 1031 RR_CAN_DET_ELEVATION_056 63.8646288209607;
BA_ "GenSigCmt" SG_ 1031 RR_CAN_DET_AZIMUTH_056 "Detected object azimuth position 01";
BA_ "GenSigStartValue" SG_ 1031 RR_CAN_DET_AZIMUTH_056 8194.10934583694;
BA_ "GenSigStartValue" SG_ 1031 RR_CAN_DET_RANGE_RATE_056 8192;
BA_ "GenSigCmt" SG_ 1031 RR_CAN_DET_AMPLITUDE_056 "Detected object amplitude 01";
BA_ "GenSigStartValue" SG_ 1031 RR_CAN_DET_AMPLITUDE_056 64;
BA_ "GenSigStartValue" SG_ 1031 RR_CAN_DET_ELEVATION_055 63.8646288209607;
BA_ "GenSigCmt" SG_ 1031 RR_CAN_DET_AZIMUTH_055 "Detected object azimuth position 01";
BA_ "GenSigStartValue" SG_ 1031 RR_CAN_DET_AZIMUTH_055 8194.10934583694;
BA_ "GenSigStartValue" SG_ 1031 RR_CAN_DET_RANGE_RATE_055 8192;
BA_ "GenSigCmt" SG_ 1031 RR_CAN_DET_AMPLITUDE_055 "Detected object amplitude 01";
BA_ "GenSigStartValue" SG_ 1031 RR_CAN_DET_AMPLITUDE_055 64;
BA_ "GenSigStartValue" SG_ 1031 RR_CAN_DET_ELEVATION_054 63.8646288209607;
BA_ "GenSigCmt" SG_ 1031 RR_CAN_DET_AZIMUTH_054 "Detected object azimuth position 01";
BA_ "GenSigStartValue" SG_ 1031 RR_CAN_DET_AZIMUTH_054 8194.10934583694;
BA_ "GenSigStartValue" SG_ 1031 RR_CAN_DET_RANGE_RATE_054 8192;
BA_ "GenSigCmt" SG_ 1031 RR_CAN_DET_AMPLITUDE_054 "Detected object amplitude 01";
BA_ "GenSigStartValue" SG_ 1031 RR_CAN_DET_AMPLITUDE_054 64;
BA_ "GenSigStartValue" SG_ 1031 RR_CAN_DET_ELEVATION_053 63.8646288209607;
BA_ "GenSigCmt" SG_ 1031 RR_CAN_DET_AZIMUTH_053 "Detected object azimuth position 01";
BA_ "GenSigStartValue" SG_ 1031 RR_CAN_DET_AZIMUTH_053 8194.10934583694;
BA_ "GenSigStartValue" SG_ 1031 RR_CAN_DET_RANGE_RATE_053 8192;
BA_ "GenSigCmt" SG_ 1031 RR_CAN_DET_AMPLITUDE_053 "Detected object amplitude 01";
BA_ "GenSigStartValue" SG_ 1031 RR_CAN_DET_AMPLITUDE_053 64;
BA_ "GenSigStartValue" SG_ 1031 RR_CAN_DET_ELEVATION_052 63.8646288209607;
BA_ "GenSigCmt" SG_ 1031 RR_CAN_DET_AZIMUTH_052 "Detected object azimuth position 01";
BA_ "GenSigStartValue" SG_ 1031 RR_CAN_DET_AZIMUTH_052 8194.10934583694;
BA_ "GenSigStartValue" SG_ 1031 RR_CAN_DET_RANGE_RATE_052 8192;
BA_ "GenSigCmt" SG_ 1031 RR_CAN_DET_AMPLITUDE_052 "Detected object amplitude 01";
BA_ "GenSigStartValue" SG_ 1031 RR_CAN_DET_AMPLITUDE_052 64;
BA_ "GenSigStartValue" SG_ 1031 RR_CAN_DET_ELEVATION_051 63.8646288209607;
BA_ "GenSigCmt" SG_ 1031 RR_CAN_DET_AZIMUTH_051 "Detected object azimuth position 01";
BA_ "GenSigStartValue" SG_ 1031 RR_CAN_DET_AZIMUTH_051 8194.10934583694;
BA_ "GenSigStartValue" SG_ 1031 RR_CAN_DET_RANGE_RATE_051 8192;
BA_ "GenSigCmt" SG_ 1031 RR_CAN_DET_AMPLITUDE_051 "Detected object amplitude 01";
BA_ "GenSigStartValue" SG_ 1031 RR_CAN_DET_AMPLITUDE_051 64;
BA_ "GenSigCmt" SG_ 1032 RR_CAN_DET_ELEVATION_057 "Detected object elevation position 01";
BA_ "GenSigStartValue" SG_ 1032 RR_CAN_DET_ELEVATION_057 63.8646288209607;
BA_ "GenSigCmt" SG_ 1032 RR_CAN_DET_CONFID_AZIMUTH_057 "Signal to noise level 01";
BA_ "GenSigVtName" SG_ 1032 RR_CAN_DET_CONFID_AZIMUTH_057 "VtSig_CAN_SNR_LEVEL_01";
BA_ "GenSigVtEn" SG_ 1032 RR_CAN_DET_CONFID_AZIMUTH_057 "TRUE";
BA_ "GenSigCmt" SG_ 1032 RR_CAN_DET_SUPER_RES_TARGET_057 "Super resolution target 01";
BA_ "GenSigCmt" SG_ 1032 RR_CAN_DET_CONFID_ELEVATION_057 "Near discrimination target 01";
BA_ "GenSigCmt" SG_ 1032 RR_CAN_DET_HOST_VEH_CLUTTER_057 "Host vehicle clutter 01";
BA_ "GenSigCmt" SG_ 1032 RR_CAN_DET_VALID_LEVEL_057 "Detected object valid level 01";
BA_ "GenSigCmt" SG_ 1032 RR_CAN_DET_AZIMUTH_057 "Detected object azimuth position 01";
BA_ "GenSigStartValue" SG_ 1032 RR_CAN_DET_AZIMUTH_057 8194.10934583694;
BA_ "GenSigCmt" SG_ 1032 RR_CAN_DET_RANGE_057 "Detected object range 01";
BA_ "GenSigCmt" SG_ 1032 RR_CAN_DET_RANGE_RATE_057 "Detected object range rate 01";
BA_ "GenSigStartValue" SG_ 1032 RR_CAN_DET_RANGE_RATE_057 8192;
BA_ "GenSigCmt" SG_ 1032 RR_CAN_DET_AMPLITUDE_057 "Detected object amplitude 01";
BA_ "GenSigStartValue" SG_ 1032 RR_CAN_DET_AMPLITUDE_057 64;
BA_ "GenSigCmt" SG_ 1032 RR_CAN_SCAN_INDEX_2LSB_057 "The two LSB of scan index 01";
BA_ "GenSigStartValue" SG_ 1032 RR_CAN_DET_ELEVATION_063 63.8646288209607;
BA_ "GenSigCmt" SG_ 1032 RR_CAN_DET_AZIMUTH_063 "Detected object azimuth position 01";
BA_ "GenSigStartValue" SG_ 1032 RR_CAN_DET_AZIMUTH_063 8194.10934583694;
BA_ "GenSigStartValue" SG_ 1032 RR_CAN_DET_RANGE_RATE_063 8192;
BA_ "GenSigCmt" SG_ 1032 RR_CAN_DET_AMPLITUDE_063 "Detected object amplitude 01";
BA_ "GenSigStartValue" SG_ 1032 RR_CAN_DET_AMPLITUDE_063 64;
BA_ "GenSigStartValue" SG_ 1032 RR_CAN_DET_ELEVATION_062 63.8646288209607;
BA_ "GenSigCmt" SG_ 1032 RR_CAN_DET_AZIMUTH_062 "Detected object azimuth position 01";
BA_ "GenSigStartValue" SG_ 1032 RR_CAN_DET_AZIMUTH_062 8194.10934583694;
BA_ "GenSigStartValue" SG_ 1032 RR_CAN_DET_RANGE_RATE_062 8192;
BA_ "GenSigCmt" SG_ 1032 RR_CAN_DET_AMPLITUDE_062 "Detected object amplitude 01";
BA_ "GenSigStartValue" SG_ 1032 RR_CAN_DET_AMPLITUDE_062 64;
BA_ "GenSigStartValue" SG_ 1032 RR_CAN_DET_ELEVATION_061 63.8646288209607;
BA_ "GenSigCmt" SG_ 1032 RR_CAN_DET_AZIMUTH_061 "Detected object azimuth position 01";
BA_ "GenSigStartValue" SG_ 1032 RR_CAN_DET_AZIMUTH_061 8194.10934583694;
BA_ "GenSigStartValue" SG_ 1032 RR_CAN_DET_RANGE_RATE_061 8192;
BA_ "GenSigCmt" SG_ 1032 RR_CAN_DET_AMPLITUDE_061 "Detected object amplitude 01";
BA_ "GenSigStartValue" SG_ 1032 RR_CAN_DET_AMPLITUDE_061 64;
BA_ "GenSigStartValue" SG_ 1032 RR_CAN_DET_ELEVATION_060 63.8646288209607;
BA_ "GenSigCmt" SG_ 1032 RR_CAN_DET_AZIMUTH_060 "Detected object azimuth position 01";
BA_ "GenSigStartValue" SG_ 1032 RR_CAN_DET_AZIMUTH_060 8194.10934583694;
BA_ "GenSigStartValue" SG_ 1032 RR_CAN_DET_RANGE_RATE_060 8192;
BA_ "GenSigCmt" SG_ 1032 RR_CAN_DET_AMPLITUDE_060 "Detected object amplitude 01";
BA_ "GenSigStartValue" SG_ 1032 RR_CAN_DET_AMPLITUDE_060 64;
BA_ "GenSigStartValue" SG_ 1032 RR_CAN_DET_ELEVATION_059 63.8646288209607;
BA_ "GenSigCmt" SG_ 1032 RR_CAN_DET_AZIMUTH_059 "Detected object azimuth position 01";
BA_ "GenSigStartValue" SG_ 1032 RR_CAN_DET_AZIMUTH_059 8194.10934583694;
BA_ "GenSigStartValue" SG_ 1032 RR_CAN_DET_RANGE_RATE_059 8192;
BA_ "GenSigCmt" SG_ 1032 RR_CAN_DET_AMPLITUDE_059 "Detected object amplitude 01";
BA_ "GenSigStartValue" SG_ 1032 RR_CAN_DET_AMPLITUDE_059 64;
BA_ "GenSigStartValue" SG_ 1032 RR_CAN_DET_ELEVATION_058 63.8646288209607;
BA_ "GenSigCmt" SG_ 1032 RR_CAN_DET_AZIMUTH_058 "Detected object azimuth position 01";
BA_ "GenSigStartValue" SG_ 1032 RR_CAN_DET_AZIMUTH_058 8194.10934583694;
BA_ "GenSigStartValue" SG_ 1032 RR_CAN_DET_RANGE_RATE_058 8192;
BA_ "GenSigCmt" SG_ 1032 RR_CAN_DET_AMPLITUDE_058 "Detected object amplitude 01";
BA_ "GenSigStartValue" SG_ 1032 RR_CAN_DET_AMPLITUDE_058 64;
BA_ "GenSigCmt" SG_ 1033 RR_CAN_DET_ELEVATION_064 "Detected object elevation position 01";
BA_ "GenSigStartValue" SG_ 1033 RR_CAN_DET_ELEVATION_064 63.8646288209607;
BA_ "GenSigCmt" SG_ 1033 RR_CAN_DET_CONFID_AZIMUTH_064 "Signal to noise level 01";
BA_ "GenSigVtName" SG_ 1033 RR_CAN_DET_CONFID_AZIMUTH_064 "VtSig_CAN_SNR_LEVEL_01";
BA_ "GenSigVtEn" SG_ 1033 RR_CAN_DET_CONFID_AZIMUTH_064 "TRUE";
BA_ "GenSigCmt" SG_ 1033 RR_CAN_DET_SUPER_RES_TARGET_064 "Super resolution target 01";
BA_ "GenSigCmt" SG_ 1033 RR_CAN_DET_CONFID_ELEVATION_064 "Near discrimination target 01";
BA_ "GenSigCmt" SG_ 1033 RR_CAN_DET_HOST_VEH_CLUTTER_064 "Host vehicle clutter 01";
BA_ "GenSigCmt" SG_ 1033 RR_CAN_DET_VALID_LEVEL_064 "Detected object valid level 01";
BA_ "GenSigCmt" SG_ 1033 RR_CAN_DET_AZIMUTH_064 "Detected object azimuth position 01";
BA_ "GenSigStartValue" SG_ 1033 RR_CAN_DET_AZIMUTH_064 8194.10934583694;
BA_ "GenSigCmt" SG_ 1033 RR_CAN_DET_RANGE_064 "Detected object range 01";
BA_ "GenSigCmt" SG_ 1033 RR_CAN_DET_RANGE_RATE_064 "Detected object range rate 01";
BA_ "GenSigStartValue" SG_ 1033 RR_CAN_DET_RANGE_RATE_064 8192;
BA_ "GenSigCmt" SG_ 1033 RR_CAN_DET_AMPLITUDE_064 "Detected object amplitude 01";
BA_ "GenSigStartValue" SG_ 1033 RR_CAN_DET_AMPLITUDE_064 64;
BA_ "GenSigCmt" SG_ 1033 RR_CAN_SCAN_INDEX_2LSB_064 "The two LSB of scan index 01";
VAL_ 776 RL_CAN_DET_CONFID_AZIMUTH_057 3 "Low" 2 "MidLow" 1 "MidHigh" 0 "High" ;
VAL_ 776 RL_CAN_DET_CONFID_AZIMUTH_063 3 "Low" 2 "MidLow" 1 "MidHigh" 0 "High" ;
VAL_ 776 RL_CAN_DET_CONFID_AZIMUTH_062 3 "Low" 2 "MidLow" 1 "MidHigh" 0 "High" ;
VAL_ 776 RL_CAN_DET_CONFID_AZIMUTH_061 3 "Low" 2 "MidLow" 1 "MidHigh" 0 "High" ;
VAL_ 776 RL_CAN_DET_CONFID_AZIMUTH_060 3 "Low" 2 "MidLow" 1 "MidHigh" 0 "High" ;
VAL_ 776 RL_CAN_DET_CONFID_AZIMUTH_059 3 "Low" 2 "MidLow" 1 "MidHigh" 0 "High" ;
VAL_ 776 RL_CAN_DET_CONFID_AZIMUTH_058 3 "Low" 2 "MidLow" 1 "MidHigh" 0 "High" ;
VAL_ 777 RL_CAN_DET_CONFID_AZIMUTH_064 3 "Low" 2 "MidLow" 1 "MidHigh" 0 "High" ;
VAL_ 1024 RR_CAN_DET_CONFID_AZIMUTH_007 3 "Low" 2 "MidLow" 1 "MidHigh" 0 "High" ;
VAL_ 1024 RR_CAN_DET_CONFID_AZIMUTH_006 3 "Low" 2 "MidLow" 1 "MidHigh" 0 "High" ;
VAL_ 1024 RR_CAN_DET_CONFID_AZIMUTH_005 3 "Low" 2 "MidLow" 1 "MidHigh" 0 "High" ;
VAL_ 1024 RR_CAN_DET_CONFID_AZIMUTH_004 3 "Low" 2 "MidLow" 1 "MidHigh" 0 "High" ;
VAL_ 1024 RR_CAN_DET_CONFID_AZIMUTH_003 3 "Low" 2 "MidLow" 1 "MidHigh" 0 "High" ;
VAL_ 1024 RR_CAN_DET_CONFID_AZIMUTH_002 3 "Low" 2 "MidLow" 1 "MidHigh" 0 "High" ;
VAL_ 1024 RR_CAN_DET_CONFID_AZIMUTH_001 3 "Low" 2 "MidLow" 1 "MidHigh" 0 "High" ;
VAL_ 1025 RR_CAN_DET_CONFID_AZIMUTH_008 3 "Low" 2 "MidLow" 1 "MidHigh" 0 "High" ;
VAL_ 1025 RR_CAN_DET_CONFID_AZIMUTH_014 3 "Low" 2 "MidLow" 1 "MidHigh" 0 "High" ;
VAL_ 1025 RR_CAN_DET_CONFID_AZIMUTH_013 3 "Low" 2 "MidLow" 1 "MidHigh" 0 "High" ;
VAL_ 1025 RR_CAN_DET_CONFID_AZIMUTH_012 3 "Low" 2 "MidLow" 1 "MidHigh" 0 "High" ;
VAL_ 1025 RR_CAN_DET_CONFID_AZIMUTH_011 3 "Low" 2 "MidLow" 1 "MidHigh" 0 "High" ;
VAL_ 1025 RR_CAN_DET_CONFID_AZIMUTH_010 3 "Low" 2 "MidLow" 1 "MidHigh" 0 "High" ;
VAL_ 1025 RR_CAN_DET_CONFID_AZIMUTH_009 3 "Low" 2 "MidLow" 1 "MidHigh" 0 "High" ;
VAL_ 1026 RR_CAN_DET_CONFID_AZIMUTH_015 3 "Low" 2 "MidLow" 1 "MidHigh" 0 "High" ;
VAL_ 1026 RR_CAN_DET_CONFID_AZIMUTH_021 3 "Low" 2 "MidLow" 1 "MidHigh" 0 "High" ;
VAL_ 1026 RR_CAN_DET_CONFID_AZIMUTH_020 3 "Low" 2 "MidLow" 1 "MidHigh" 0 "High" ;
VAL_ 1026 RR_CAN_DET_CONFID_AZIMUTH_019 3 "Low" 2 "MidLow" 1 "MidHigh" 0 "High" ;
VAL_ 1026 RR_CAN_DET_CONFID_AZIMUTH_018 3 "Low" 2 "MidLow" 1 "MidHigh" 0 "High" ;
VAL_ 1026 RR_CAN_DET_CONFID_AZIMUTH_017 3 "Low" 2 "MidLow" 1 "MidHigh" 0 "High" ;
VAL_ 1026 RR_CAN_DET_CONFID_AZIMUTH_016 3 "Low" 2 "MidLow" 1 "MidHigh" 0 "High" ;
VAL_ 1027 RR_CAN_DET_CONFID_AZIMUTH_022 3 "Low" 2 "MidLow" 1 "MidHigh" 0 "High" ;
VAL_ 1027 RR_CAN_DET_CONFID_AZIMUTH_028 3 "Low" 2 "MidLow" 1 "MidHigh" 0 "High" ;
VAL_ 1027 RR_CAN_DET_CONFID_AZIMUTH_027 3 "Low" 2 "MidLow" 1 "MidHigh" 0 "High" ;
VAL_ 1027 RR_CAN_DET_CONFID_AZIMUTH_026 3 "Low" 2 "MidLow" 1 "MidHigh" 0 "High" ;
VAL_ 1027 RR_CAN_DET_CONFID_AZIMUTH_025 3 "Low" 2 "MidLow" 1 "MidHigh" 0 "High" ;
VAL_ 1027 RR_CAN_DET_CONFID_AZIMUTH_024 3 "Low" 2 "MidLow" 1 "MidHigh" 0 "High" ;
VAL_ 1027 RR_CAN_DET_CONFID_AZIMUTH_023 0 "High" 1 "MidHigh" 2 "MidLow" 3 "Low" ;
VAL_ 1028 RR_CAN_DET_CONFID_AZIMUTH_029 3 "Low" 2 "MidLow" 1 "MidHigh" 0 "High" ;
VAL_ 1028 RR_CAN_DET_CONFID_AZIMUTH_035 3 "Low" 2 "MidLow" 1 "MidHigh" 0 "High" ;
VAL_ 1028 RR_CAN_DET_CONFID_AZIMUTH_034 3 "Low" 2 "MidLow" 1 "MidHigh" 0 "High" ;
VAL_ 1028 RR_CAN_DET_CONFID_AZIMUTH_033 3 "Low" 2 "MidLow" 1 "MidHigh" 0 "High" ;
VAL_ 1028 RR_CAN_DET_CONFID_AZIMUTH_032 3 "Low" 2 "MidLow" 1 "MidHigh" 0 "High" ;
VAL_ 1028 RR_CAN_DET_CONFID_AZIMUTH_031 3 "Low" 2 "MidLow" 1 "MidHigh" 0 "High" ;
VAL_ 1028 RR_CAN_DET_CONFID_AZIMUTH_030 3 "Low" 2 "MidLow" 1 "MidHigh" 0 "High" ;
VAL_ 1029 RR_CAN_DET_CONFID_AZIMUTH_036 3 "Low" 2 "MidLow" 1 "MidHigh" 0 "High" ;
VAL_ 1029 RR_CAN_DET_CONFID_AZIMUTH_042 3 "Low" 2 "MidLow" 1 "MidHigh" 0 "High" ;
VAL_ 1029 RR_CAN_DET_CONFID_AZIMUTH_041 3 "Low" 2 "MidLow" 1 "MidHigh" 0 "High" ;
VAL_ 1029 RR_CAN_DET_CONFID_AZIMUTH_040 3 "Low" 2 "MidLow" 1 "MidHigh" 0 "High" ;
VAL_ 1029 RR_CAN_DET_CONFID_AZIMUTH_039 3 "Low" 2 "MidLow" 1 "MidHigh" 0 "High" ;
VAL_ 1029 RR_CAN_DET_CONFID_AZIMUTH_038 3 "Low" 2 "MidLow" 1 "MidHigh" 0 "High" ;
VAL_ 1029 RR_CAN_DET_CONFID_AZIMUTH_037 3 "Low" 2 "MidLow" 1 "MidHigh" 0 "High" ;
VAL_ 1030 RR_CAN_DET_CONFID_AZIMUTH_043 3 "Low" 2 "MidLow" 1 "MidHigh" 0 "High" ;
VAL_ 1030 RR_CAN_DET_CONFID_AZIMUTH_049 3 "Low" 2 "MidLow" 1 "MidHigh" 0 "High" ;
VAL_ 1030 RR_CAN_DET_CONFID_AZIMUTH_048 3 "Low" 2 "MidLow" 1 "MidHigh" 0 "High" ;
VAL_ 1030 RR_CAN_DET_CONFID_AZIMUTH_047 3 "Low" 2 "MidLow" 1 "MidHigh" 0 "High" ;
VAL_ 1030 RR_CAN_DET_CONFID_AZIMUTH_046 3 "Low" 2 "MidLow" 1 "MidHigh" 0 "High" ;
VAL_ 1030 RR_CAN_DET_CONFID_AZIMUTH_045 3 "Low" 2 "MidLow" 1 "MidHigh" 0 "High" ;
VAL_ 1030 RR_CAN_DET_CONFID_AZIMUTH_044 3 "Low" 2 "MidLow" 1 "MidHigh" 0 "High" ;
VAL_ 1031 RR_CAN_DET_CONFID_AZIMUTH_050 3 "Low" 2 "MidLow" 1 "MidHigh" 0 "High" ;
VAL_ 1031 RR_CAN_DET_CONFID_AZIMUTH_056 3 "Low" 2 "MidLow" 1 "MidHigh" 0 "High" ;
VAL_ 1031 RR_CAN_DET_CONFID_AZIMUTH_055 3 "Low" 2 "MidLow" 1 "MidHigh" 0 "High" ;
VAL_ 1031 RR_CAN_DET_CONFID_AZIMUTH_054 3 "Low" 2 "MidLow" 1 "MidHigh" 0 "High" ;
VAL_ 1031 RR_CAN_DET_CONFID_AZIMUTH_053 3 "Low" 2 "MidLow" 1 "MidHigh" 0 "High" ;
VAL_ 1031 RR_CAN_DET_CONFID_AZIMUTH_052 3 "Low" 2 "MidLow" 1 "MidHigh" 0 "High" ;
VAL_ 1031 RR_CAN_DET_CONFID_AZIMUTH_051 3 "Low" 2 "MidLow" 1 "MidHigh" 0 "High" ;
VAL_ 1032 RR_CAN_DET_CONFID_AZIMUTH_057 3 "Low" 2 "MidLow" 1 "MidHigh" 0 "High" ;
VAL_ 1032 RR_CAN_DET_CONFID_AZIMUTH_063 3 "Low" 2 "MidLow" 1 "MidHigh" 0 "High" ;
VAL_ 1032 RR_CAN_DET_CONFID_AZIMUTH_062 3 "Low" 2 "MidLow" 1 "MidHigh" 0 "High" ;
VAL_ 1032 RR_CAN_DET_CONFID_AZIMUTH_061 3 "Low" 2 "MidLow" 1 "MidHigh" 0 "High" ;
VAL_ 1032 RR_CAN_DET_CONFID_AZIMUTH_060 3 "Low" 2 "MidLow" 1 "MidHigh" 0 "High" ;
VAL_ 1032 RR_CAN_DET_CONFID_AZIMUTH_059 3 "Low" 2 "MidLow" 1 "MidHigh" 0 "High" ;
VAL_ 1032 RR_CAN_DET_CONFID_AZIMUTH_058 3 "Low" 2 "MidLow" 1 "MidHigh" 0 "High" ;
VAL_ 1033 RR_CAN_DET_CONFID_AZIMUTH_064 3 "Low" 2 "MidLow" 1 "MidHigh" 0 "High" ;
SIG_GROUP_ 776 RL_Detection_057 1 : RL_CAN_DET_ELEVATION_057 RL_CAN_DET_CONFID_AZIMUTH_057 RL_CAN_DET_SUPER_RES_TARGET_057 RL_CAN_DET_CONFID_ELEVATION_057 RL_CAN_DET_HOST_VEH_CLUTTER_057 RL_CAN_DET_VALID_LEVEL_057 RL_CAN_DET_AZIMUTH_057 RL_CAN_DET_RANGE_057 RL_CAN_DET_RANGE_RATE_057 RL_CAN_DET_AMPLITUDE_057 RL_CAN_SCAN_INDEX_2LSB_057;
SIG_GROUP_ 776 RL_Detection_058 1 : RL_CAN_DET_ELEVATION_058 RL_CAN_DET_CONFID_AZIMUTH_058 RL_CAN_DET_SUPER_RES_TARGET_058 RL_CAN_DET_CONFID_ELEVATION_058 RL_CAN_DET_HOST_VEH_CLUTTER_058 RL_CAN_DET_VALID_LEVEL_058 RL_CAN_DET_AZIMUTH_058 RL_CAN_DET_RANGE_058 RL_CAN_DET_RANGE_RATE_058 RL_CAN_DET_AMPLITUDE_058 RL_CAN_SCAN_INDEX_2LSB_058;
SIG_GROUP_ 776 RL_Detection_059 1 : RL_CAN_DET_ELEVATION_059 RL_CAN_DET_CONFID_AZIMUTH_059 RL_CAN_DET_SUPER_RES_TARGET_059 RL_CAN_DET_CONFID_ELEVATION_059 RL_CAN_DET_HOST_VEH_CLUTTER_059 RL_CAN_DET_VALID_LEVEL_059 RL_CAN_DET_AZIMUTH_059 RL_CAN_DET_RANGE_059 RL_CAN_DET_RANGE_RATE_059 RL_CAN_DET_AMPLITUDE_059 RL_CAN_SCAN_INDEX_2LSB_059;
SIG_GROUP_ 776 RL_Detection_060 1 : RL_CAN_DET_ELEVATION_060 RL_CAN_DET_CONFID_AZIMUTH_060 RL_CAN_DET_SUPER_RES_TARGET_060 RL_CAN_DET_CONFID_ELEVATION_060 RL_CAN_DET_HOST_VEH_CLUTTER_060 RL_CAN_DET_VALID_LEVEL_060 RL_CAN_DET_AZIMUTH_060 RL_CAN_DET_RANGE_060 RL_CAN_DET_RANGE_RATE_060 RL_CAN_DET_AMPLITUDE_060 RL_CAN_SCAN_INDEX_2LSB_060;
SIG_GROUP_ 776 RL_Detection_061 1 : RL_CAN_DET_ELEVATION_061 RL_CAN_DET_CONFID_AZIMUTH_061 RL_CAN_DET_SUPER_RES_TARGET_061 RL_CAN_DET_CONFID_ELEVATION_061 RL_CAN_DET_HOST_VEH_CLUTTER_061 RL_CAN_DET_VALID_LEVEL_061 RL_CAN_DET_AZIMUTH_061 RL_CAN_DET_RANGE_061 RL_CAN_DET_RANGE_RATE_061 RL_CAN_DET_AMPLITUDE_061 RL_CAN_SCAN_INDEX_2LSB_061;
SIG_GROUP_ 776 RL_Detection_062 1 : RL_CAN_DET_ELEVATION_062 RL_CAN_DET_CONFID_AZIMUTH_062 RL_CAN_DET_SUPER_RES_TARGET_062 RL_CAN_DET_CONFID_ELEVATION_062 RL_CAN_DET_HOST_VEH_CLUTTER_062 RL_CAN_DET_VALID_LEVEL_062 RL_CAN_DET_AZIMUTH_062 RL_CAN_DET_RANGE_062 RL_CAN_DET_RANGE_RATE_062 RL_CAN_DET_AMPLITUDE_062 RL_CAN_SCAN_INDEX_2LSB_062;
SIG_GROUP_ 776 RL_Detection_063 1 : RL_CAN_DET_ELEVATION_063 RL_CAN_DET_CONFID_AZIMUTH_063 RL_CAN_DET_SUPER_RES_TARGET_063 RL_CAN_DET_CONFID_ELEVATION_063 RL_CAN_DET_HOST_VEH_CLUTTER_063 RL_CAN_DET_VALID_LEVEL_063 RL_CAN_DET_AZIMUTH_063 RL_CAN_DET_RANGE_063 RL_CAN_DET_RANGE_RATE_063 RL_CAN_DET_AMPLITUDE_063 RL_CAN_SCAN_INDEX_2LSB_063;
SIG_GROUP_ 777 RL_Detection_064 1 : RL_CAN_DET_ELEVATION_064 RL_CAN_DET_CONFID_AZIMUTH_064 RL_CAN_DET_SUPER_RES_TARGET_064 RL_CAN_DET_CONFID_ELEVATION_064 RL_CAN_DET_HOST_VEH_CLUTTER_064 RL_CAN_DET_VALID_LEVEL_064 RL_CAN_DET_AZIMUTH_064 RL_CAN_DET_RANGE_064 RL_CAN_DET_RANGE_RATE_064 RL_CAN_DET_AMPLITUDE_064 RL_CAN_SCAN_INDEX_2LSB_064;
SIG_GROUP_ 1024 RR_Detection_001 1 : RR_CAN_DET_ELEVATION_001 RR_CAN_DET_CONFID_AZIMUTH_001 RR_CAN_DET_SUPER_RES_TARGET_001 RR_CAN_DET_CONFID_ELEVATION_001 RR_CAN_DET_HOST_VEH_CLUTTER_001 RR_CAN_DET_VALID_LEVEL_001 RR_CAN_DET_AZIMUTH_001 RR_CAN_DET_RANGE_001 RR_CAN_DET_RANGE_RATE_001 RR_CAN_DET_AMPLITUDE_001 RR_CAN_SCAN_INDEX_2LSB_001;
SIG_GROUP_ 1024 RR_Detection_002 1 : RR_CAN_DET_ELEVATION_002 RR_CAN_DET_CONFID_AZIMUTH_002 RR_CAN_DET_SUPER_RES_TARGET_002 RR_CAN_DET_CONFID_ELEVATION_002 RR_CAN_DET_HOST_VEH_CLUTTER_002 RR_CAN_DET_VALID_LEVEL_002 RR_CAN_DET_AZIMUTH_002 RR_CAN_DET_RANGE_002 RR_CAN_DET_RANGE_RATE_002 RR_CAN_DET_AMPLITUDE_002 RR_CAN_SCAN_INDEX_2LSB_002;
SIG_GROUP_ 1024 RR_Detection_003 1 : RR_CAN_DET_ELEVATION_003 RR_CAN_DET_CONFID_AZIMUTH_003 RR_CAN_DET_SUPER_RES_TARGET_003 RR_CAN_DET_CONFID_ELEVATION_003 RR_CAN_DET_HOST_VEH_CLUTTER_003 RR_CAN_DET_VALID_LEVEL_003 RR_CAN_DET_AZIMUTH_003 RR_CAN_DET_RANGE_003 RR_CAN_DET_RANGE_RATE_003 RR_CAN_DET_AMPLITUDE_003 RR_CAN_SCAN_INDEX_2LSB_003;
SIG_GROUP_ 1024 RR_Detection_004 1 : RR_CAN_DET_ELEVATION_004 RR_CAN_DET_CONFID_AZIMUTH_004 RR_CAN_DET_SUPER_RES_TARGET_004 RR_CAN_DET_CONFID_ELEVATION_004 RR_CAN_DET_HOST_VEH_CLUTTER_004 RR_CAN_DET_VALID_LEVEL_004 RR_CAN_DET_AZIMUTH_004 RR_CAN_DET_RANGE_004 RR_CAN_DET_RANGE_RATE_004 RR_CAN_DET_AMPLITUDE_004 RR_CAN_SCAN_INDEX_2LSB_004;
SIG_GROUP_ 1024 RR_Detection_005 1 : RR_CAN_DET_ELEVATION_005 RR_CAN_DET_CONFID_AZIMUTH_005 RR_CAN_DET_SUPER_RES_TARGET_005 RR_CAN_DET_CONFID_ELEVATION_005 RR_CAN_DET_HOST_VEH_CLUTTER_005 RR_CAN_DET_VALID_LEVEL_005 RR_CAN_DET_AZIMUTH_005 RR_CAN_DET_RANGE_005 RR_CAN_DET_RANGE_RATE_005 RR_CAN_DET_AMPLITUDE_005 RR_CAN_SCAN_INDEX_2LSB_005;
SIG_GROUP_ 1024 RR_Detection_006 1 : RR_CAN_DET_ELEVATION_006 RR_CAN_DET_CONFID_AZIMUTH_006 RR_CAN_DET_SUPER_RES_TARGET_006 RR_CAN_DET_CONFID_ELEVATION_006 RR_CAN_DET_HOST_VEH_CLUTTER_006 RR_CAN_DET_VALID_LEVEL_006 RR_CAN_DET_AZIMUTH_006 RR_CAN_DET_RANGE_006 RR_CAN_DET_RANGE_RATE_006 RR_CAN_DET_AMPLITUDE_006 RR_CAN_SCAN_INDEX_2LSB_006;
SIG_GROUP_ 1024 RR_Detection_007 1 : RR_CAN_DET_ELEVATION_007 RR_CAN_DET_CONFID_AZIMUTH_007 RR_CAN_DET_SUPER_RES_TARGET_007 RR_CAN_DET_CONFID_ELEVATION_007 RR_CAN_DET_HOST_VEH_CLUTTER_007 RR_CAN_DET_VALID_LEVEL_007 RR_CAN_DET_AZIMUTH_007 RR_CAN_DET_RANGE_007 RR_CAN_DET_RANGE_RATE_007 RR_CAN_DET_AMPLITUDE_007 RR_CAN_SCAN_INDEX_2LSB_007;
SIG_GROUP_ 1025 RR_Detection_008 1 : RR_CAN_DET_ELEVATION_008 RR_CAN_DET_CONFID_AZIMUTH_008 RR_CAN_DET_SUPER_RES_TARGET_008 RR_CAN_DET_CONFID_ELEVATION_008 RR_CAN_DET_HOST_VEH_CLUTTER_008 RR_CAN_DET_VALID_LEVEL_008 RR_CAN_DET_AZIMUTH_008 RR_CAN_DET_RANGE_008 RR_CAN_DET_RANGE_RATE_008 RR_CAN_DET_AMPLITUDE_008 RR_CAN_SCAN_INDEX_2LSB_008;
SIG_GROUP_ 1025 RR_Detection_009 1 : RR_CAN_DET_ELEVATION_009 RR_CAN_DET_CONFID_AZIMUTH_009 RR_CAN_DET_SUPER_RES_TARGET_009 RR_CAN_DET_CONFID_ELEVATION_009 RR_CAN_DET_HOST_VEH_CLUTTER_009 RR_CAN_DET_VALID_LEVEL_009 RR_CAN_DET_AZIMUTH_009 RR_CAN_DET_RANGE_009 RR_CAN_DET_RANGE_RATE_009 RR_CAN_DET_AMPLITUDE_009 RR_CAN_SCAN_INDEX_2LSB_009;
SIG_GROUP_ 1025 RR_Detection_010 1 : RR_CAN_DET_ELEVATION_010 RR_CAN_DET_CONFID_AZIMUTH_010 RR_CAN_DET_SUPER_RES_TARGET_010 RR_CAN_DET_CONFID_ELEVATION_010 RR_CAN_DET_HOST_VEH_CLUTTER_010 RR_CAN_DET_VALID_LEVEL_010 RR_CAN_DET_AZIMUTH_010 RR_CAN_DET_RANGE_010 RR_CAN_DET_RANGE_RATE_010 RR_CAN_DET_AMPLITUDE_010 RR_CAN_SCAN_INDEX_2LSB_010;
SIG_GROUP_ 1025 RR_Detection_011 1 : RR_CAN_DET_ELEVATION_011 RR_CAN_DET_CONFID_AZIMUTH_011 RR_CAN_DET_SUPER_RES_TARGET_011 RR_CAN_DET_CONFID_ELEVATION_011 RR_CAN_DET_HOST_VEH_CLUTTER_011 RR_CAN_DET_VALID_LEVEL_011 RR_CAN_DET_AZIMUTH_011 RR_CAN_DET_RANGE_011 RR_CAN_DET_RANGE_RATE_011 RR_CAN_DET_AMPLITUDE_011 RR_CAN_SCAN_INDEX_2LSB_011;
SIG_GROUP_ 1025 RR_Detection_012 1 : RR_CAN_DET_ELEVATION_012 RR_CAN_DET_CONFID_AZIMUTH_012 RR_CAN_DET_SUPER_RES_TARGET_012 RR_CAN_DET_CONFID_ELEVATION_012 RR_CAN_DET_HOST_VEH_CLUTTER_012 RR_CAN_DET_VALID_LEVEL_012 RR_CAN_DET_AZIMUTH_012 RR_CAN_DET_RANGE_012 RR_CAN_DET_RANGE_RATE_012 RR_CAN_DET_AMPLITUDE_012 RR_CAN_SCAN_INDEX_2LSB_012;
SIG_GROUP_ 1025 RR_Detection_013 1 : RR_CAN_DET_ELEVATION_013 RR_CAN_DET_CONFID_AZIMUTH_013 RR_CAN_DET_SUPER_RES_TARGET_013 RR_CAN_DET_CONFID_ELEVATION_013 RR_CAN_DET_HOST_VEH_CLUTTER_013 RR_CAN_DET_VALID_LEVEL_013 RR_CAN_DET_AZIMUTH_013 RR_CAN_DET_RANGE_013 RR_CAN_DET_RANGE_RATE_013 RR_CAN_DET_AMPLITUDE_013 RR_CAN_SCAN_INDEX_2LSB_013;
SIG_GROUP_ 1025 RR_Detection_014 1 : RR_CAN_DET_ELEVATION_014 RR_CAN_DET_CONFID_AZIMUTH_014 RR_CAN_DET_SUPER_RES_TARGET_014 RR_CAN_DET_CONFID_ELEVATION_014 RR_CAN_DET_HOST_VEH_CLUTTER_014 RR_CAN_DET_VALID_LEVEL_014 RR_CAN_DET_AZIMUTH_014 RR_CAN_DET_RANGE_014 RR_CAN_DET_RANGE_RATE_014 RR_CAN_DET_AMPLITUDE_014 RR_CAN_SCAN_INDEX_2LSB_014;
SIG_GROUP_ 1026 RR_Detection_015 1 : RR_CAN_DET_ELEVATION_015 RR_CAN_DET_CONFID_AZIMUTH_015 RR_CAN_DET_SUPER_RES_TARGET_015 RR_CAN_DET_CONFID_ELEVATION_015 RR_CAN_DET_HOST_VEH_CLUTTER_015 RR_CAN_DET_VALID_LEVEL_015 RR_CAN_DET_AZIMUTH_015 RR_CAN_DET_RANGE_015 RR_CAN_DET_RANGE_RATE_015 RR_CAN_DET_AMPLITUDE_015 RR_CAN_SCAN_INDEX_2LSB_015;
SIG_GROUP_ 1026 RR_Detection_016 1 : RR_CAN_DET_ELEVATION_016 RR_CAN_DET_CONFID_AZIMUTH_016 RR_CAN_DET_SUPER_RES_TARGET_016 RR_CAN_DET_CONFID_ELEVATION_016 RR_CAN_DET_HOST_VEH_CLUTTER_016 RR_CAN_DET_VALID_LEVEL_016 RR_CAN_DET_AZIMUTH_016 RR_CAN_DET_RANGE_016 RR_CAN_DET_RANGE_RATE_016 RR_CAN_DET_AMPLITUDE_016 RR_CAN_SCAN_INDEX_2LSB_016;
SIG_GROUP_ 1026 RR_Detection_017 1 : RR_CAN_DET_ELEVATION_017 RR_CAN_DET_CONFID_AZIMUTH_017 RR_CAN_DET_SUPER_RES_TARGET_017 RR_CAN_DET_CONFID_ELEVATION_017 RR_CAN_DET_HOST_VEH_CLUTTER_017 RR_CAN_DET_VALID_LEVEL_017 RR_CAN_DET_AZIMUTH_017 RR_CAN_DET_RANGE_017 RR_CAN_DET_RANGE_RATE_017 RR_CAN_DET_AMPLITUDE_017 RR_CAN_SCAN_INDEX_2LSB_017;
SIG_GROUP_ 1026 RR_Detection_018 1 : RR_CAN_DET_ELEVATION_018 RR_CAN_DET_CONFID_AZIMUTH_018 RR_CAN_DET_SUPER_RES_TARGET_018 RR_CAN_DET_CONFID_ELEVATION_018 RR_CAN_DET_HOST_VEH_CLUTTER_018 RR_CAN_DET_VALID_LEVEL_018 RR_CAN_DET_AZIMUTH_018 RR_CAN_DET_RANGE_018 RR_CAN_DET_RANGE_RATE_018 RR_CAN_DET_AMPLITUDE_018 RR_CAN_SCAN_INDEX_2LSB_018;
SIG_GROUP_ 1026 RR_Detection_019 1 : RR_CAN_DET_ELEVATION_019 RR_CAN_DET_CONFID_AZIMUTH_019 RR_CAN_DET_SUPER_RES_TARGET_019 RR_CAN_DET_CONFID_ELEVATION_019 RR_CAN_DET_HOST_VEH_CLUTTER_019 RR_CAN_DET_VALID_LEVEL_019 RR_CAN_DET_AZIMUTH_019 RR_CAN_DET_RANGE_019 RR_CAN_DET_RANGE_RATE_019 RR_CAN_DET_AMPLITUDE_019 RR_CAN_SCAN_INDEX_2LSB_019;
SIG_GROUP_ 1026 RR_Detection_020 1 : RR_CAN_DET_ELEVATION_020 RR_CAN_DET_CONFID_AZIMUTH_020 RR_CAN_DET_SUPER_RES_TARGET_020 RR_CAN_DET_CONFID_ELEVATION_020 RR_CAN_DET_HOST_VEH_CLUTTER_020 RR_CAN_DET_VALID_LEVEL_020 RR_CAN_DET_AZIMUTH_020 RR_CAN_DET_RANGE_020 RR_CAN_DET_RANGE_RATE_020 RR_CAN_DET_AMPLITUDE_020 RR_CAN_SCAN_INDEX_2LSB_020;
SIG_GROUP_ 1026 RR_Detection_021 1 : RR_CAN_DET_ELEVATION_021 RR_CAN_DET_CONFID_AZIMUTH_021 RR_CAN_DET_SUPER_RES_TARGET_021 RR_CAN_DET_CONFID_ELEVATION_021 RR_CAN_DET_HOST_VEH_CLUTTER_021 RR_CAN_DET_VALID_LEVEL_021 RR_CAN_DET_AZIMUTH_021 RR_CAN_DET_RANGE_021 RR_CAN_DET_RANGE_RATE_021 RR_CAN_DET_AMPLITUDE_021 RR_CAN_SCAN_INDEX_2LSB_021;
SIG_GROUP_ 1027 RR_Detection_022 1 : RR_CAN_DET_ELEVATION_022 RR_CAN_DET_CONFID_AZIMUTH_022 RR_CAN_DET_SUPER_RES_TARGET_022 RR_CAN_DET_CONFID_ELEVATION_022 RR_CAN_DET_HOST_VEH_CLUTTER_022 RR_CAN_DET_VALID_LEVEL_022 RR_CAN_DET_AZIMUTH_022 RR_CAN_DET_RANGE_022 RR_CAN_DET_RANGE_RATE_022 RR_CAN_DET_AMPLITUDE_022 RR_CAN_SCAN_INDEX_2LSB_022;
SIG_GROUP_ 1027 RR_Detection_023 1 : RR_CAN_DET_ELEVATION_023 RR_CAN_DET_CONFID_AZIMUTH_023 RR_CAN_DET_SUPER_RES_TARGET_023 RR_CAN_DET_CONFID_ELEVATION_023 RR_CAN_DET_HOST_VEH_CLUTTER_023 RR_CAN_DET_VALID_LEVEL_023 RR_CAN_DET_AZIMUTH_023 RR_CAN_DET_RANGE_023 RR_CAN_DET_RANGE_RATE_023 RR_CAN_DET_AMPLITUDE_023 RR_CAN_SCAN_INDEX_2LSB_023;
SIG_GROUP_ 1027 RR_Detection_024 1 : RR_CAN_DET_ELEVATION_024 RR_CAN_DET_CONFID_AZIMUTH_024 RR_CAN_DET_SUPER_RES_TARGET_024 RR_CAN_DET_CONFID_ELEVATION_024 RR_CAN_DET_HOST_VEH_CLUTTER_024 RR_CAN_DET_VALID_LEVEL_024 RR_CAN_DET_AZIMUTH_024 RR_CAN_DET_RANGE_024 RR_CAN_DET_RANGE_RATE_024 RR_CAN_DET_AMPLITUDE_024 RR_CAN_SCAN_INDEX_2LSB_024;
SIG_GROUP_ 1027 RR_Detection_025 1 : RR_CAN_DET_ELEVATION_025 RR_CAN_DET_CONFID_AZIMUTH_025 RR_CAN_DET_SUPER_RES_TARGET_025 RR_CAN_DET_CONFID_ELEVATION_025 RR_CAN_DET_HOST_VEH_CLUTTER_025 RR_CAN_DET_VALID_LEVEL_025 RR_CAN_DET_AZIMUTH_025 RR_CAN_DET_RANGE_025 RR_CAN_DET_RANGE_RATE_025 RR_CAN_DET_AMPLITUDE_025 RR_CAN_SCAN_INDEX_2LSB_025;
SIG_GROUP_ 1027 RR_Detection_026 1 : RR_CAN_DET_ELEVATION_026 RR_CAN_DET_CONFID_AZIMUTH_026 RR_CAN_DET_SUPER_RES_TARGET_026 RR_CAN_DET_CONFID_ELEVATION_026 RR_CAN_DET_HOST_VEH_CLUTTER_026 RR_CAN_DET_VALID_LEVEL_026 RR_CAN_DET_AZIMUTH_026 RR_CAN_DET_RANGE_026 RR_CAN_DET_RANGE_RATE_026 RR_CAN_DET_AMPLITUDE_026 RR_CAN_SCAN_INDEX_2LSB_026;
SIG_GROUP_ 1027 RR_Detection_027 1 : RR_CAN_DET_ELEVATION_027 RR_CAN_DET_CONFID_AZIMUTH_027 RR_CAN_DET_SUPER_RES_TARGET_027 RR_CAN_DET_CONFID_ELEVATION_027 RR_CAN_DET_HOST_VEH_CLUTTER_027 RR_CAN_DET_VALID_LEVEL_027 RR_CAN_DET_AZIMUTH_027 RR_CAN_DET_RANGE_027 RR_CAN_DET_RANGE_RATE_027 RR_CAN_DET_AMPLITUDE_027 RR_CAN_SCAN_INDEX_2LSB_027;
SIG_GROUP_ 1027 RR_Detection_028 1 : RR_CAN_DET_ELEVATION_028 RR_CAN_DET_CONFID_AZIMUTH_028 RR_CAN_DET_SUPER_RES_TARGET_028 RR_CAN_DET_CONFID_ELEVATION_028 RR_CAN_DET_HOST_VEH_CLUTTER_028 RR_CAN_DET_VALID_LEVEL_028 RR_CAN_DET_AZIMUTH_028 RR_CAN_DET_RANGE_028 RR_CAN_DET_RANGE_RATE_028 RR_CAN_DET_AMPLITUDE_028 RR_CAN_SCAN_INDEX_2LSB_028;
SIG_GROUP_ 1028 RR_Detection_029 1 : RR_CAN_DET_ELEVATION_029 RR_CAN_DET_CONFID_AZIMUTH_029 RR_CAN_DET_SUPER_RES_TARGET_029 RR_CAN_DET_CONFID_ELEVATION_029 RR_CAN_DET_HOST_VEH_CLUTTER_029 RR_CAN_DET_VALID_LEVEL_029 RR_CAN_DET_AZIMUTH_029 RR_CAN_DET_RANGE_029 RR_CAN_DET_RANGE_RATE_029 RR_CAN_DET_AMPLITUDE_029 RR_CAN_SCAN_INDEX_2LSB_029;
SIG_GROUP_ 1028 RR_Detection_030 1 : RR_CAN_DET_ELEVATION_030 RR_CAN_DET_CONFID_AZIMUTH_030 RR_CAN_DET_SUPER_RES_TARGET_030 RR_CAN_DET_CONFID_ELEVATION_030 RR_CAN_DET_HOST_VEH_CLUTTER_030 RR_CAN_DET_VALID_LEVEL_030 RR_CAN_DET_AZIMUTH_030 RR_CAN_DET_RANGE_030 RR_CAN_DET_RANGE_RATE_030 RR_CAN_DET_AMPLITUDE_030 RR_CAN_SCAN_INDEX_2LSB_030;
SIG_GROUP_ 1028 RR_Detection_031 1 : RR_CAN_DET_ELEVATION_031 RR_CAN_DET_CONFID_AZIMUTH_031 RR_CAN_DET_SUPER_RES_TARGET_031 RR_CAN_DET_CONFID_ELEVATION_031 RR_CAN_DET_HOST_VEH_CLUTTER_031 RR_CAN_DET_VALID_LEVEL_031 RR_CAN_DET_AZIMUTH_031 RR_CAN_DET_RANGE_031 RR_CAN_DET_RANGE_RATE_031 RR_CAN_DET_AMPLITUDE_031 RR_CAN_SCAN_INDEX_2LSB_031;
SIG_GROUP_ 1028 RR_Detection_032 1 : RR_CAN_DET_ELEVATION_032 RR_CAN_DET_CONFID_AZIMUTH_032 RR_CAN_DET_SUPER_RES_TARGET_032 RR_CAN_DET_CONFID_ELEVATION_032 RR_CAN_DET_HOST_VEH_CLUTTER_032 RR_CAN_DET_VALID_LEVEL_032 RR_CAN_DET_AZIMUTH_032 RR_CAN_DET_RANGE_032 RR_CAN_DET_RANGE_RATE_032 RR_CAN_DET_AMPLITUDE_032 RR_CAN_SCAN_INDEX_2LSB_032;
SIG_GROUP_ 1028 RR_Detection_033 1 : RR_CAN_DET_ELEVATION_033 RR_CAN_DET_CONFID_AZIMUTH_033 RR_CAN_DET_SUPER_RES_TARGET_033 RR_CAN_DET_CONFID_ELEVATION_033 RR_CAN_DET_HOST_VEH_CLUTTER_033 RR_CAN_DET_VALID_LEVEL_033 RR_CAN_DET_AZIMUTH_033 RR_CAN_DET_RANGE_033 RR_CAN_DET_RANGE_RATE_033 RR_CAN_DET_AMPLITUDE_033 RR_CAN_SCAN_INDEX_2LSB_033;
SIG_GROUP_ 1028 RR_Detection_034 1 : RR_CAN_DET_ELEVATION_034 RR_CAN_DET_CONFID_AZIMUTH_034 RR_CAN_DET_SUPER_RES_TARGET_034 RR_CAN_DET_CONFID_ELEVATION_034 RR_CAN_DET_HOST_VEH_CLUTTER_034 RR_CAN_DET_VALID_LEVEL_034 RR_CAN_DET_AZIMUTH_034 RR_CAN_DET_RANGE_034 RR_CAN_DET_RANGE_RATE_034 RR_CAN_DET_AMPLITUDE_034 RR_CAN_SCAN_INDEX_2LSB_034;
SIG_GROUP_ 1028 RR_Detection_035 1 : RR_CAN_DET_ELEVATION_035 RR_CAN_DET_CONFID_AZIMUTH_035 RR_CAN_DET_SUPER_RES_TARGET_035 RR_CAN_DET_CONFID_ELEVATION_035 RR_CAN_DET_HOST_VEH_CLUTTER_035 RR_CAN_DET_VALID_LEVEL_035 RR_CAN_DET_AZIMUTH_035 RR_CAN_DET_RANGE_035 RR_CAN_DET_RANGE_RATE_035 RR_CAN_DET_AMPLITUDE_035 RR_CAN_SCAN_INDEX_2LSB_035;
SIG_GROUP_ 1029 RR_Detection_036 1 : RR_CAN_DET_ELEVATION_036 RR_CAN_DET_CONFID_AZIMUTH_036 RR_CAN_DET_SUPER_RES_TARGET_036 RR_CAN_DET_CONFID_ELEVATION_036 RR_CAN_DET_HOST_VEH_CLUTTER_036 RR_CAN_DET_VALID_LEVEL_036 RR_CAN_DET_AZIMUTH_036 RR_CAN_DET_RANGE_036 RR_CAN_DET_RANGE_RATE_036 RR_CAN_DET_AMPLITUDE_036 RR_CAN_SCAN_INDEX_2LSB_036;
SIG_GROUP_ 1029 RR_Detection_037 1 : RR_CAN_DET_ELEVATION_037 RR_CAN_DET_CONFID_AZIMUTH_037 RR_CAN_DET_SUPER_RES_TARGET_037 RR_CAN_DET_CONFID_ELEVATION_037 RR_CAN_DET_HOST_VEH_CLUTTER_037 RR_CAN_DET_VALID_LEVEL_037 RR_CAN_DET_AZIMUTH_037 RR_CAN_DET_RANGE_037 RR_CAN_DET_RANGE_RATE_037 RR_CAN_DET_AMPLITUDE_037 RR_CAN_SCAN_INDEX_2LSB_037;
SIG_GROUP_ 1029 RR_Detection_038 1 : RR_CAN_DET_ELEVATION_038 RR_CAN_DET_CONFID_AZIMUTH_038 RR_CAN_DET_SUPER_RES_TARGET_038 RR_CAN_DET_CONFID_ELEVATION_038 RR_CAN_DET_HOST_VEH_CLUTTER_038 RR_CAN_DET_VALID_LEVEL_038 RR_CAN_DET_AZIMUTH_038 RR_CAN_DET_RANGE_038 RR_CAN_DET_RANGE_RATE_038 RR_CAN_DET_AMPLITUDE_038 RR_CAN_SCAN_INDEX_2LSB_038;
SIG_GROUP_ 1029 RR_Detection_039 1 : RR_CAN_DET_ELEVATION_039 RR_CAN_DET_CONFID_AZIMUTH_039 RR_CAN_DET_SUPER_RES_TARGET_039 RR_CAN_DET_CONFID_ELEVATION_039 RR_CAN_DET_HOST_VEH_CLUTTER_039 RR_CAN_DET_VALID_LEVEL_039 RR_CAN_DET_AZIMUTH_039 RR_CAN_DET_RANGE_039 RR_CAN_DET_RANGE_RATE_039 RR_CAN_DET_AMPLITUDE_039 RR_CAN_SCAN_INDEX_2LSB_039;
SIG_GROUP_ 1029 RR_Detection_040 1 : RR_CAN_DET_ELEVATION_040 RR_CAN_DET_CONFID_AZIMUTH_040 RR_CAN_DET_SUPER_RES_TARGET_040 RR_CAN_DET_CONFID_ELEVATION_040 RR_CAN_DET_HOST_VEH_CLUTTER_040 RR_CAN_DET_VALID_LEVEL_040 RR_CAN_DET_AZIMUTH_040 RR_CAN_DET_RANGE_040 RR_CAN_DET_RANGE_RATE_040 RR_CAN_DET_AMPLITUDE_040 RR_CAN_SCAN_INDEX_2LSB_040;
SIG_GROUP_ 1029 RR_Detection_041 1 : RR_CAN_DET_ELEVATION_041 RR_CAN_DET_CONFID_AZIMUTH_041 RR_CAN_DET_SUPER_RES_TARGET_041 RR_CAN_DET_CONFID_ELEVATION_041 RR_CAN_DET_HOST_VEH_CLUTTER_041 RR_CAN_DET_VALID_LEVEL_041 RR_CAN_DET_AZIMUTH_041 RR_CAN_DET_RANGE_041 RR_CAN_DET_RANGE_RATE_041 RR_CAN_DET_AMPLITUDE_041 RR_CAN_SCAN_INDEX_2LSB_041;
SIG_GROUP_ 1029 RR_Detection_042 1 : RR_CAN_DET_ELEVATION_042 RR_CAN_DET_CONFID_AZIMUTH_042 RR_CAN_DET_SUPER_RES_TARGET_042 RR_CAN_DET_CONFID_ELEVATION_042 RR_CAN_DET_HOST_VEH_CLUTTER_042 RR_CAN_DET_VALID_LEVEL_042 RR_CAN_DET_AZIMUTH_042 RR_CAN_DET_RANGE_042 RR_CAN_DET_RANGE_RATE_042 RR_CAN_DET_AMPLITUDE_042 RR_CAN_SCAN_INDEX_2LSB_042;
SIG_GROUP_ 1030 RR_Detection_043 1 : RR_CAN_DET_ELEVATION_043 RR_CAN_DET_CONFID_AZIMUTH_043 RR_CAN_DET_SUPER_RES_TARGET_043 RR_CAN_DET_CONFID_ELEVATION_043 RR_CAN_DET_HOST_VEH_CLUTTER_043 RR_CAN_DET_VALID_LEVEL_043 RR_CAN_DET_AZIMUTH_043 RR_CAN_DET_RANGE_043 RR_CAN_DET_RANGE_RATE_043 RR_CAN_DET_AMPLITUDE_043 RR_CAN_SCAN_INDEX_2LSB_043;
SIG_GROUP_ 1030 RR_Detection_044 1 : RR_CAN_DET_ELEVATION_044 RR_CAN_DET_CONFID_AZIMUTH_044 RR_CAN_DET_SUPER_RES_TARGET_044 RR_CAN_DET_CONFID_ELEVATION_044 RR_CAN_DET_HOST_VEH_CLUTTER_044 RR_CAN_DET_VALID_LEVEL_044 RR_CAN_DET_AZIMUTH_044 RR_CAN_DET_RANGE_044 RR_CAN_DET_RANGE_RATE_044 RR_CAN_DET_AMPLITUDE_044 RR_CAN_SCAN_INDEX_2LSB_044;
SIG_GROUP_ 1030 RR_Detection_045 1 : RR_CAN_DET_ELEVATION_045 RR_CAN_DET_CONFID_AZIMUTH_045 RR_CAN_DET_SUPER_RES_TARGET_045 RR_CAN_DET_CONFID_ELEVATION_045 RR_CAN_DET_HOST_VEH_CLUTTER_045 RR_CAN_DET_VALID_LEVEL_045 RR_CAN_DET_AZIMUTH_045 RR_CAN_DET_RANGE_045 RR_CAN_DET_RANGE_RATE_045 RR_CAN_DET_AMPLITUDE_045 RR_CAN_SCAN_INDEX_2LSB_045;
SIG_GROUP_ 1030 RR_Detection_046 1 : RR_CAN_DET_ELEVATION_046 RR_CAN_DET_CONFID_AZIMUTH_046 RR_CAN_DET_SUPER_RES_TARGET_046 RR_CAN_DET_CONFID_ELEVATION_046 RR_CAN_DET_HOST_VEH_CLUTTER_046 RR_CAN_DET_VALID_LEVEL_046 RR_CAN_DET_AZIMUTH_046 RR_CAN_DET_RANGE_046 RR_CAN_DET_RANGE_RATE_046 RR_CAN_DET_AMPLITUDE_046 RR_CAN_SCAN_INDEX_2LSB_046;
SIG_GROUP_ 1030 RR_Detection_047 1 : RR_CAN_DET_ELEVATION_047 RR_CAN_DET_CONFID_AZIMUTH_047 RR_CAN_DET_SUPER_RES_TARGET_047 RR_CAN_DET_CONFID_ELEVATION_047 RR_CAN_DET_HOST_VEH_CLUTTER_047 RR_CAN_DET_VALID_LEVEL_047 RR_CAN_DET_AZIMUTH_047 RR_CAN_DET_RANGE_047 RR_CAN_DET_RANGE_RATE_047 RR_CAN_DET_AMPLITUDE_047 RR_CAN_SCAN_INDEX_2LSB_047;
SIG_GROUP_ 1030 RR_Detection_048 1 : RR_CAN_DET_ELEVATION_048 RR_CAN_DET_CONFID_AZIMUTH_048 RR_CAN_DET_SUPER_RES_TARGET_048 RR_CAN_DET_CONFID_ELEVATION_048 RR_CAN_DET_HOST_VEH_CLUTTER_048 RR_CAN_DET_VALID_LEVEL_048 RR_CAN_DET_AZIMUTH_048 RR_CAN_DET_RANGE_048 RR_CAN_DET_RANGE_RATE_048 RR_CAN_DET_AMPLITUDE_048 RR_CAN_SCAN_INDEX_2LSB_048;
SIG_GROUP_ 1030 RR_Detection_049 1 : RR_CAN_DET_ELEVATION_049 RR_CAN_DET_CONFID_AZIMUTH_049 RR_CAN_DET_SUPER_RES_TARGET_049 RR_CAN_DET_CONFID_ELEVATION_049 RR_CAN_DET_HOST_VEH_CLUTTER_049 RR_CAN_DET_VALID_LEVEL_049 RR_CAN_DET_AZIMUTH_049 RR_CAN_DET_RANGE_049 RR_CAN_DET_RANGE_RATE_049 RR_CAN_DET_AMPLITUDE_049 RR_CAN_SCAN_INDEX_2LSB_049;
SIG_GROUP_ 1031 RR_Detection_050 1 : RR_CAN_DET_ELEVATION_050 RR_CAN_DET_CONFID_AZIMUTH_050 RR_CAN_DET_SUPER_RES_TARGET_050 RR_CAN_DET_CONFID_ELEVATION_050 RR_CAN_DET_HOST_VEH_CLUTTER_050 RR_CAN_DET_VALID_LEVEL_050 RR_CAN_DET_AZIMUTH_050 RR_CAN_DET_RANGE_050 RR_CAN_DET_RANGE_RATE_050 RR_CAN_DET_AMPLITUDE_050 RR_CAN_SCAN_INDEX_2LSB_050;
SIG_GROUP_ 1031 RR_Detection_051 1 : RR_CAN_DET_ELEVATION_051 RR_CAN_DET_CONFID_AZIMUTH_051 RR_CAN_DET_SUPER_RES_TARGET_051 RR_CAN_DET_CONFID_ELEVATION_051 RR_CAN_DET_HOST_VEH_CLUTTER_051 RR_CAN_DET_VALID_LEVEL_051 RR_CAN_DET_AZIMUTH_051 RR_CAN_DET_RANGE_051 RR_CAN_DET_RANGE_RATE_051 RR_CAN_DET_AMPLITUDE_051 RR_CAN_SCAN_INDEX_2LSB_051;
SIG_GROUP_ 1031 RR_Detection_052 1 : RR_CAN_DET_ELEVATION_052 RR_CAN_DET_CONFID_AZIMUTH_052 RR_CAN_DET_SUPER_RES_TARGET_052 RR_CAN_DET_CONFID_ELEVATION_052 RR_CAN_DET_HOST_VEH_CLUTTER_052 RR_CAN_DET_VALID_LEVEL_052 RR_CAN_DET_AZIMUTH_052 RR_CAN_DET_RANGE_052 RR_CAN_DET_RANGE_RATE_052 RR_CAN_DET_AMPLITUDE_052 RR_CAN_SCAN_INDEX_2LSB_052;
SIG_GROUP_ 1031 RR_Detection_053 1 : RR_CAN_DET_ELEVATION_053 RR_CAN_DET_CONFID_AZIMUTH_053 RR_CAN_DET_SUPER_RES_TARGET_053 RR_CAN_DET_CONFID_ELEVATION_053 RR_CAN_DET_HOST_VEH_CLUTTER_053 RR_CAN_DET_VALID_LEVEL_053 RR_CAN_DET_AZIMUTH_053 RR_CAN_DET_RANGE_053 RR_CAN_DET_RANGE_RATE_053 RR_CAN_DET_AMPLITUDE_053 RR_CAN_SCAN_INDEX_2LSB_053;
SIG_GROUP_ 1031 RR_Detection_054 1 : RR_CAN_DET_ELEVATION_054 RR_CAN_DET_CONFID_AZIMUTH_054 RR_CAN_DET_SUPER_RES_TARGET_054 RR_CAN_DET_CONFID_ELEVATION_054 RR_CAN_DET_HOST_VEH_CLUTTER_054 RR_CAN_DET_VALID_LEVEL_054 RR_CAN_DET_AZIMUTH_054 RR_CAN_DET_RANGE_054 RR_CAN_DET_RANGE_RATE_054 RR_CAN_DET_AMPLITUDE_054 RR_CAN_SCAN_INDEX_2LSB_054;
SIG_GROUP_ 1031 RR_Detection_055 1 : RR_CAN_DET_ELEVATION_055 RR_CAN_DET_CONFID_AZIMUTH_055 RR_CAN_DET_SUPER_RES_TARGET_055 RR_CAN_DET_CONFID_ELEVATION_055 RR_CAN_DET_HOST_VEH_CLUTTER_055 RR_CAN_DET_VALID_LEVEL_055 RR_CAN_DET_AZIMUTH_055 RR_CAN_DET_RANGE_055 RR_CAN_DET_RANGE_RATE_055 RR_CAN_DET_AMPLITUDE_055 RR_CAN_SCAN_INDEX_2LSB_055;
SIG_GROUP_ 1031 RR_Detection_056 1 : RR_CAN_DET_ELEVATION_056 RR_CAN_DET_CONFID_AZIMUTH_056 RR_CAN_DET_SUPER_RES_TARGET_056 RR_CAN_DET_CONFID_ELEVATION_056 RR_CAN_DET_HOST_VEH_CLUTTER_056 RR_CAN_DET_VALID_LEVEL_056 RR_CAN_DET_AZIMUTH_056 RR_CAN_DET_RANGE_056 RR_CAN_DET_RANGE_RATE_056 RR_CAN_DET_AMPLITUDE_056 RR_CAN_SCAN_INDEX_2LSB_056;
SIG_GROUP_ 1032 RR_Detection_057 1 : RR_CAN_DET_ELEVATION_057 RR_CAN_DET_CONFID_AZIMUTH_057 RR_CAN_DET_SUPER_RES_TARGET_057 RR_CAN_DET_CONFID_ELEVATION_057 RR_CAN_DET_HOST_VEH_CLUTTER_057 RR_CAN_DET_VALID_LEVEL_057 RR_CAN_DET_AZIMUTH_057 RR_CAN_DET_RANGE_057 RR_CAN_DET_RANGE_RATE_057 RR_CAN_DET_AMPLITUDE_057 RR_CAN_SCAN_INDEX_2LSB_057;
SIG_GROUP_ 1032 RR_Detection_058 1 : RR_CAN_DET_ELEVATION_058 RR_CAN_DET_CONFID_AZIMUTH_058 RR_CAN_DET_SUPER_RES_TARGET_058 RR_CAN_DET_CONFID_ELEVATION_058 RR_CAN_DET_HOST_VEH_CLUTTER_058 RR_CAN_DET_VALID_LEVEL_058 RR_CAN_DET_AZIMUTH_058 RR_CAN_DET_RANGE_058 RR_CAN_DET_RANGE_RATE_058 RR_CAN_DET_AMPLITUDE_058 RR_CAN_SCAN_INDEX_2LSB_058;
SIG_GROUP_ 1032 RR_Detection_059 1 : RR_CAN_DET_ELEVATION_059 RR_CAN_DET_CONFID_AZIMUTH_059 RR_CAN_DET_SUPER_RES_TARGET_059 RR_CAN_DET_CONFID_ELEVATION_059 RR_CAN_DET_HOST_VEH_CLUTTER_059 RR_CAN_DET_VALID_LEVEL_059 RR_CAN_DET_AZIMUTH_059 RR_CAN_DET_RANGE_059 RR_CAN_DET_RANGE_RATE_059 RR_CAN_DET_AMPLITUDE_059 RR_CAN_SCAN_INDEX_2LSB_059;
SIG_GROUP_ 1032 RR_Detection_060 1 : RR_CAN_DET_ELEVATION_060 RR_CAN_DET_CONFID_AZIMUTH_060 RR_CAN_DET_SUPER_RES_TARGET_060 RR_CAN_DET_CONFID_ELEVATION_060 RR_CAN_DET_HOST_VEH_CLUTTER_060 RR_CAN_DET_VALID_LEVEL_060 RR_CAN_DET_AZIMUTH_060 RR_CAN_DET_RANGE_060 RR_CAN_DET_RANGE_RATE_060 RR_CAN_DET_AMPLITUDE_060 RR_CAN_SCAN_INDEX_2LSB_060;
SIG_GROUP_ 1032 RR_Detection_061 1 : RR_CAN_DET_ELEVATION_061 RR_CAN_DET_CONFID_AZIMUTH_061 RR_CAN_DET_SUPER_RES_TARGET_061 RR_CAN_DET_CONFID_ELEVATION_061 RR_CAN_DET_HOST_VEH_CLUTTER_061 RR_CAN_DET_VALID_LEVEL_061 RR_CAN_DET_AZIMUTH_061 RR_CAN_DET_RANGE_061 RR_CAN_DET_RANGE_RATE_061 RR_CAN_DET_AMPLITUDE_061 RR_CAN_SCAN_INDEX_2LSB_061;
SIG_GROUP_ 1032 RR_Detection_062 1 : RR_CAN_DET_ELEVATION_062 RR_CAN_DET_CONFID_AZIMUTH_062 RR_CAN_DET_SUPER_RES_TARGET_062 RR_CAN_DET_CONFID_ELEVATION_062 RR_CAN_DET_HOST_VEH_CLUTTER_062 RR_CAN_DET_VALID_LEVEL_062 RR_CAN_DET_AZIMUTH_062 RR_CAN_DET_RANGE_062 RR_CAN_DET_RANGE_RATE_062 RR_CAN_DET_AMPLITUDE_062 RR_CAN_SCAN_INDEX_2LSB_062;
SIG_GROUP_ 1032 RR_Detection_063 1 : RR_CAN_DET_ELEVATION_063 RR_CAN_DET_CONFID_AZIMUTH_063 RR_CAN_DET_SUPER_RES_TARGET_063 RR_CAN_DET_CONFID_ELEVATION_063 RR_CAN_DET_HOST_VEH_CLUTTER_063 RR_CAN_DET_VALID_LEVEL_063 RR_CAN_DET_AZIMUTH_063 RR_CAN_DET_RANGE_063 RR_CAN_DET_RANGE_RATE_063 RR_CAN_DET_AMPLITUDE_063 RR_CAN_SCAN_INDEX_2LSB_063;
SIG_GROUP_ 1033 RR_Detection_064 1 : RR_CAN_DET_ELEVATION_064 RR_CAN_DET_CONFID_AZIMUTH_064 RR_CAN_DET_SUPER_RES_TARGET_064 RR_CAN_DET_CONFID_ELEVATION_064 RR_CAN_DET_HOST_VEH_CLUTTER_064 RR_CAN_DET_VALID_LEVEL_064 RR_CAN_DET_AZIMUTH_064 RR_CAN_DET_RANGE_064 RR_CAN_DET_RANGE_RATE_064 RR_CAN_DET_AMPLITUDE_064 RR_CAN_SCAN_INDEX_2LSB_064;
